VERSION "created by canmatrix"

NS_ :

BS_:

BU_: IPD

BO_ 1010 ICBVC_BKPCANFD_50ms_FrP13: 16 Vector__XXX
 SG_ IThreeDimnlDspReq : 15|2@0+ (1,0) [0|3] "null" IPD
 SG_ ISysFltRsn : 23|3@0+ (1,0) [0|7] "null" IPD
 SG_ IErrRespHODM : 24|1@0+ (1,0) [0|1] "null" IPD
 SG_ ISWSCnfmSwReq : 26|2@0+ (1,0) [0|3] "null" IPD
 SG_ IMirFoldCtrlResp : 31|3@0+ (1,0) [0|7] "null" IPD
 SG_ ITgtParkingChosed : 35|4@0+ (1,0) [0|15] "null" IPD
 SG_ ISpdLmtMdFICM : 37|2@0+ (1,0) [0|3] "null" IPD
 SG_ IAutocParkngSwReq : 39|2@0+ (1,0) [0|3] "null" IPD
 SG_ IIMATESysSts : 42|3@0+ (1,0) [0|7] "null" IPD
 SG_ ILampCtrlResp : 47|4@0+ (1,0) [0|15] "null" IPD
 SG_ IPwrMdCtrlResp : 58|3@0+ (1,0) [0|7] "null" IPD
 SG_ ILVSSts : 90|2@0+ (1,0) [0|3] "null" Vector__XXX
 SG_ IFrSsdManuCtrl : 92|2@0+ (1,0) [0|3] "null" Vector__XXX
 SG_ IPwrCtrlResp : 95|3@0+ (1,0) [0|7] "null" IPD

BO_ 591 ICBVC_BKPCANFD_50ms_FrP55: 12 Vector__XXX
 SG_ IDrvrFtgLvl : 15|3@0+ (1,0) [0|7] "null" IPD
 SG_ IDrvrPrsc : 23|3@0+ (1,0) [0|7] "null" IPD
 SG_ IIMATEysSts : 26|3@0+ (1,0) [0|7] "null" IPD
 SG_ IDrvrDstrctnSts : 31|3@0+ (1,0) [0|7] "null" IPD
 SG_ IDrvrAbnormBehvor : 39|4@0+ (1,0) [0|15] "null" IPD
 SG_ IDrvrGazeRgn : 47|5@0+ (1,0) [0|31] "null" IPD

BO_ 1301 ICBVC_BKPCANFD_Event_FrS06: 8 Vector__XXX
 SG_ IScurReqADS : 7|64@0+ (1,0) [0|18446744073709551615] "null" IPD

BO_ 1302 ICBVC_BKPCANFD_Event_FrS07: 8 Vector__XXX
 SG_ IDrvngScurResp : 7|64@0+ (1,0) [0|18446744073709551615] "null" IPD

BO_ 728 ICBVC_BKPCANFD_Event_FrS138: 24 Vector__XXX
 SG_ IParkingSubscribleStsreq : 39|64@0+ (1,0) [0|18446744073709551615] "null" IPD
 SG_ IPilotSubscribleStsreq : 103|64@0+ (1,0) [0|18446744073709551615] "null" IPD
 SG_ IAIParkngSpcIDICB : 167|8@0+ (1,0) [0|255] "null" IPD
 SG_ IRemParkngMapChosen : 175|8@0+ (1,0) [0|255] "null" IPD
 SG_ IAIParkngReqICB : 183|8@0+ (1,0) [0|255] "null" IPD
 SG_ IAIParkngScngAutocBtn : 191|4@0+ (1,0) [0|15] "null" IPD

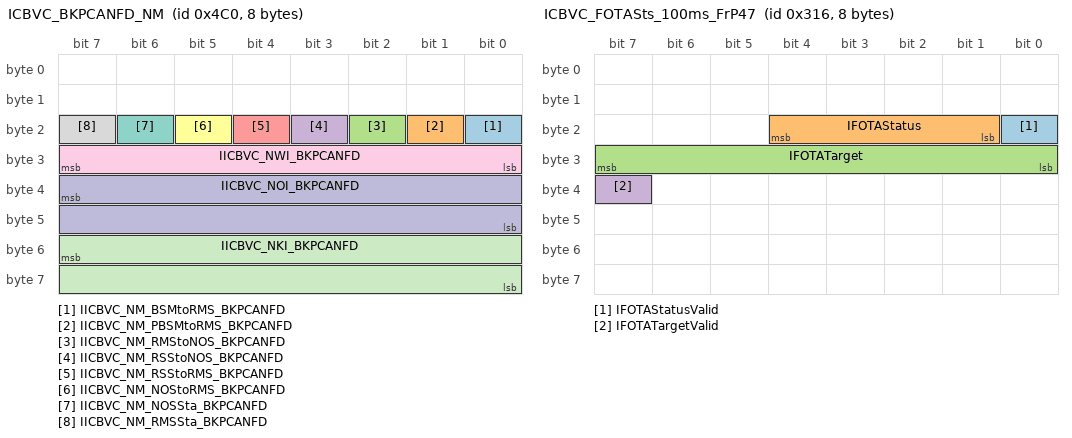
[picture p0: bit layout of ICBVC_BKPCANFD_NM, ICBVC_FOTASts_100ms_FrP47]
BO_ 1216 ICBVC_BKPCANFD_NM: 8 Vector__XXX
 SG_ IICBVC_NM_BSMtoRMS_BKPCANFD : 16|1@0+ (1,0) [0|1] "null" Vector__XXX
 SG_ IICBVC_NM_PBSMtoRMS_BKPCANFD : 17|1@0+ (1,0) [0|1] "null" Vector__XXX
 SG_ IICBVC_NM_RMStoNOS_BKPCANFD : 18|1@0+ (1,0) [0|1] "null" Vector__XXX
 SG_ IICBVC_NM_RSStoNOS_BKPCANFD : 19|1@0+ (1,0) [0|1] "null" Vector__XXX
 SG_ IICBVC_NM_RSStoRMS_BKPCANFD : 20|1@0+ (1,0) [0|1] "null" Vector__XXX
 SG_ IICBVC_NM_NOStoRMS_BKPCANFD : 21|1@0+ (1,0) [0|1] "null" Vector__XXX
 SG_ IICBVC_NM_NOSSta_BKPCANFD : 22|1@0+ (1,0) [0|1] "null" Vector__XXX
 SG_ IICBVC_NM_RMSSta_BKPCANFD : 23|1@0+ (1,0) [0|1] "null" Vector__XXX
 SG_ IICBVC_NWI_BKPCANFD : 31|8@0+ (1,0) [0|255] "null" Vector__XXX
 SG_ IICBVC_NOI_BKPCANFD : 39|16@0+ (1,0) [0|65535] "null" Vector__XXX
 SG_ IICBVC_NKI_BKPCANFD : 55|16@0+ (1,0) [0|65535] "null" Vector__XXX

BO_ 790 ICBVC_FOTASts_100ms_FrP47: 8 Vector__XXX
 SG_ IFOTAStatusValid : 16|1@0+ (1,0) [0|1] "null" IPD
 SG_ IFOTAStatus : 20|4@0+ (1,0) [0|15] "null" IPD
 SG_ IFOTATarget : 31|8@0+ (1,0) [0|255] "null" IPD
 SG_ IFOTATargetValid : 39|1@0+ (1,0) [0|1] "null" IPD

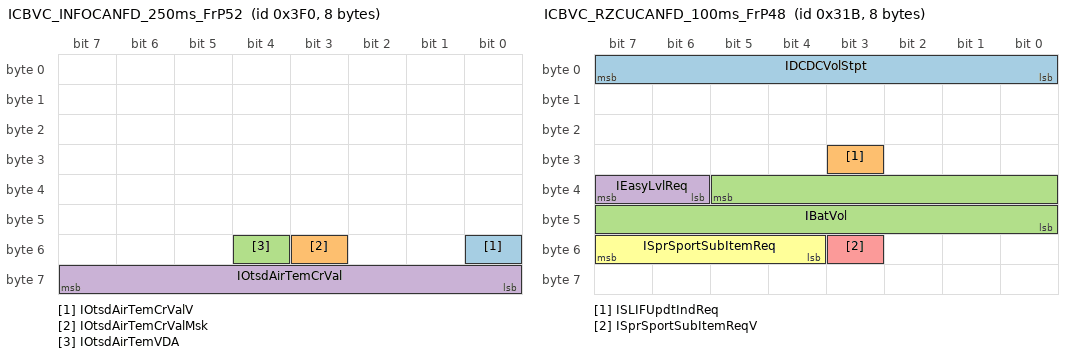
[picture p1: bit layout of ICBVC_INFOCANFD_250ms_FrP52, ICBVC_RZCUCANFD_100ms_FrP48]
BO_ 1008 ICBVC_INFOCANFD_250ms_FrP52: 8 Vector__XXX
 SG_ IOtsdAirTemCrValV : 48|1@0+ (1,0) [0|1] "null" IPD
 SG_ IOtsdAirTemCrValMsk : 51|1@0+ (1,0) [0|1] "null" IPD
 SG_ IOtsdAirTemVDA : 52|1@0+ (1,0) [0|1] "null" Vector__XXX
 SG_ IOtsdAirTemCrVal : 63|8@0+ (0.5,-40) [-40|87.5] "degreeCelsius" IPD

BO_ 1023 ICBVC_RZCUCANFD_100ms_FrP19: 8 Vector__XXX
 SG_ IRgnLvReqFICMV : 12|1@0+ (1,0) [0|1] "null" Vector__XXX
 SG_ IRgnLvReqFICM : 15|3@0+ (1,0) [0|7] "null" Vector__XXX
 SG_ ILVBatChrgReqRaw : 16|1@0+ (1,0) [0|1] "null" Vector__XXX
 SG_ ILVBatChrgReqInhbt : 17|1@0+ (1,0) [0|1] "null" Vector__XXX
 SG_ ILVBatEnrgSufct : 18|1@0+ (1,0) [0|1] "null" Vector__XXX
 SG_ ILVBatEnrgLow : 19|1@0+ (1,0) [0|1] "null" Vector__XXX
 SG_ IVehFOTAHVReq : 21|2@0+ (1,0) [0|3] "null" Vector__XXX
 SG_ IEnrgSplReqV : 22|1@0+ (1,0) [0|1] "null" Vector__XXX
 SG_ IEnrgSplReq : 23|1@0+ (1,0) [0|1] "null" Vector__XXX
 SG_ IPMDCSta : 27|4@0+ (1,0) [0|15] "null" Vector__XXX
 SG_ IEPMOprtMd : 31|4@0+ (1,0) [0|15] "null" Vector__XXX
 SG_ IVehFotaReq : 32|1@0+ (1,0) [0|1] "null" Vector__XXX
 SG_ IVehEnrgRdyLvlV : 36|1@0+ (1,0) [0|1] "null" IPD
 SG_ IVehEnrgRdyLvl : 39|3@0+ (1,0) [0|7] "null" IPD
 SG_ IEPTToqCustSetngReqV : 59|1@0+ (1,0) [0|1] "null" Vector__XXX
 SG_ IEPTToqCustSetngReq : 61|2@0+ (1,0) [0|3] "null" Vector__XXX
 SG_ ILVBatSelfWakeupFlg : 62|1@0+ (1,0) [0|1] "null" Vector__XXX
 SG_ IEnrgSplReqRaw : 63|1@0+ (1,0) [0|1] "null" Vector__XXX

BO_ 922 ICBVC_RZCUCANFD_100ms_FrP27: 8 Vector__XXX
 SG_ IAVMDspReq : 1|2@0+ (1,0) [0|3] "null" IPD
 SG_ IAutoViewChg : 2|1@0+ (1,0) [0|1] "null" IPD
 SG_ IAlisysrdy : 3|1@0+ (1,0) [0|1] "null" IPD
 SG_ ILiftMdReq : 5|2@0+ (1,0) [0|3] "null" Vector__XXX
 SG_ IEasyLdMdReq : 7|2@0+ (1,0) [0|3] "null" Vector__XXX
 SG_ IEasyEntMdReq : 9|2@0+ (1,0) [0|3] "null" Vector__XXX
 SG_ IEasyPssReq : 11|2@0+ (1,0) [0|3] "null" Vector__XXX
 SG_ IIEasyEntMdSetReq : 13|2@0+ (1,0) [0|3] "null" Vector__XXX
 SG_ IHDCReq : 15|2@0+ (1,0) [0|3] "null" Vector__XXX
 SG_ IEmmsnTestMdFICMV : 16|1@0+ (1,0) [0|1] "null" Vector__XXX
 SG_ ITrgtSOCReqFICM : 23|7@0+ (1,0) [0|127] "null" Vector__XXX
 SG_ ISusLvlCtrlCustSetngReq : 28|3@0+ (1,0) [0|7] "null" Vector__XXX
 SG_ IFICMPwrDMdReq : 31|3@0+ (1,0) [0|7] "null" Vector__XXX
 SG_ ICloseCalib : 35|4@0+ (1,0) [0|15] "null" IPD
 SG_ ICalibFunc : 39|4@0+ (1,0) [0|15] "null" IPD
 SG_ IFICMPwrDMdReqV : 40|1@0+ (1,0) [0|1] "null" Vector__XXX
 SG_ IEmmsnTestMdFICM : 41|1@0+ (1,0) [0|1] "null" Vector__XXX
 SG_ IVehSpdDpdntLvlCtrlReq : 43|2@0+ (1,0) [0|3] "m/s" Vector__XXX
 SG_ IBtmFilgDspReq : 47|2@0+ (1,0) [0|3] "null" IPD
 SG_ ISusDmpngCtrlCustSetngReq : 54|4@0+ (1,0) [0|15] "null" Vector__XXX
 SG_ ITrgtSOCReqFICMV : 55|1@0+ (1,0) [0|1] "null" Vector__XXX

BO_ 1006 ICBVC_RZCUCANFD_100ms_FrP44: 16 Vector__XXX
 SG_ INavGudcSts : 3|1@0+ (1,0) [0|1] "null" Vector__XXX
 SG_ IDsttnTypOfNav : 7|4@0+ (1,0) [0|15] "null" Vector__XXX
 SG_ IEPTSysCoolActvReq : 10|1@0+ (1,0) [0|1] "null" Vector__XXX
 SG_ IChrgngSttnCapctOfDsttnNav : 31|8@0+ (4,0) [0|1020] "kW" Vector__XXX
 SG_ IDistToDsttnNav : 43|10@0+ (0.1,0) [0|102.3] "km" IPD
 SG_ IElecEnrgAvgRstReq : 65|2@0+ (1,0) [0|3] "null" Vector__XXX
 SG_ IFICMOnRutWarmOffReqV : 66|1@0+ (1,0) [0|1] "null" Vector__XXX
 SG_ IFICMChrgCtrlReq : 68|2@0+ (1,0) [0|3] "null" Vector__XXX
 SG_ IFICMOnRouteWarmSwReq : 69|1@0+ (1,0) [0|1] "null" Vector__XXX
 SG_ IFICMOnRutWarmOffReq : 71|2@0+ (1,0) [0|3] "null" Vector__XXX
 SG_ IIPKSetVehEleclRngAlg : 74|1@0+ (1,0) [0|1] "null" Vector__XXX
 SG_ IFICMV2XReq : 91|2@0+ (1,0) [0|3] "null" Vector__XXX
 SG_ IFICMEleccLckCtrlReq : 95|2@0+ (1,0) [0|3] "null" Vector__XXX
 SG_ IGudTimeToDsttnNav : 103|12@0+ (1,0) [0|4095] "Min" Vector__XXX

BO_ 795 ICBVC_RZCUCANFD_100ms_FrP48: 8 Vector__XXX
 SG_ IDCDCVolStpt : 7|8@0+ (0.03125,8.5) [8.50000|16.46875] "V" Vector__XXX
 SG_ ISLIFUpdtIndReq : 27|1@0+ (1,0) [0|1] "null" IPD
 SG_ IBatVol : 37|14@0+ (0.00097656,3) [3.00000000|18.99898248] "V" Vector__XXX
 SG_ IEasyLvlReq : 39|2@0+ (1,0) [0|3] "null" Vector__XXX
 SG_ ISprSportSubItemReqV : 51|1@0+ (1,0) [0|1] "null" Vector__XXX
 SG_ ISprSportSubItemReq : 55|4@0+ (1,0) [0|15] "null" Vector__XXX

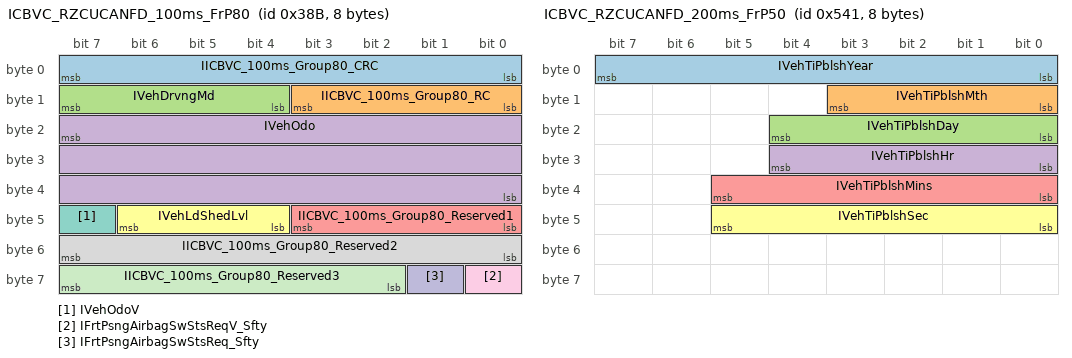
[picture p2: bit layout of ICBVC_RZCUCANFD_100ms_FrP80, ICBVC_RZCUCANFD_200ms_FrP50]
BO_ 907 ICBVC_RZCUCANFD_100ms_FrP80: 8 Vector__XXX
 SG_ IICBVC_100ms_Group80_CRC : 7|8@0+ (1,0) [0|255] "null" IPD
 SG_ IICBVC_100ms_Group80_RC : 11|4@0+ (1,0) [0|15] "null" IPD
 SG_ IVehDrvngMd : 15|4@0+ (1,0) [0|15] "null" IPD
 SG_ IVehOdo : 23|24@0+ (1,0) [0|16777215] "null" IPD
 SG_ IICBVC_100ms_Group80_Reserved1 : 43|4@0+ (1,0) [0|15] "null" IPD
 SG_ IVehLdShedLvl : 46|3@0+ (1,0) [0|7] "null" IPD
 SG_ IVehOdoV : 47|1@0+ (1,0) [0|1] "null" IPD
 SG_ IICBVC_100ms_Group80_Reserved2 : 55|8@0+ (1,0) [0|255] "null" IPD
 SG_ IFrtPsngAirbagSwStsReqV_Sfty : 56|1@0+ (1,0) [0|1] "null" IPD
 SG_ IFrtPsngAirbagSwStsReq_Sfty : 57|1@0+ (1,0) [0|1] "null" IPD
 SG_ IICBVC_100ms_Group80_Reserved3 : 63|6@0+ (1,0) [0|63] "null" IPD

BO_ 1345 ICBVC_RZCUCANFD_200ms_FrP50: 8 Vector__XXX
 SG_ IVehTiPblshYear : 7|8@0+ (1,2000) [2000|2255] "year" IPD
 SG_ IVehTiPblshMth : 11|4@0+ (1,0) [0|15] "null" IPD
 SG_ IVehTiPblshDay : 20|5@0+ (1,0) [0|31] "days" IPD
 SG_ IVehTiPblshHr : 28|5@0+ (1,0) [0|31] "hour" IPD
 SG_ IVehTiPblshMins : 37|6@0+ (1,0) [0|63] "minute" IPD
 SG_ IVehTiPblshSec : 45|6@0+ (1,0) [0|63] "second" IPD

BO_ 361 ICBVC_RZCUCANFD_20ms_FrP00: 8 Vector__XXX
 SG_ INFCAMAvlbly : 2|1@0+ (1,0) [0|1] "null" Vector__XXX
 SG_ ISDMAvlbly : 5|1@0+ (1,0) [0|1] "null" Vector__XXX
 SG_ IRHZCUAvlbly : 6|1@0+ (1,0) [0|1] "null" IPD
 SG_ ILHZCUAvlbly : 7|1@0+ (1,0) [0|1] "null" IPD
 SG_ ITC_ExtdAvlbly : 8|1@0+ (1,0) [0|1] "null" Vector__XXX
 SG_ IIBS_SFAvlbly : 9|1@0+ (1,0) [0|1] "null" Vector__XXX
 SG_ IEPSAvlbly : 10|1@0+ (1,0) [0|1] "null" Vector__XXX
 SG_ ITC_PTAvlbly : 12|1@0+ (1,0) [0|1] "null" Vector__XXX
 SG_ IPICU_PTAvlbly : 13|1@0+ (1,0) [0|1] "null" Vector__XXX
 SG_ IPEU_PTAvlbly : 16|1@0+ (1,0) [0|1] "null" Vector__XXX
 SG_ IPEU_ERAvlbly : 17|1@0+ (1,0) [0|1] "null" Vector__XXX
 SG_ IPICU_ExtdAvlbly : 18|1@0+ (1,0) [0|1] "null" Vector__XXX
 SG_ ILHRDAAvlbly : 19|1@0+ (1,0) [0|1] "null" Vector__XXX
 SG_ IIPD_PTAvlbly : 20|1@0+ (1,0) [0|1] "null" Vector__XXX
 SG_ IESS_PTAvlbly : 22|1@0+ (1,0) [0|1] "null" IPD
 SG_ ICCU_ExtdAvlbly : 23|1@0+ (1,0) [0|1] "null" Vector__XXX
 SG_ IESS_ExtdAvlbly : 24|1@0+ (1,0) [0|1] "null" Vector__XXX
 SG_ ICCU_PTAvlbly : 25|1@0+ (1,0) [0|1] "null" Vector__XXX
 SG_ IIAMAvlbly : 26|1@0+ (1,0) [0|1] "null" IPD
 SG_ IEAC_Avlbly : 27|1@0+ (1,0) [0|1] "null" Vector__XXX
 SG_ IIPD_SFAvlbly : 33|1@0+ (1,0) [0|1] "null" Vector__XXX
 SG_ ICCEOPAvlbly : 38|1@0+ (1,0) [0|1] "null" Vector__XXX
 SG_ IRZCU_BKBCANFDAvlbly : 39|1@0+ (1,0) [0|1] "null" IPD
 SG_ IIPD_BKPCANFDAvlbly : 40|1@0+ (1,0) [0|1] "null" Vector__XXX
 SG_ IIPD_CHCANFDAvlbly : 41|1@0+ (1,0) [0|1] "null" Vector__XXX
 SG_ IIBS_CHAvlbly : 43|1@0+ (1,0) [0|1] "null" Vector__XXX
 SG_ IFDRAvlbly : 44|1@0+ (1,0) [0|1] "null" Vector__XXX
 SG_ IRHRDAAvlbly : 49|1@0+ (1,0) [0|1] "null" Vector__XXX
 SG_ IFVCMAvlbly : 51|1@0+ (1,0) [0|1] "null" Vector__XXX
 SG_ ITPMSAvlbly : 63|1@0+ (1,0) [0|1] "null" Vector__XXX

BO_ 497 ICBVC_RZCUCANFD_20ms_FrP03: 8 Vector__XXX
 SG_ IICBVC_20ms_Group03_CRC : 7|8@0+ (1,0) [0|255] "null" IPD
 SG_ IICBVC_20ms_Group03_RC : 11|4@0+ (1,0) [0|15] "null" IPD
 SG_ IAMRPrtensonReq : 15|4@0+ (1,0) [0|15] "null" IPD
 SG_ IICBVC_20ms_Group03_Reserved2 : 19|4@0+ (1,0) [0|15] "null" IPD
 SG_ ISysVolMdV : 20|1@0+ (1,0) [0|1] "null" IPD
 SG_ IICBVC_20ms_Group03_Reserved1 : 23|3@0+ (1,0) [0|7] "null" IPD
 SG_ IICBVC_20ms_Group03_Reserved3 : 27|4@0+ (1,0) [0|15] "null" IPD
 SG_ IVehMd : 31|4@0+ (1,0) [0|15] "null" IPD
 SG_ ISysVolV : 32|1@0+ (1,0) [0|1] "null" IPD
 SG_ ISysPwrMdV : 33|1@0+ (1,0) [0|1] "null" IPD
 SG_ IVehMdV : 34|1@0+ (1,0) [0|1] "null" IPD
 SG_ IUsgMdV : 35|1@0+ (1,0) [0|1] "null" IPD
 SG_ IUsgMd : 39|4@0+ (1,0) [0|15] "null" IPD
 SG_ ISysVol : 47|8@0+ (0.1,3) [3|28.5] "V" IPD
 SG_ IPwrMdMstrRunCrkA : 48|1@0+ (1,0) [0|1] "null" IPD
 SG_ ISysPwrMd : 50|2@0+ (1,0) [0|3] "null" IPD
 SG_ IPwrMdMstrAccryA : 51|1@0+ (1,0) [0|1] "null" IPD
 SG_ ISysOpnlMd : 55|4@0+ (1,0) [0|15] "null" IPD
 SG_ IICBVC_20ms_Group03_Reserved4 : 60|5@0+ (1,0) [0|31] "null" IPD
 SG_ IBPMMstrAvlbly : 61|1@0+ (1,0) [0|1] "null" IPD
 SG_ ISysVolMd : 63|2@0+ (1,0) [0|3] "null" IPD

BO_ 60 ICBVC_SecOC_ComKeyReq: 8 Vector__XXX
 SG_ ITripCntResetReq : 6|1@0+ (1,0) [0|1] "null" IPD
 SG_ IComKeyEnbReq : 7|1@0+ (1,0) [0|1] "null" IPD

BO_ 1391 ICBVC_SecOC_SyncMsg: 8 Vector__XXX
 SG_ ITripCnt : 7|24@0+ (1,0) [0|16777215] "null" IPD
 SG_ IResetCnt : 31|16@0+ (1,0) [0|65535] "null" IPD

BO_ 815 ICB_BKBCANFD_100ms_FrP146: 8 Vector__XXX
 SG_ IEGCMPwrSts : 16|1@0+ (1,0) [0|1] "null" Vector__XXX
 SG_ IESCLPwrSts : 20|1@0+ (1,0) [0|1] "null" IPD
 SG_ IBPEPSPwrSts : 25|1@0+ (1,0) [0|1] "null" Vector__XXX
 SG_ IRoofDspPwrSts : 28|1@0+ (1,0) [0|1] "null" Vector__XXX
 SG_ ILHAmbtLampPwrSts : 30|1@0+ (1,0) [0|1] "null" Vector__XXX
 SG_ IOHCPwrSts : 31|1@0+ (1,0) [0|1] "null" Vector__XXX
 SG_ ICnsoDspPwrSts : 33|1@0+ (1,0) [0|1] "null" Vector__XXX
 SG_ IFLVntngMotPwrSts : 34|1@0+ (1,0) [0|1] "null" Vector__XXX
 SG_ IFLSLMMPwrSts : 35|1@0+ (1,0) [0|1] "null" Vector__XXX
 SG_ IUSBHubPwrSts : 36|1@0+ (1,0) [0|1] "null" Vector__XXX
 SG_ IDrvrDspPwrSts : 37|1@0+ (1,0) [0|1] "null" Vector__XXX
 SG_ ISWSPwrSts : 38|1@0+ (1,0) [0|1] "null" Vector__XXX
 SG_ IBrkSwPwrSts : 39|1@0+ (1,0) [0|1] "null" Vector__XXX
 SG_ IHODMPwrSts : 40|1@0+ (1,0) [0|1] "null" Vector__XXX
 SG_ IRLSSPwrSts : 42|1@0+ (1,0) [0|1] "null" Vector__XXX
 SG_ IETCMPwrSts : 43|1@0+ (1,0) [0|1] "null" Vector__XXX
 SG_ ILHSWPwrSts : 44|1@0+ (1,0) [0|1] "null" Vector__XXX
 SG_ INFCAMPwrSts : 45|1@0+ (1,0) [0|1] "null" Vector__XXX
 SG_ INFCSMPwrSts : 46|1@0+ (1,0) [0|1] "null" Vector__XXX
 SG_ IPriEarPwrSts : 48|1@0+ (1,0) [0|1] "null" Vector__XXX
 SG_ ICnsoUSBPwrSts : 50|1@0+ (1,0) [0|1] "null" Vector__XXX
 SG_ IRrPDCPwrSts : 51|1@0+ (1,0) [0|1] "null" Vector__XXX
 SG_ IFrtPDCPwrSts : 52|1@0+ (1,0) [0|1] "null" Vector__XXX
 SG_ IFVCMPwrSts : 55|1@0+ (1,0) [0|1] "null" Vector__XXX
 SG_ IHVDCDCPwrSts : 56|1@0+ (1,0) [0|1] "null" Vector__XXX
 SG_ ITPMSPwrSts : 57|1@0+ (1,0) [0|1] "null" Vector__XXX
 SG_ IAIBOXPwrSts : 58|1@0+ (1,0) [0|1] "null" Vector__XXX
 SG_ IAIBOTPwrSts : 59|1@0+ (1,0) [0|1] "null" Vector__XXX

BO_ 902 ICB_BKBCANFD_100ms_FrP221: 24 Vector__XXX
 SG_ IDircnLghtMdSet : 13|2@0+ (1,0) [0|3] "null" Vector__XXX
 SG_ IComfortDircnLghtSet : 15|2@0+ (1,0) [0|3] "null" Vector__XXX
 SG_ ILbl1FrgrLife : 23|8@0+ (1,0) [0|255] "Percent" Vector__XXX
 SG_ ILbl2FrgrLife : 31|8@0+ (1,0) [0|255] "Percent" Vector__XXX
 SG_ ILbl3FrgrLife : 39|8@0+ (1,0) [0|255] "Percent" Vector__XXX
 SG_ ILbl1FrgrAvlbl : 47|8@0+ (1,0) [0|255] "null" Vector__XXX
 SG_ ILbl2FrgrAvlbl : 55|8@0+ (1,0) [0|255] "null" Vector__XXX
 SG_ ILbl3FrgrAvlbl : 63|8@0+ (1,0) [0|255] "null" Vector__XXX
 SG_ IAVPMapRutMgIDtReq : 71|10@0+ (1,0) [0|1023] "null" IPD
 SG_ IFrgrLblReqRut : 77|4@0+ (1,0) [0|15] "null" Vector__XXX
 SG_ IAdupConSwReq : 81|2@0+ (1,0) [0|3] "null" IPD
 SG_ IAdupSwReq : 83|2@0+ (1,0) [0|3] "null" IPD
 SG_ IRBFSwReq : 85|2@0+ (1,0) [0|3] "null" IPD
 SG_ IRCWSnstvtLvlReq : 87|2@0+ (1,0) [0|3] "null" IPD
 SG_ ISpdLmtCotOverWrnngSwReq : 89|2@0+ (1,0) [0|3] "null" IPD
 SG_ ITollgatePreReq : 91|2@0+ (1,0) [0|3] "null" IPD
 SG_ IHODMdlReq : 93|2@0+ (1,0) [0|3] "null" IPD
 SG_ IMemParkngSilentPatrolSwReq : 95|2@0+ (1,0) [0|3] "null" IPD
 SG_ IIPDPowerFailSwReq : 97|2@0+ (1,0) [0|3] "null" IPD
 SG_ IAVPUpdateMapReq : 99|2@0+ (1,0) [0|3] "null" IPD
 SG_ IAVPMapRutMgtReq : 101|2@0+ (1,0) [0|3] "null" IPD
 SG_ IAIPilotMdlReq : 103|2@0+ (1,0) [0|3] "null" IPD
 SG_ ILbl1FrgrExpiryFlg : 104|1@0+ (1,0) [0|1] "null" Vector__XXX
 SG_ IRPAActMethSwReq : 106|2@0+ (1,0) [0|3] "null" IPD
 SG_ IUsPrReportReq : 108|2@0+ (1,0) [0|3] "null" IPD
 SG_ IRACtlReq : 111|3@0+ (1,0) [0|7] "null" IPD
 SG_ IDriverSightDstrctnMonWarning : 115|4@0+ (1,0) [0|15] "null" IPD
 SG_ IFatigueMonitorWarning : 119|4@0+ (1,0) [0|15] "null" IPD
 SG_ IFrgrCncntrnReqRut : 124|4@0+ (1,0) [0|15] "null" Vector__XXX
 SG_ IShwrmComprEnbReq : 125|1@0+ (1,0) [0|1] "null" Vector__XXX
 SG_ ILbl3FrgrExpiryFlg : 126|1@0+ (1,0) [0|1] "null" Vector__XXX
 SG_ ILbl2FrgrExpiryFlg : 127|1@0+ (1,0) [0|1] "null" Vector__XXX
 SG_ ISrfOpenSts : 140|3@0+ (1,0) [0|7] "null" Vector__XXX

BO_ 955 ICB_BKPCANFD_100ms_FrP159: 24 Vector__XXX
 SG_ IACCTJAMdSwReq : 18|3@0+ (1,0) [0|7] "null" IPD
 SG_ IFICMACLTemReq : 23|5@0+ (0.5,15.5) [15.5|31] "null" Vector__XXX
 SG_ ISpdLmtOfstSetReq : 31|6@0+ (1,-20) [-20|43] "null" IPD
 SG_ IACCStsSwReq : 33|2@0+ (1,0) [0|3] "null" IPD
 SG_ IACCSpdLimtSwReq : 35|2@0+ (1,0) [0|3] "null" IPD
 SG_ IACCConfmSwReq : 39|2@0+ (1,0) [0|3] "null" IPD
 SG_ IACUserCustEcoSetngReqV : 40|1@0+ (1,0) [0|1] "null" Vector__XXX
 SG_ IACUserCustEcoSetngReq : 42|2@0+ (1,0) [0|3] "null" Vector__XXX
 SG_ IACUserCustAutoMdBlwrReqV : 43|1@0+ (1,0) [0|1] "null" Vector__XXX
 SG_ IACUserCustAutoMdBlwrReq : 45|2@0+ (1,0) [0|3] "null" Vector__XXX
 SG_ IACUserCustAftRunOnOffReqV : 46|1@0+ (1,0) [0|1] "null" Vector__XXX
 SG_ IACUserCustAftRunOnOffR : 47|1@0+ (1,0) [0|1] "null" Vector__XXX
 SG_ IFICMACFrtBlwrSpdDecSwR : 49|2@0+ (1,0) [0|3] "null" Vector__XXX
 SG_ IFICMACAutoSwReq : 51|2@0+ (1,0) [0|3] "null" Vector__XXX
 SG_ IFICMACLTemDecSwReq : 57|2@0+ (1,0) [0|3] "null" Vector__XXX
 SG_ IFICMACFrtBlwrSpdIncSwR : 59|2@0+ (1,0) [0|3] "null" Vector__XXX
 SG_ IFICMACFrtBlwrLvlReq : 63|4@0+ (1,0) [0|15] "null" Vector__XXX
 SG_ IFICMACOnOffSwReq : 65|2@0+ (1,0) [0|3] "null" Vector__XXX
 SG_ IFICMACLTemIncSwReq : 67|2@0+ (1,0) [0|3] "null" Vector__XXX
 SG_ IFICMACLAirMdReqV : 68|1@0+ (1,0) [0|1] "null" Vector__XXX
 SG_ IFICMACLAirMdReq : 71|3@0+ (1,0) [0|7] "null" Vector__XXX
 SG_ IFICMComprOnOffSwReq : 73|2@0+ (1,0) [0|3] "null" Vector__XXX
 SG_ IFICMACSemiAutoSwReq : 75|2@0+ (1,0) [0|3] "null" Vector__XXX
 SG_ IFICMACRcctnSwReq : 77|2@0+ (1,0) [0|3] "null" Vector__XXX
 SG_ IFICMACRcctnMdReq : 79|2@0+ (1,0) [0|3] "null" Vector__XXX
 SG_ IFICMHtdRrWndSwReq : 81|2@0+ (1,0) [0|3] "null" Vector__XXX
 SG_ IFICMDfstOnSwReq : 83|2@0+ (1,0) [0|3] "null" Vector__XXX
 SG_ IFICMACLTemV : 87|1@0+ (1,0) [0|1] "null" Vector__XXX
 SG_ ITLRMdSwReq : 90|3@0+ (1,0) [0|7] "null" IPD
 SG_ ITSRSwReq : 97|2@0+ (1,0) [0|3] "null" IPD
 SG_ ISpdLmtOfstSetNumReq : 103|4@0+ (1,0) [0|15] "null" IPD
 SG_ IILCSwReq : 108|2@0+ (1,0) [0|3] "null" IPD
 SG_ ISpdLmtOfstSetPercReq : 127|3@0+ (1,0) [0|7] "null" IPD

BA_DEF_ BO_ "FrameTriggeringName" STRING;
BA_DEF_ BO_ "GenMsgCycleTime" INT 0 65535;
BA_DEF_ BO_ "GenMsgDelayTime" INT 0 65535;
BA_DEF_ BO_ "GenMsgSendType" ENUM  "cyclicX","spontanX","cyclicIfActiveX","spontanWithDelay","cyclicAndSpontanX","cyclicAndSpontanWithDelay","spontanWithRepitition","cyclicIfActiveAndSpontanWD","cyclicIfActiveFast","cyclicWithRepeatOnDemand","none";
BA_DEF_ BO_ "GenMsgStartValue" STRING;
BA_DEF_ BO_ "PduName" STRING;
BA_DEF_ BO_ "VFrameFormat" ENUM  "StandardCAN","ExtendedCAN","reserved","reserved","reserved","reserved","reserved","reserved","reserved","reserved","reserved","reserved","reserved","reserved","StandardCAN_FD","ExtendedCAN_FD";
BA_DEF_ SG_ "CompuMethodName" STRING;
BA_DEF_ SG_ "GenSigStartValue" FLOAT 0 100000000000;
BA_DEF_ SG_ "ISignalName" STRING;
BA_DEF_ SG_ "LongName" STRING;
BA_DEF_ SG_ "SysSignalName" STRING;
BA_DEF_ SG_ "SystemSignalLongSymbol" STRING;
BA_ "FrameTriggeringName" BO_ 1010 "ICBVC_BKPCANFD_50ms_FrP13";
BA_ "GenMsgCycleTime" BO_ 1010 50;
BA_ "GenMsgSendType" BO_ 1010 0;
BA_ "GenMsgStartValue" BO_ 1010 "00000002000000000000000000000000";
BA_ "PduName" BO_ 1010 "ICBVC_50ms_PDU13";
BA_ "VFrameFormat" BO_ 1010 14;
BA_ "FrameTriggeringName" BO_ 591 "ICBVC_BKPCANFD_50ms_FrP55";
BA_ "GenMsgCycleTime" BO_ 591 50;
BA_ "GenMsgSendType" BO_ 591 0;
BA_ "GenMsgStartValue" BO_ 591 "000000000000000000000000";
BA_ "PduName" BO_ 591 "ICBVC_50ms_PDU55";
BA_ "VFrameFormat" BO_ 591 14;
BA_ "FrameTriggeringName" BO_ 1301 "ICBVC_BKPCANFD_Event_FrS06";
BA_ "GenMsgSendType" BO_ 1301 1;
BA_ "GenMsgStartValue" BO_ 1301 "0000000000000000";
BA_ "PduName" BO_ 1301 "ICBVC_Sporadic_PDU06";
BA_ "VFrameFormat" BO_ 1301 14;
BA_ "FrameTriggeringName" BO_ 1302 "ICBVC_BKPCANFD_Event_FrS07";
BA_ "GenMsgSendType" BO_ 1302 1;
BA_ "GenMsgStartValue" BO_ 1302 "0000000000000000";
BA_ "PduName" BO_ 1302 "ICBVC_Sporadic_PDU07";
BA_ "VFrameFormat" BO_ 1302 14;
BA_ "FrameTriggeringName" BO_ 728 "ICBVC_BKPCANFD_Event_FrS138";
BA_ "GenMsgSendType" BO_ 728 1;
BA_ "GenMsgStartValue" BO_ 728 "000000000000000000000000000000000000000000000000";
BA_ "PduName" BO_ 728 "ICBVC_Sporadic_PDU138";
BA_ "VFrameFormat" BO_ 728 14;
BA_ "FrameTriggeringName" BO_ 1216 "ICBVC_BKPCANFD_NM";
BA_ "GenMsgSendType" BO_ 1216 1;
BA_ "GenMsgStartValue" BO_ 1216 "0000000000000000";
BA_ "PduName" BO_ 1216 "NmPDU_BKPCANFD_ICBVC";
BA_ "VFrameFormat" BO_ 1216 14;
BA_ "FrameTriggeringName" BO_ 790 "ICBVC_FOTASts_100ms_FrP47";
BA_ "GenMsgCycleTime" BO_ 790 100;
BA_ "GenMsgSendType" BO_ 790 0;
BA_ "GenMsgStartValue" BO_ 790 "0000010080000000";
BA_ "PduName" BO_ 790 "ICBVC_100ms_PDU47";
BA_ "VFrameFormat" BO_ 790 14;
BA_ "FrameTriggeringName" BO_ 1008 "ICBVC_INFOCANFD_250ms_FrP52";
BA_ "GenMsgCycleTime" BO_ 1008 250;
BA_ "GenMsgSendType" BO_ 1008 0;
BA_ "GenMsgStartValue" BO_ 1008 "0000000000000100";
BA_ "PduName" BO_ 1008 "ICBVC_250ms_PDU52";
BA_ "VFrameFormat" BO_ 1008 14;
BA_ "FrameTriggeringName" BO_ 1023 "ICBVC_RZCUCANFD_100ms_FrP19";
BA_ "GenMsgCycleTime" BO_ 1023 100;
BA_ "GenMsgSendType" BO_ 1023 0;
BA_ "GenMsgStartValue" BO_ 1023 "0030480020000028";
BA_ "PduName" BO_ 1023 "ICBVC_100ms_PDU19";
BA_ "VFrameFormat" BO_ 1023 14;
BA_ "FrameTriggeringName" BO_ 922 "ICBVC_RZCUCANFD_100ms_FrP27";
BA_ "GenMsgCycleTime" BO_ 922 100;
BA_ "GenMsgSendType" BO_ 922 0;
BA_ "GenMsgStartValue" BO_ 922 "0000010000018000";
BA_ "PduName" BO_ 922 "ICBVC_100ms_PDU27";
BA_ "VFrameFormat" BO_ 922 14;
BA_ "FrameTriggeringName" BO_ 1006 "ICBVC_RZCUCANFD_100ms_FrP44";
BA_ "GenMsgCycleTime" BO_ 1006 100;
BA_ "GenMsgSendType" BO_ 1006 0;
BA_ "GenMsgStartValue" BO_ 1006 "00000000000ffc000400000000000000";
BA_ "PduName" BO_ 1006 "ICBVC_100ms_PDU44";
BA_ "VFrameFormat" BO_ 1006 14;
BA_ "FrameTriggeringName" BO_ 795 "ICBVC_RZCUCANFD_100ms_FrP48";
BA_ "GenMsgCycleTime" BO_ 795 100;
BA_ "GenMsgSendType" BO_ 795 0;
BA_ "GenMsgStartValue" BO_ 795 "fe00000000000000";
BA_ "PduName" BO_ 795 "ICBVC_100ms_PDU48";
BA_ "VFrameFormat" BO_ 795 14;
BA_ "FrameTriggeringName" BO_ 907 "ICBVC_RZCUCANFD_100ms_FrP80";
BA_ "GenMsgCycleTime" BO_ 907 100;
BA_ "GenMsgSendType" BO_ 907 0;
BA_ "GenMsgStartValue" BO_ 907 "00000000008ffffc";
BA_ "PduName" BO_ 907 "ICBVC_100ms_PDU80";
BA_ "VFrameFormat" BO_ 907 14;
BA_ "FrameTriggeringName" BO_ 1345 "ICBVC_RZCUCANFD_200ms_FrP50";
BA_ "GenMsgCycleTime" BO_ 1345 200;
BA_ "GenMsgSendType" BO_ 1345 0;
BA_ "GenMsgStartValue" BO_ 1345 "1700000000000000";
BA_ "PduName" BO_ 1345 "ICBVC_200ms_PDU50";
BA_ "VFrameFormat" BO_ 1345 14;
BA_ "FrameTriggeringName" BO_ 361 "ICBVC_RZCUCANFD_20ms_FrP00";
BA_ "GenMsgCycleTime" BO_ 361 20;
BA_ "GenMsgSendType" BO_ 361 0;
BA_ "GenMsgStartValue" BO_ 361 "0000000000000000";
BA_ "PduName" BO_ 361 "ICBVC_20ms_PDU00";
BA_ "VFrameFormat" BO_ 361 14;
BA_ "FrameTriggeringName" BO_ 497 "ICBVC_RZCUCANFD_20ms_FrP03";
BA_ "GenMsgCycleTime" BO_ 497 20;
BA_ "GenMsgSendType" BO_ 497 0;
BA_ "GenMsgStartValue" BO_ 497 "0000ff0f1200001f";
BA_ "PduName" BO_ 497 "ICBVC_20ms_PDU03";
BA_ "VFrameFormat" BO_ 497 14;
BA_ "FrameTriggeringName" BO_ 60 "ICBVC_SecOC_ComKeyReq";
BA_ "GenMsgSendType" BO_ 60 1;
BA_ "GenMsgStartValue" BO_ 60 "0000000000000000";
BA_ "PduName" BO_ 60 "ICBVC_SecOCComKeyReq_PDU01";
BA_ "VFrameFormat" BO_ 60 14;
BA_ "FrameTriggeringName" BO_ 1391 "ICBVC_SecOC_SyncMsg";
BA_ "GenMsgSendType" BO_ 1391 1;
BA_ "GenMsgStartValue" BO_ 1391 "0000010001000000";
BA_ "PduName" BO_ 1391 "ICBVC_SecOC_SyncMsg";
BA_ "VFrameFormat" BO_ 1391 14;
BA_ "FrameTriggeringName" BO_ 815 "ICB_BKBCANFD_100ms_FrP146";
BA_ "GenMsgCycleTime" BO_ 815 100;
BA_ "GenMsgSendType" BO_ 815 0;
BA_ "GenMsgStartValue" BO_ 815 "0000000000000000";
BA_ "PduName" BO_ 815 "ICB_100ms_PDU146";
BA_ "VFrameFormat" BO_ 815 14;
BA_ "FrameTriggeringName" BO_ 902 "ICB_BKBCANFD_100ms_FrP221";
BA_ "GenMsgCycleTime" BO_ 902 100;
BA_ "GenMsgSendType" BO_ 902 0;
BA_ "GenMsgStartValue" BO_ 902 "0000ffffff00000000000000000000000010000000000000";
BA_ "PduName" BO_ 902 "ICB_100ms_PDU221";
BA_ "VFrameFormat" BO_ 902 14;
BA_ "FrameTriggeringName" BO_ 955 "ICB_BKPCANFD_100ms_FrP159";
BA_ "GenMsgCycleTime" BO_ 955 100;
BA_ "GenMsgSendType" BO_ 955 0;
BA_ "GenMsgStartValue" BO_ 955 "0000f8fc00590000f0008000000000000000000000000000";
BA_ "PduName" BO_ 955 "ICB_100ms_PDU159";
BA_ "VFrameFormat" BO_ 955 14;
BA_ "CompuMethodName" SG_ 1010 IThreeDimnlDspReq "ThreeDimnlDspReq";
BA_ "ISignalName" SG_ 1010 IThreeDimnlDspReq "IThreeDimnlDspReq";
BA_ "LongName" SG_ 1010 IThreeDimnlDspReq "Three_Dimensional_Display_Request";
BA_ "SysSignalName" SG_ 1010 IThreeDimnlDspReq "ThreeDimnlDspReq";
BA_ "CompuMethodName" SG_ 1010 ISysFltRsn "SysFltRsn";
BA_ "ISignalName" SG_ 1010 ISysFltRsn "ISysFltRsn";
BA_ "LongName" SG_ 1010 ISysFltRsn "System Fault Reason";
BA_ "SysSignalName" SG_ 1010 ISysFltRsn "SysFltRsn";
BA_ "CompuMethodName" SG_ 1010 IErrRespHODM "ErrRespHODM";
BA_ "ISignalName" SG_ 1010 IErrRespHODM "IErrRespHODM";
BA_ "LongName" SG_ 1010 IErrRespHODM "Error_Response_HODM";
BA_ "SysSignalName" SG_ 1010 IErrRespHODM "ErrRespHODM";
BA_ "CompuMethodName" SG_ 1010 ISWSCnfmSwReq "SWSCnfmSwReq";
BA_ "GenSigStartValue" SG_ 1010 ISWSCnfmSwReq 1;
BA_ "ISignalName" SG_ 1010 ISWSCnfmSwReq "ISWSCnfmSwReq";
BA_ "LongName" SG_ 1010 ISWSCnfmSwReq "Steering_Wheel_Switch_Confirm_Switch_Request";
BA_ "SysSignalName" SG_ 1010 ISWSCnfmSwReq "SWSCnfmSwReq";
BA_ "CompuMethodName" SG_ 1010 IMirFoldCtrlResp "MirFoldCtrlResp";
BA_ "ISignalName" SG_ 1010 IMirFoldCtrlResp "IMirFoldCtrlResp";
BA_ "LongName" SG_ 1010 IMirFoldCtrlResp "Mirror fold control Response";
BA_ "SysSignalName" SG_ 1010 IMirFoldCtrlResp "MirFoldCtrlResp";
BA_ "CompuMethodName" SG_ 1010 ITgtParkingChosed "TgtParkingChosed";
BA_ "ISignalName" SG_ 1010 ITgtParkingChosed "ITgtParkingChosed";
BA_ "LongName" SG_ 1010 ITgtParkingChosed "Target_Parking_Chosed";
BA_ "SysSignalName" SG_ 1010 ITgtParkingChosed "TgtParkingChosed";
BA_ "CompuMethodName" SG_ 1010 ISpdLmtMdFICM "SpdLmtMdFICM";
BA_ "ISignalName" SG_ 1010 ISpdLmtMdFICM "ISpdLmtMdFICM";
BA_ "LongName" SG_ 1010 ISpdLmtMdFICM "Speed_Limit_Mode_Front_Infotainment_Control_Module";
BA_ "SysSignalName" SG_ 1010 ISpdLmtMdFICM "SpdLmtMdFICM";
BA_ "CompuMethodName" SG_ 1010 IAutocParkngSwReq "AutocParkngSwReq";
BA_ "ISignalName" SG_ 1010 IAutocParkngSwReq "IAutocParkngSwReq";
BA_ "LongName" SG_ 1010 IAutocParkngSwReq "Auto Parking Switch Request";
BA_ "SysSignalName" SG_ 1010 IAutocParkngSwReq "AutocParkngSwReq";
BA_ "CompuMethodName" SG_ 1010 IIMATESysSts "IMATESysSts";
BA_ "ISignalName" SG_ 1010 IIMATESysSts "IIMATESysSts";
BA_ "LongName" SG_ 1010 IIMATESysSts "Imate System Status";
BA_ "SysSignalName" SG_ 1010 IIMATESysSts "IMATESysSts";
BA_ "CompuMethodName" SG_ 1010 ILampCtrlResp "LampCtrlResp";
BA_ "ISignalName" SG_ 1010 ILampCtrlResp "ILampCtrlResp";
BA_ "LongName" SG_ 1010 ILampCtrlResp "Lamp control Response";
BA_ "SysSignalName" SG_ 1010 ILampCtrlResp "LampCtrlResp";
BA_ "CompuMethodName" SG_ 1010 IPwrMdCtrlResp "PwrMdCtrlResp";
BA_ "ISignalName" SG_ 1010 IPwrMdCtrlResp "IPwrMdCtrlResp";
BA_ "LongName" SG_ 1010 IPwrMdCtrlResp "Power mode control Response";
BA_ "SysSignalName" SG_ 1010 IPwrMdCtrlResp "PwrMdCtrlResp";
BA_ "CompuMethodName" SG_ 1010 ILVSSts "LVSSts";
BA_ "ISignalName" SG_ 1010 ILVSSts "ILVSSts";
BA_ "LongName" SG_ 1010 ILVSSts "Local_Vehicle_Start_Status";
BA_ "SysSignalName" SG_ 1010 ILVSSts "LVSSts";
BA_ "CompuMethodName" SG_ 1010 IFrSsdManuCtrl "FrSsdManuCtrl";
BA_ "ISignalName" SG_ 1010 IFrSsdManuCtrl "IFrSsdManuCtrl";
BA_ "LongName" SG_ 1010 IFrSsdManuCtrl "Front_Sunshade_Manual_Control";
BA_ "SysSignalName" SG_ 1010 IFrSsdManuCtrl "FrSsdManuCtrl";
BA_ "CompuMethodName" SG_ 1010 IPwrCtrlResp "PwrCtrlResp";
BA_ "ISignalName" SG_ 1010 IPwrCtrlResp "IPwrCtrlResp";
BA_ "LongName" SG_ 1010 IPwrCtrlResp "Power control Response";
BA_ "SysSignalName" SG_ 1010 IPwrCtrlResp "PwrCtrlResp";
BA_ "CompuMethodName" SG_ 591 IDrvrFtgLvl "DrvrFtgLvl";
BA_ "ISignalName" SG_ 591 IDrvrFtgLvl "IDrvrFtgLvl";
BA_ "LongName" SG_ 591 IDrvrFtgLvl "Driver_Fatigue_Level";
BA_ "SysSignalName" SG_ 591 IDrvrFtgLvl "DrvrFtgLvl";
BA_ "CompuMethodName" SG_ 591 IDrvrPrsc "DrvrPrsc";
BA_ "ISignalName" SG_ 591 IDrvrPrsc "IDrvrPrsc";
BA_ "LongName" SG_ 591 IDrvrPrsc "Driver Presence";
BA_ "SysSignalName" SG_ 591 IDrvrPrsc "DrvrPrsc";
BA_ "CompuMethodName" SG_ 591 IIMATEysSts "IMATEysSts";
BA_ "ISignalName" SG_ 591 IIMATEysSts "IIMATEysSts";
BA_ "LongName" SG_ 591 IIMATEysSts "Driver_Monitor_System_Status";
BA_ "SysSignalName" SG_ 591 IIMATEysSts "IMATEysSts";
BA_ "CompuMethodName" SG_ 591 IDrvrDstrctnSts "DrvrDstrctnSts";
BA_ "ISignalName" SG_ 591 IDrvrDstrctnSts "IDrvrDstrctnSts";
BA_ "LongName" SG_ 591 IDrvrDstrctnSts "Driver Distraction Status";
BA_ "SysSignalName" SG_ 591 IDrvrDstrctnSts "DrvrDstrctnSts";
BA_ "CompuMethodName" SG_ 591 IDrvrAbnormBehvor "DrvrAbnormBehvor";
BA_ "ISignalName" SG_ 591 IDrvrAbnormBehvor "IDrvrAbnormBehvor";
BA_ "LongName" SG_ 591 IDrvrAbnormBehvor "Driver_Abnormal_Behaviour";
BA_ "SysSignalName" SG_ 591 IDrvrAbnormBehvor "DrvrAbnormBehvor";
BA_ "CompuMethodName" SG_ 591 IDrvrGazeRgn "DrvrGazeRgn";
BA_ "ISignalName" SG_ 591 IDrvrGazeRgn "IDrvrGazeRgn";
BA_ "LongName" SG_ 591 IDrvrGazeRgn "Driver_Gaze_Region";
BA_ "SysSignalName" SG_ 591 IDrvrGazeRgn "DrvrGazeRgn";
BA_ "CompuMethodName" SG_ 1301 IScurReqADS "ScurReqADS";
BA_ "ISignalName" SG_ 1301 IScurReqADS "IScurReqADS";
BA_ "LongName" SG_ 1301 IScurReqADS "Secure_Request_Automated_Driving_System";
BA_ "SysSignalName" SG_ 1301 IScurReqADS "ScurReqADS";
BA_ "CompuMethodName" SG_ 1302 IDrvngScurResp "DrvngScurResp";
BA_ "ISignalName" SG_ 1302 IDrvngScurResp "IDrvngScurResp";
BA_ "LongName" SG_ 1302 IDrvngScurResp "Driving_Secure_Response";
BA_ "SysSignalName" SG_ 1302 IDrvngScurResp "DrvngScurResp";
BA_ "CompuMethodName" SG_ 728 IParkingSubscribleStsreq "ParkingSubscribleStsreq";
BA_ "ISignalName" SG_ 728 IParkingSubscribleStsreq "IParkingSubscribleStsreq";
BA_ "LongName" SG_ 728 IParkingSubscribleStsreq "parking Subscrible Sts Request";
BA_ "SysSignalName" SG_ 728 IParkingSubscribleStsreq "ParkingSubscribleStsreq";
BA_ "CompuMethodName" SG_ 728 IPilotSubscribleStsreq "PilotSubscribleStsreq";
BA_ "ISignalName" SG_ 728 IPilotSubscribleStsreq "IPilotSubscribleStsreq";
BA_ "LongName" SG_ 728 IPilotSubscribleStsreq "Pilot Subscrible Sts Request";
BA_ "SysSignalName" SG_ 728 IPilotSubscribleStsreq "PilotSubscribleStsreq";
BA_ "CompuMethodName" SG_ 728 IAIParkngSpcIDICB "AIParkngSpcIDICB";
BA_ "ISignalName" SG_ 728 IAIParkngSpcIDICB "IAIParkngSpcIDICB";
BA_ "LongName" SG_ 728 IAIParkngSpcIDICB "AIParking Function Target Space ID Choose ICB";
BA_ "SysSignalName" SG_ 728 IAIParkngSpcIDICB "AIParkngSpcIDICB";
BA_ "CompuMethodName" SG_ 728 IRemParkngMapChosen "RemParkngMapChosen";
BA_ "ISignalName" SG_ 728 IRemParkngMapChosen "IRemParkngMapChosen";
BA_ "LongName" SG_ 728 IRemParkngMapChosen "remember parking map choosen";
BA_ "SysSignalName" SG_ 728 IRemParkngMapChosen "RemParkngMapChosen";
BA_ "CompuMethodName" SG_ 728 IAIParkngReqICB "AIParkngReqICB";
BA_ "ISignalName" SG_ 728 IAIParkngReqICB "IAIParkngReqICB";
BA_ "LongName" SG_ 728 IAIParkngReqICB "AIParking Function Request";
BA_ "SysSignalName" SG_ 728 IAIParkngReqICB "AIParkngReqICB";
BA_ "CompuMethodName" SG_ 728 IAIParkngScngAutocBtn "AIParkngScngAutocBtn";
BA_ "ISignalName" SG_ 728 IAIParkngScngAutocBtn "IAIParkngScngAutocBtn";
BA_ "LongName" SG_ 728 IAIParkngScngAutocBtn "AI Parking auto scanning button";
BA_ "SysSignalName" SG_ 728 IAIParkngScngAutocBtn "AIParkngScngAutocBtn";
BA_ "CompuMethodName" SG_ 1216 IICBVC_NM_BSMtoRMS_BKPCANFD "ICBVC_NM_BSMtoRMS_BKPCANFD";
BA_ "ISignalName" SG_ 1216 IICBVC_NM_BSMtoRMS_BKPCANFD "IICBVC_NM_BSMtoRMS_BKPCANFD";
BA_ "LongName" SG_ 1216 IICBVC_NM_BSMtoRMS_BKPCANFD "ICBVC_NM_BSMtoRMS_BKPCANFD";
BA_ "SysSignalName" SG_ 1216 IICBVC_NM_BSMtoRMS_BKPCANFD "ICBVC_NM_BSMtoRMS_BKPCANFD";
BA_ "CompuMethodName" SG_ 1216 IICBVC_NM_PBSMtoRMS_BKPCANFD "ICBVC_NM_PBSMtoRMS_BKPCANFD";
BA_ "ISignalName" SG_ 1216 IICBVC_NM_PBSMtoRMS_BKPCANFD "IICBVC_NM_PBSMtoRMS_BKPCANFD";
BA_ "LongName" SG_ 1216 IICBVC_NM_PBSMtoRMS_BKPCANFD "ICBVC_NM_PBSMtoRMS_BKPCANFD";
BA_ "SysSignalName" SG_ 1216 IICBVC_NM_PBSMtoRMS_BKPCANFD "ICBVC_NM_PBSMtoRMS_BKPCANFD";
BA_ "CompuMethodName" SG_ 1216 IICBVC_NM_RMStoNOS_BKPCANFD "ICBVC_NM_RMStoNOS_BKPCANFD";
BA_ "ISignalName" SG_ 1216 IICBVC_NM_RMStoNOS_BKPCANFD "IICBVC_NM_RMStoNOS_BKPCANFD";
BA_ "LongName" SG_ 1216 IICBVC_NM_RMStoNOS_BKPCANFD "ICBVC_NM_RMStoNOS_BKPCANFD";
BA_ "SysSignalName" SG_ 1216 IICBVC_NM_RMStoNOS_BKPCANFD "ICBVC_NM_RMStoNOS_BKPCANFD";
BA_ "CompuMethodName" SG_ 1216 IICBVC_NM_RSStoNOS_BKPCANFD "ICBVC_NM_RSStoNOS_BKPCANFD";
BA_ "ISignalName" SG_ 1216 IICBVC_NM_RSStoNOS_BKPCANFD "IICBVC_NM_RSStoNOS_BKPCANFD";
BA_ "LongName" SG_ 1216 IICBVC_NM_RSStoNOS_BKPCANFD "ICBVC_NM_RSStoNOS_BKPCANFD";
BA_ "SysSignalName" SG_ 1216 IICBVC_NM_RSStoNOS_BKPCANFD "ICBVC_NM_RSStoNOS_BKPCANFD";
BA_ "CompuMethodName" SG_ 1216 IICBVC_NM_RSStoRMS_BKPCANFD "ICBVC_NM_RSStoRMS_BKPCANFD";
BA_ "ISignalName" SG_ 1216 IICBVC_NM_RSStoRMS_BKPCANFD "IICBVC_NM_RSStoRMS_BKPCANFD";
BA_ "LongName" SG_ 1216 IICBVC_NM_RSStoRMS_BKPCANFD "ICBVC_NM_RSStoRMS_BKPCANFD";
BA_ "SysSignalName" SG_ 1216 IICBVC_NM_RSStoRMS_BKPCANFD "ICBVC_NM_RSStoRMS_BKPCANFD";
BA_ "CompuMethodName" SG_ 1216 IICBVC_NM_NOStoRMS_BKPCANFD "ICBVC_NM_NOStoRMS_BKPCANFD";
BA_ "ISignalName" SG_ 1216 IICBVC_NM_NOStoRMS_BKPCANFD "IICBVC_NM_NOStoRMS_BKPCANFD";
BA_ "LongName" SG_ 1216 IICBVC_NM_NOStoRMS_BKPCANFD "ICBVC_NM_NOStoRMS_BKPCANFD";
BA_ "SysSignalName" SG_ 1216 IICBVC_NM_NOStoRMS_BKPCANFD "ICBVC_NM_NOStoRMS_BKPCANFD";
BA_ "CompuMethodName" SG_ 1216 IICBVC_NM_NOSSta_BKPCANFD "ICBVC_NM_NOSSta_BKPCANFD";
BA_ "ISignalName" SG_ 1216 IICBVC_NM_NOSSta_BKPCANFD "IICBVC_NM_NOSSta_BKPCANFD";
BA_ "LongName" SG_ 1216 IICBVC_NM_NOSSta_BKPCANFD "ICBVC_NM_NOSSta_BKPCANFD";
BA_ "SysSignalName" SG_ 1216 IICBVC_NM_NOSSta_BKPCANFD "ICBVC_NM_NOSSta_BKPCANFD";
BA_ "CompuMethodName" SG_ 1216 IICBVC_NM_RMSSta_BKPCANFD "ICBVC_NM_RMSSta_BKPCANFD";
BA_ "ISignalName" SG_ 1216 IICBVC_NM_RMSSta_BKPCANFD "IICBVC_NM_RMSSta_BKPCANFD";
BA_ "LongName" SG_ 1216 IICBVC_NM_RMSSta_BKPCANFD "ICBVC_NM_RMSSta_BKPCANFD";
BA_ "SysSignalName" SG_ 1216 IICBVC_NM_RMSSta_BKPCANFD "ICBVC_NM_RMSSta_BKPCANFD";
BA_ "CompuMethodName" SG_ 1216 IICBVC_NWI_BKPCANFD "ICBVC_NWI_BKPCANFD";
BA_ "ISignalName" SG_ 1216 IICBVC_NWI_BKPCANFD "IICBVC_NWI_BKPCANFD";
BA_ "LongName" SG_ 1216 IICBVC_NWI_BKPCANFD "ICBVC BKPCANFD Network_Wakeup_Indication";
BA_ "SysSignalName" SG_ 1216 IICBVC_NWI_BKPCANFD "ICBVC_NWI_BKPCANFD";
BA_ "CompuMethodName" SG_ 1216 IICBVC_NOI_BKPCANFD "ICBVC_NOI_BKPCANFD";
BA_ "ISignalName" SG_ 1216 IICBVC_NOI_BKPCANFD "IICBVC_NOI_BKPCANFD";
BA_ "LongName" SG_ 1216 IICBVC_NOI_BKPCANFD "ICBVC BKPCANFD Network Operation Indication";
BA_ "SysSignalName" SG_ 1216 IICBVC_NOI_BKPCANFD "ICBVC_NOI_BKPCANFD";
BA_ "CompuMethodName" SG_ 1216 IICBVC_NKI_BKPCANFD "ICBVC_NKI_BKPCANFD";
BA_ "ISignalName" SG_ 1216 IICBVC_NKI_BKPCANFD "IICBVC_NKI_BKPCANFD";
BA_ "LongName" SG_ 1216 IICBVC_NKI_BKPCANFD "ICBVC BKPCANFD Network Keep Indication";
BA_ "SysSignalName" SG_ 1216 IICBVC_NKI_BKPCANFD "ICBVC_NKI_BKPCANFD";
BA_ "CompuMethodName" SG_ 790 IFOTAStatusValid "FOTAStatusValid";
BA_ "GenSigStartValue" SG_ 790 IFOTAStatusValid 1;
BA_ "ISignalName" SG_ 790 IFOTAStatusValid "IFOTAStatusValid";
BA_ "LongName" SG_ 790 IFOTAStatusValid "The Valid Of Firmware Over The Air Status";
BA_ "SysSignalName" SG_ 790 IFOTAStatusValid "FOTAStatusValid";
BA_ "CompuMethodName" SG_ 790 IFOTAStatus "FOTAStatus";
BA_ "ISignalName" SG_ 790 IFOTAStatus "IFOTAStatus";
BA_ "LongName" SG_ 790 IFOTAStatus "Firmware Over The Air Status";
BA_ "SysSignalName" SG_ 790 IFOTAStatus "FOTAStatus";
BA_ "CompuMethodName" SG_ 790 IFOTATarget "FOTATarget";
BA_ "ISignalName" SG_ 790 IFOTATarget "IFOTATarget";
BA_ "LongName" SG_ 790 IFOTATarget "Firmware Over The Air Target";
BA_ "SysSignalName" SG_ 790 IFOTATarget "FOTATarget";
BA_ "CompuMethodName" SG_ 790 IFOTATargetValid "FOTATargetValid";
BA_ "GenSigStartValue" SG_ 790 IFOTATargetValid 1;
BA_ "ISignalName" SG_ 790 IFOTATargetValid "IFOTATargetValid";
BA_ "LongName" SG_ 790 IFOTATargetValid "The Target Valid Of Firmware Over The Air Status";
BA_ "SysSignalName" SG_ 790 IFOTATargetValid "FOTATargetValid";
BA_ "CompuMethodName" SG_ 1008 IOtsdAirTemCrValV "OtsdAirTemCrValV";
BA_ "GenSigStartValue" SG_ 1008 IOtsdAirTemCrValV 1;
BA_ "ISignalName" SG_ 1008 IOtsdAirTemCrValV "IOtsdAirTemCrValV";
BA_ "LongName" SG_ 1008 IOtsdAirTemCrValV "Outside_Air_Temperature_Corrected_Value_Validity";
BA_ "SysSignalName" SG_ 1008 IOtsdAirTemCrValV "OtsdAirTemCrValV";
BA_ "CompuMethodName" SG_ 1008 IOtsdAirTemCrValMsk "OtsdAirTemCrValMsk";
BA_ "ISignalName" SG_ 1008 IOtsdAirTemCrValMsk "IOtsdAirTemCrValMsk";
BA_ "LongName" SG_ 1008 IOtsdAirTemCrValMsk "Outside_Air_Temperature_Corrected_Value_Mask";
BA_ "SysSignalName" SG_ 1008 IOtsdAirTemCrValMsk "OtsdAirTemCrValMsk";
BA_ "CompuMethodName" SG_ 1008 IOtsdAirTemVDA "OtsdAirTemVDA";
BA_ "ISignalName" SG_ 1008 IOtsdAirTemVDA "IOtsdAirTemVDA";
BA_ "LongName" SG_ 1008 IOtsdAirTemVDA "Outside Air Temperature Virtual Device Availability";
BA_ "SysSignalName" SG_ 1008 IOtsdAirTemVDA "OtsdAirTemVDA";
BA_ "CompuMethodName" SG_ 1008 IOtsdAirTemCrVal "OtsdAirTemCrVal";
BA_ "ISignalName" SG_ 1008 IOtsdAirTemCrVal "IOtsdAirTemCrVal";
BA_ "LongName" SG_ 1008 IOtsdAirTemCrVal "Outside_Air_Temperature_Corrected_Value";
BA_ "SysSignalName" SG_ 1008 IOtsdAirTemCrVal "OtsdAirTemCrVal";
BA_ "CompuMethodName" SG_ 1023 IRgnLvReqFICMV "RgnLvReqFICMV";
BA_ "GenSigStartValue" SG_ 1023 IRgnLvReqFICMV 1;
BA_ "ISignalName" SG_ 1023 IRgnLvReqFICMV "IRgnLvReqFICMV";
BA_ "LongName" SG_ 1023 IRgnLvReqFICMV "Regenerative_Level_Request_Ficm_Valid";
BA_ "SysSignalName" SG_ 1023 IRgnLvReqFICMV "RgnLvReqFICMV";
BA_ "CompuMethodName" SG_ 1023 IRgnLvReqFICM "RgnLvReqFICM";
BA_ "GenSigStartValue" SG_ 1023 IRgnLvReqFICM 1;
BA_ "ISignalName" SG_ 1023 IRgnLvReqFICM "IRgnLvReqFICM";
BA_ "LongName" SG_ 1023 IRgnLvReqFICM "Regenerative_Level_Request_Ficm";
BA_ "SysSignalName" SG_ 1023 IRgnLvReqFICM "RgnLvReqFICM";
BA_ "CompuMethodName" SG_ 1023 ILVBatChrgReqRaw "LVBatChrgReqRaw";
BA_ "ISignalName" SG_ 1023 ILVBatChrgReqRaw "ILVBatChrgReqRaw";
BA_ "LongName" SG_ 1023 ILVBatChrgReqRaw "Low Voltage Battery Charge Request Raw";
BA_ "SysSignalName" SG_ 1023 ILVBatChrgReqRaw "LVBatChrgReqRaw";
BA_ "CompuMethodName" SG_ 1023 ILVBatChrgReqInhbt "LVBatChrgReqInhbt";
BA_ "ISignalName" SG_ 1023 ILVBatChrgReqInhbt "ILVBatChrgReqInhbt";
BA_ "LongName" SG_ 1023 ILVBatChrgReqInhbt "Low Voltage Battery Charge Request Inhibit flag";
BA_ "SysSignalName" SG_ 1023 ILVBatChrgReqInhbt "LVBatChrgReqInhbt";
BA_ "CompuMethodName" SG_ 1023 ILVBatEnrgSufct "LVBatEnrgSufct";
BA_ "ISignalName" SG_ 1023 ILVBatEnrgSufct "ILVBatEnrgSufct";
BA_ "LongName" SG_ 1023 ILVBatEnrgSufct "Low Voltage Battery Energy Sufficient";
BA_ "SysSignalName" SG_ 1023 ILVBatEnrgSufct "LVBatEnrgSufct";
BA_ "CompuMethodName" SG_ 1023 ILVBatEnrgLow "LVBatEnrgLow";
BA_ "GenSigStartValue" SG_ 1023 ILVBatEnrgLow 1;
BA_ "ISignalName" SG_ 1023 ILVBatEnrgLow "ILVBatEnrgLow";
BA_ "LongName" SG_ 1023 ILVBatEnrgLow "Low Voltage Battery Energy Low";
BA_ "SysSignalName" SG_ 1023 ILVBatEnrgLow "LVBatEnrgLow";
BA_ "CompuMethodName" SG_ 1023 IVehFOTAHVReq "VehFOTAHVReq";
BA_ "ISignalName" SG_ 1023 IVehFOTAHVReq "IVehFOTAHVReq";
BA_ "LongName" SG_ 1023 IVehFOTAHVReq "Vehicle_FOTA_High_Voltage_Request";
BA_ "SysSignalName" SG_ 1023 IVehFOTAHVReq "VehFOTAHVReq";
BA_ "CompuMethodName" SG_ 1023 IEnrgSplReqV "EnrgSplReqV";
BA_ "GenSigStartValue" SG_ 1023 IEnrgSplReqV 1;
BA_ "ISignalName" SG_ 1023 IEnrgSplReqV "IEnrgSplReqV";
BA_ "LongName" SG_ 1023 IEnrgSplReqV "Energy Supply Request Validity";
BA_ "SysSignalName" SG_ 1023 IEnrgSplReqV "EnrgSplReqV";
BA_ "CompuMethodName" SG_ 1023 IEnrgSplReq "EnrgSplReq";
BA_ "ISignalName" SG_ 1023 IEnrgSplReq "IEnrgSplReq";
BA_ "LongName" SG_ 1023 IEnrgSplReq "Energy Supply Request";
BA_ "SysSignalName" SG_ 1023 IEnrgSplReq "EnrgSplReq";
BA_ "CompuMethodName" SG_ 1023 IPMDCSta "PMDCSta";
BA_ "ISignalName" SG_ 1023 IPMDCSta "IPMDCSta";
BA_ "LongName" SG_ 1023 IPMDCSta "Power_Management_Direct_Current_Converter_State";
BA_ "SysSignalName" SG_ 1023 IPMDCSta "PMDCSta";
BA_ "CompuMethodName" SG_ 1023 IEPMOprtMd "EPMOprtMd";
BA_ "ISignalName" SG_ 1023 IEPMOprtMd "IEPMOprtMd";
BA_ "LongName" SG_ 1023 IEPMOprtMd "Electric_Power_Management_Operation_Mode";
BA_ "SysSignalName" SG_ 1023 IEPMOprtMd "EPMOprtMd";
BA_ "CompuMethodName" SG_ 1023 IVehFotaReq "VehFotaReq";
BA_ "ISignalName" SG_ 1023 IVehFotaReq "IVehFotaReq";
BA_ "LongName" SG_ 1023 IVehFotaReq "Vehicle_FOTA_Request";
BA_ "SysSignalName" SG_ 1023 IVehFotaReq "VehFotaReq";
BA_ "CompuMethodName" SG_ 1023 IVehEnrgRdyLvlV "VehEnrgRdyLvlV";
BA_ "ISignalName" SG_ 1023 IVehEnrgRdyLvlV "IVehEnrgRdyLvlV";
BA_ "LongName" SG_ 1023 IVehEnrgRdyLvlV "Vehicle_Energy_Ready_Level_Validity";
BA_ "SysSignalName" SG_ 1023 IVehEnrgRdyLvlV "VehEnrgRdyLvlV";
BA_ "CompuMethodName" SG_ 1023 IVehEnrgRdyLvl "VehEnrgRdyLvl";
BA_ "GenSigStartValue" SG_ 1023 IVehEnrgRdyLvl 1;
BA_ "ISignalName" SG_ 1023 IVehEnrgRdyLvl "IVehEnrgRdyLvl";
BA_ "LongName" SG_ 1023 IVehEnrgRdyLvl "Vehicle_Energy_Ready_Level";
BA_ "SysSignalName" SG_ 1023 IVehEnrgRdyLvl "VehEnrgRdyLvl";
BA_ "CompuMethodName" SG_ 1023 IEPTToqCustSetngReqV "EPTToqCustSetngReqV";
BA_ "GenSigStartValue" SG_ 1023 IEPTToqCustSetngReqV 1;
BA_ "ISignalName" SG_ 1023 IEPTToqCustSetngReqV "IEPTToqCustSetngReqV";
BA_ "SysSignalName" SG_ 1023 IEPTToqCustSetngReqV "EPTToqCustSetngReqV";
BA_ "CompuMethodName" SG_ 1023 IEPTToqCustSetngReq "EPTToqCustSetngReq";
BA_ "GenSigStartValue" SG_ 1023 IEPTToqCustSetngReq 2;
BA_ "ISignalName" SG_ 1023 IEPTToqCustSetngReq "IEPTToqCustSetngReq";
BA_ "SysSignalName" SG_ 1023 IEPTToqCustSetngReq "EPTToqCustSetngReq";
BA_ "CompuMethodName" SG_ 1023 ILVBatSelfWakeupFlg "LVBatSelfWakeupFlg";
BA_ "ISignalName" SG_ 1023 ILVBatSelfWakeupFlg "ILVBatSelfWakeupFlg";
BA_ "LongName" SG_ 1023 ILVBatSelfWakeupFlg "ECU self wake-up flag";
BA_ "SysSignalName" SG_ 1023 ILVBatSelfWakeupFlg "LVBatSelfWakeupFlg";
BA_ "CompuMethodName" SG_ 1023 IEnrgSplReqRaw "EnrgSplReqRaw";
BA_ "ISignalName" SG_ 1023 IEnrgSplReqRaw "IEnrgSplReqRaw";
BA_ "LongName" SG_ 1023 IEnrgSplReqRaw "Vehicle Enregy Supply Rquest Raw Value";
BA_ "SysSignalName" SG_ 1023 IEnrgSplReqRaw "EnrgSplReqRaw";
BA_ "CompuMethodName" SG_ 922 IAVMDspReq "AVMDspReq";
BA_ "ISignalName" SG_ 922 IAVMDspReq "IAVMDspReq";
BA_ "LongName" SG_ 922 IAVMDspReq "Around_View_Monitor_Display_Request";
BA_ "SysSignalName" SG_ 922 IAVMDspReq "AVMDspReq";
BA_ "CompuMethodName" SG_ 922 IAutoViewChg "AutoViewChg";
BA_ "ISignalName" SG_ 922 IAutoViewChg "IAutoViewChg";
BA_ "LongName" SG_ 922 IAutoViewChg "AutoViewChg";
BA_ "SysSignalName" SG_ 922 IAutoViewChg "AutoViewChg";
BA_ "CompuMethodName" SG_ 922 IAlisysrdy "Alisysrdy";
BA_ "ISignalName" SG_ 922 IAlisysrdy "IAlisysrdy";
BA_ "LongName" SG_ 922 IAlisysrdy "Alisysrdy";
BA_ "SysSignalName" SG_ 922 IAlisysrdy "Alisysrdy";
BA_ "CompuMethodName" SG_ 922 ILiftMdReq "LiftMdReq";
BA_ "ISignalName" SG_ 922 ILiftMdReq "ILiftMdReq";
BA_ "LongName" SG_ 922 ILiftMdReq "Lift Mode Request_ui";
BA_ "SysSignalName" SG_ 922 ILiftMdReq "LiftMdReq";
BA_ "CompuMethodName" SG_ 922 IEasyLdMdReq "EasyLdMdReq";
BA_ "ISignalName" SG_ 922 IEasyLdMdReq "IEasyLdMdReq";
BA_ "LongName" SG_ 922 IEasyLdMdReq "Easy Load Mode Request_ui";
BA_ "SysSignalName" SG_ 922 IEasyLdMdReq "EasyLdMdReq";
BA_ "CompuMethodName" SG_ 922 IEasyEntMdReq "EasyEntMdReq";
BA_ "ISignalName" SG_ 922 IEasyEntMdReq "IEasyEntMdReq";
BA_ "LongName" SG_ 922 IEasyEntMdReq "Easy Entry Mode Request";
BA_ "SysSignalName" SG_ 922 IEasyEntMdReq "EasyEntMdReq";
BA_ "CompuMethodName" SG_ 922 IEasyPssReq "EasyPssReq";
BA_ "ISignalName" SG_ 922 IEasyPssReq "IEasyPssReq";
BA_ "LongName" SG_ 922 IEasyPssReq "Easy Pass Mode Request";
BA_ "SysSignalName" SG_ 922 IEasyPssReq "EasyPssReq";
BA_ "CompuMethodName" SG_ 922 IIEasyEntMdSetReq "IEasyEntMdSetReq";
BA_ "ISignalName" SG_ 922 IIEasyEntMdSetReq "IIEasyEntMdSetReq";
BA_ "LongName" SG_ 922 IIEasyEntMdSetReq "Intelligent Easy Entry Setting Request";
BA_ "SysSignalName" SG_ 922 IIEasyEntMdSetReq "IEasyEntMdSetReq";
BA_ "CompuMethodName" SG_ 922 IHDCReq "HDCReq";
BA_ "ISignalName" SG_ 922 IHDCReq "IHDCReq";
BA_ "LongName" SG_ 922 IHDCReq "Hill Descent Control Request";
BA_ "SysSignalName" SG_ 922 IHDCReq "HDCReq";
BA_ "CompuMethodName" SG_ 922 IEmmsnTestMdFICMV "EmmsnTestMdFICMV";
BA_ "GenSigStartValue" SG_ 922 IEmmsnTestMdFICMV 1;
BA_ "ISignalName" SG_ 922 IEmmsnTestMdFICMV "IEmmsnTestMdFICMV";
BA_ "LongName" SG_ 922 IEmmsnTestMdFICMV "Emission Test Mode Valid";
BA_ "SysSignalName" SG_ 922 IEmmsnTestMdFICMV "EmmsnTestMdFICMV";
BA_ "CompuMethodName" SG_ 922 ITrgtSOCReqFICM "TrgtSOCReqFICM";
BA_ "ISignalName" SG_ 922 ITrgtSOCReqFICM "ITrgtSOCReqFICM";
BA_ "LongName" SG_ 922 ITrgtSOCReqFICM "Target Soc Request";
BA_ "SysSignalName" SG_ 922 ITrgtSOCReqFICM "TrgtSOCReqFICM";
BA_ "CompuMethodName" SG_ 922 ISusLvlCtrlCustSetngReq "SusLvlCtrlCustSetngReq";
BA_ "ISignalName" SG_ 922 ISusLvlCtrlCustSetngReq "ISusLvlCtrlCustSetngReq";
BA_ "LongName" SG_ 922 ISusLvlCtrlCustSetngReq "Suspension Level Control Customization Setting Request";
BA_ "SysSignalName" SG_ 922 ISusLvlCtrlCustSetngReq "SusLvlCtrlCustSetngReq";
BA_ "CompuMethodName" SG_ 922 IFICMPwrDMdReq "FICMPwrDMdReq";
BA_ "ISignalName" SG_ 922 IFICMPwrDMdReq "IFICMPwrDMdReq";
BA_ "LongName" SG_ 922 IFICMPwrDMdReq "FICMPwrDMdReq";
BA_ "SysSignalName" SG_ 922 IFICMPwrDMdReq "FICMPwrDMdReq";
BA_ "CompuMethodName" SG_ 922 ICloseCalib "CloseCalib";
BA_ "ISignalName" SG_ 922 ICloseCalib "ICloseCalib";
BA_ "LongName" SG_ 922 ICloseCalib "CloseCalibration";
BA_ "SysSignalName" SG_ 922 ICloseCalib "CloseCalib";
BA_ "CompuMethodName" SG_ 922 ICalibFunc "CalibFunc";
BA_ "ISignalName" SG_ 922 ICalibFunc "ICalibFunc";
BA_ "LongName" SG_ 922 ICalibFunc "CalibrationFunction";
BA_ "SysSignalName" SG_ 922 ICalibFunc "CalibFunc";
BA_ "CompuMethodName" SG_ 922 IFICMPwrDMdReqV "FICMPwrDMdReqV";
BA_ "GenSigStartValue" SG_ 922 IFICMPwrDMdReqV 1;
BA_ "ISignalName" SG_ 922 IFICMPwrDMdReqV "IFICMPwrDMdReqV";
BA_ "LongName" SG_ 922 IFICMPwrDMdReqV "FICMPwrDMdReqV";
BA_ "SysSignalName" SG_ 922 IFICMPwrDMdReqV "FICMPwrDMdReqV";
BA_ "CompuMethodName" SG_ 922 IEmmsnTestMdFICM "EmmsnTestMdFICM";
BA_ "ISignalName" SG_ 922 IEmmsnTestMdFICM "IEmmsnTestMdFICM";
BA_ "LongName" SG_ 922 IEmmsnTestMdFICM "Emission Test Mode";
BA_ "SysSignalName" SG_ 922 IEmmsnTestMdFICM "EmmsnTestMdFICM";
BA_ "CompuMethodName" SG_ 922 IVehSpdDpdntLvlCtrlReq "VehSpdDpdntLvlCtrlReq";
BA_ "ISignalName" SG_ 922 IVehSpdDpdntLvlCtrlReq "IVehSpdDpdntLvlCtrlReq";
BA_ "LongName" SG_ 922 IVehSpdDpdntLvlCtrlReq "Vehicle Speed Dependent Level Control Request";
BA_ "SysSignalName" SG_ 922 IVehSpdDpdntLvlCtrlReq "VehSpdDpdntLvlCtrlReq";
BA_ "CompuMethodName" SG_ 922 IBtmFilgDspReq "BtmFilgDspReq";
BA_ "ISignalName" SG_ 922 IBtmFilgDspReq "IBtmFilgDspReq";
BA_ "LongName" SG_ 922 IBtmFilgDspReq "Bottom_Filling_Display_Request";
BA_ "SysSignalName" SG_ 922 IBtmFilgDspReq "BtmFilgDspReq";
BA_ "CompuMethodName" SG_ 922 ISusDmpngCtrlCustSetngReq "SusDmpngCtrlCustSetngReq";
BA_ "ISignalName" SG_ 922 ISusDmpngCtrlCustSetngReq "ISusDmpngCtrlCustSetngReq";
BA_ "LongName" SG_ 922 ISusDmpngCtrlCustSetngReq "Suspension Damping Control Customization Setting Request";
BA_ "SysSignalName" SG_ 922 ISusDmpngCtrlCustSetngReq "SusDmpngCtrlCustSetngReq";
BA_ "CompuMethodName" SG_ 922 ITrgtSOCReqFICMV "TrgtSOCReqFICMV";
BA_ "GenSigStartValue" SG_ 922 ITrgtSOCReqFICMV 1;
BA_ "ISignalName" SG_ 922 ITrgtSOCReqFICMV "ITrgtSOCReqFICMV";
BA_ "LongName" SG_ 922 ITrgtSOCReqFICMV "Target Soc Request Valid";
BA_ "SysSignalName" SG_ 922 ITrgtSOCReqFICMV "TrgtSOCReqFICMV";
BA_ "CompuMethodName" SG_ 1006 INavGudcSts "NavGudcSts";
BA_ "ISignalName" SG_ 1006 INavGudcSts "INavGudcSts";
BA_ "LongName" SG_ 1006 INavGudcSts "Navigation Guidance Status";
BA_ "SysSignalName" SG_ 1006 INavGudcSts "NavGudcSts";
BA_ "CompuMethodName" SG_ 1006 IDsttnTypOfNav "DsttnTypOfNav";
BA_ "ISignalName" SG_ 1006 IDsttnTypOfNav "IDsttnTypOfNav";
BA_ "LongName" SG_ 1006 IDsttnTypOfNav "Destination Type Of Navigation";
BA_ "SysSignalName" SG_ 1006 IDsttnTypOfNav "DsttnTypOfNav";
BA_ "CompuMethodName" SG_ 1006 IEPTSysCoolActvReq "EPTSysCoolActvReq";
BA_ "ISignalName" SG_ 1006 IEPTSysCoolActvReq "IEPTSysCoolActvReq";
BA_ "LongName" SG_ 1006 IEPTSysCoolActvReq "Electric Powertrain Transmission System Cool Active Request";
BA_ "SysSignalName" SG_ 1006 IEPTSysCoolActvReq "EPTSysCoolActvReq";
BA_ "CompuMethodName" SG_ 1006 IChrgngSttnCapctOfDsttnNav "ChrgngSttnCapctOfDsttnNav";
BA_ "ISignalName" SG_ 1006 IChrgngSttnCapctOfDsttnNav "IChrgngSttnCapctOfDsttnNav";
BA_ "LongName" SG_ 1006 IChrgngSttnCapctOfDsttnNav "Charging Station Capacity Of Destination Navigation";
BA_ "SysSignalName" SG_ 1006 IChrgngSttnCapctOfDsttnNav "ChrgngSttnCapctOfDsttnNav";
BA_ "CompuMethodName" SG_ 1006 IDistToDsttnNav "DistToDsttnNav";
BA_ "GenSigStartValue" SG_ 1006 IDistToDsttnNav 1023;
BA_ "ISignalName" SG_ 1006 IDistToDsttnNav "IDistToDsttnNav";
BA_ "LongName" SG_ 1006 IDistToDsttnNav "Distance To Destination Navigation";
BA_ "SysSignalName" SG_ 1006 IDistToDsttnNav "DistToDsttnNav";
BA_ "CompuMethodName" SG_ 1006 IElecEnrgAvgRstReq "ElecEnrgAvgRstReq";
BA_ "ISignalName" SG_ 1006 IElecEnrgAvgRstReq "IElecEnrgAvgRstReq";
BA_ "LongName" SG_ 1006 IElecEnrgAvgRstReq "Electric Energy Average Reset Request";
BA_ "SysSignalName" SG_ 1006 IElecEnrgAvgRstReq "ElecEnrgAvgRstReq";
BA_ "CompuMethodName" SG_ 1006 IFICMOnRutWarmOffReqV "FICMOnRutWarmOffReqV";
BA_ "GenSigStartValue" SG_ 1006 IFICMOnRutWarmOffReqV 1;
BA_ "ISignalName" SG_ 1006 IFICMOnRutWarmOffReqV "IFICMOnRutWarmOffReqV";
BA_ "LongName" SG_ 1006 IFICMOnRutWarmOffReqV "FICM On Route Warm Off Request Valid";
BA_ "SysSignalName" SG_ 1006 IFICMOnRutWarmOffReqV "FICMOnRutWarmOffReqV";
BA_ "CompuMethodName" SG_ 1006 IFICMChrgCtrlReq "FICMChrgCtrlReq";
BA_ "ISignalName" SG_ 1006 IFICMChrgCtrlReq "IFICMChrgCtrlReq";
BA_ "LongName" SG_ 1006 IFICMChrgCtrlReq "Front_Infotainment_Control_Module_Charge_Control_Request";
BA_ "SysSignalName" SG_ 1006 IFICMChrgCtrlReq "FICMChrgCtrlReq";
BA_ "CompuMethodName" SG_ 1006 IFICMOnRouteWarmSwReq "FICMOnRouteWarmSwReq";
BA_ "ISignalName" SG_ 1006 IFICMOnRouteWarmSwReq "IFICMOnRouteWarmSwReq";
BA_ "LongName" SG_ 1006 IFICMOnRouteWarmSwReq "Ficm_On_Route_Warm_Off_Request";
BA_ "SysSignalName" SG_ 1006 IFICMOnRouteWarmSwReq "FICMOnRouteWarmSwReq";
BA_ "CompuMethodName" SG_ 1006 IFICMOnRutWarmOffReq "FICMOnRutWarmOffReq";
BA_ "ISignalName" SG_ 1006 IFICMOnRutWarmOffReq "IFICMOnRutWarmOffReq";
BA_ "LongName" SG_ 1006 IFICMOnRutWarmOffReq "Front_Infotainment_Control_Module_On_Route

_Warm_Req";
BA_ "SysSignalName" SG_ 1006 IFICMOnRutWarmOffReq "FICMOnRutWarmOffReq";
BA_ "CompuMethodName" SG_ 1006 IIPKSetVehEleclRngAlg "IPKSetVehEleclRngAlg";
BA_ "ISignalName" SG_ 1006 IIPKSetVehEleclRngAlg "IIPKSetVehEleclRngAlg";
BA_ "LongName" SG_ 1006 IIPKSetVehEleclRngAlg "InstrumentPackSetVehicleElectricalRangeAlgorithm";
BA_ "SysSignalName" SG_ 1006 IIPKSetVehEleclRngAlg "IPKSetVehEleclRngAlg";
BA_ "CompuMethodName" SG_ 1006 IFICMV2XReq "FICMV2XReq";
BA_ "ISignalName" SG_ 1006 IFICMV2XReq "IFICMV2XReq";
BA_ "LongName" SG_ 1006 IFICMV2XReq "Front_Infotainment_Control_Module_V2x_Request";
BA_ "SysSignalName" SG_ 1006 IFICMV2XReq "FICMV2XReq";
BA_ "CompuMethodName" SG_ 1006 IFICMEleccLckCtrlReq "FICMEleccLckCtrlReq";
BA_ "ISignalName" SG_ 1006 IFICMEleccLckCtrlReq "IFICMEleccLckCtrlReq";
BA_ "LongName" SG_ 1006 IFICMEleccLckCtrlReq "Front_Infotainment_Control_Module_Electronic_Lock_Control_Request";
BA_ "SysSignalName" SG_ 1006 IFICMEleccLckCtrlReq "FICMEleccLckCtrlReq";
BA_ "CompuMethodName" SG_ 1006 IGudTimeToDsttnNav "GudTimeToDsttnNav";
BA_ "ISignalName" SG_ 1006 IGudTimeToDsttnNav "IGudTimeToDsttnNav";
BA_ "LongName" SG_ 1006 IGudTimeToDsttnNav "Guide Time To Destination Navigation";
BA_ "SysSignalName" SG_ 1006 IGudTimeToDsttnNav "GudTimeToDsttnNav";
BA_ "CompuMethodName" SG_ 795 IDCDCVolStpt "DCDCVolStpt";
BA_ "GenSigStartValue" SG_ 795 IDCDCVolStpt 254;
BA_ "ISignalName" SG_ 795 IDCDCVolStpt "IDCDCVolStpt";
BA_ "LongName" SG_ 795 IDCDCVolStpt "Direct Current Direct Current Voltage Setpoint";
BA_ "SysSignalName" SG_ 795 IDCDCVolStpt "DCDCVolStpt";
BA_ "CompuMethodName" SG_ 795 ISLIFUpdtIndReq "SLIFUpdtIndReq";
BA_ "ISignalName" SG_ 795 ISLIFUpdtIndReq "ISLIFUpdtIndReq";
BA_ "LongName" SG_ 795 ISLIFUpdtIndReq "Speed Limit Information Function Update Indication Request";
BA_ "SysSignalName" SG_ 795 ISLIFUpdtIndReq "SLIFUpdtIndReq";
BA_ "CompuMethodName" SG_ 795 IBatVol "BatVol";
BA_ "ISignalName" SG_ 795 IBatVol "IBatVol";
BA_ "LongName" SG_ 795 IBatVol "Battery Voltage";
BA_ "SysSignalName" SG_ 795 IBatVol "BatVol";
BA_ "CompuMethodName" SG_ 795 IEasyLvlReq "EasyLvlReq";
BA_ "ISignalName" SG_ 795 IEasyLvlReq "IEasyLvlReq";
BA_ "LongName" SG_ 795 IEasyLvlReq "Easy_level_Request";
BA_ "SysSignalName" SG_ 795 IEasyLvlReq "EasyLvlReq";
BA_ "CompuMethodName" SG_ 795 ISprSportSubItemReqV "SprSportSubItemReqV";
BA_ "ISignalName" SG_ 795 ISprSportSubItemReqV "ISprSportSubItemReqV";
BA_ "SysSignalName" SG_ 795 ISprSportSubItemReqV "SprSportSubItemReqV";
BA_ "CompuMethodName" SG_ 795 ISprSportSubItemReq "SprSportSubItemReq";
BA_ "ISignalName" SG_ 795 ISprSportSubItemReq "ISprSportSubItemReq";
BA_ "SysSignalName" SG_ 795 ISprSportSubItemReq "SprSportSubItemReq";
BA_ "CompuMethodName" SG_ 907 IICBVC_100ms_Group80_CRC "ICBVC_100ms_Group80_CRC";
BA_ "ISignalName" SG_ 907 IICBVC_100ms_Group80_CRC "IICBVC_100ms_Group80_CRC";
BA_ "SysSignalName" SG_ 907 IICBVC_100ms_Group80_CRC "ICBVC_100ms_Group80_CRC";
BA_ "CompuMethodName" SG_ 907 IICBVC_100ms_Group80_RC "ICBVC_100ms_Group80_RC";
BA_ "ISignalName" SG_ 907 IICBVC_100ms_Group80_RC "IICBVC_100ms_Group80_RC";
BA_ "SysSignalName" SG_ 907 IICBVC_100ms_Group80_RC "ICBVC_100ms_Group80_RC";
BA_ "CompuMethodName" SG_ 907 IVehDrvngMd "VehDrvngMd";
BA_ "ISignalName" SG_ 907 IVehDrvngMd "IVehDrvngMd";
BA_ "LongName" SG_ 907 IVehDrvngMd "Vehicle Driving Mode";
BA_ "SysSignalName" SG_ 907 IVehDrvngMd "VehDrvngMd";
BA_ "CompuMethodName" SG_ 907 IVehOdo "VehOdo";
BA_ "ISignalName" SG_ 907 IVehOdo "IVehOdo";
BA_ "LongName" SG_ 907 IVehOdo "Vehicle_Odometer";
BA_ "SysSignalName" SG_ 907 IVehOdo "VehOdo";
BA_ "CompuMethodName" SG_ 907 IICBVC_100ms_Group80_Reserved1 "ICBVC_100ms_Group80_Reserved1";
BA_ "GenSigStartValue" SG_ 907 IICBVC_100ms_Group80_Reserved1 15;
BA_ "ISignalName" SG_ 907 IICBVC_100ms_Group80_Reserved1 "IICBVC_100ms_Group80_Reserved1";
BA_ "SysSignalName" SG_ 907 IICBVC_100ms_Group80_Reserved1 "ICBVC_100ms_Group80_Reserved1";
BA_ "CompuMethodName" SG_ 907 IVehLdShedLvl "VehLdShedLvl";
BA_ "ISignalName" SG_ 907 IVehLdShedLvl "IVehLdShedLvl";
BA_ "LongName" SG_ 907 IVehLdShedLvl "Vehicle Load Shed Level";
BA_ "SysSignalName" SG_ 907 IVehLdShedLvl "VehLdShedLvl";
BA_ "CompuMethodName" SG_ 907 IVehOdoV "VehOdoV";
BA_ "GenSigStartValue" SG_ 907 IVehOdoV 1;
BA_ "ISignalName" SG_ 907 IVehOdoV "IVehOdoV";
BA_ "LongName" SG_ 907 IVehOdoV "Vehicle_Odometer_Validity";
BA_ "SysSignalName" SG_ 907 IVehOdoV "VehOdoV";
BA_ "CompuMethodName" SG_ 907 IICBVC_100ms_Group80_Reserved2 "ICBVC_100ms_Group80_Reserved2";
BA_ "GenSigStartValue" SG_ 907 IICBVC_100ms_Group80_Reserved2 255;
BA_ "ISignalName" SG_ 907 IICBVC_100ms_Group80_Reserved2 "IICBVC_100ms_Group80_Reserved2";
BA_ "SysSignalName" SG_ 907 IICBVC_100ms_Group80_Reserved2 "ICBVC_100ms_Group80_Reserved2";
BA_ "CompuMethodName" SG_ 907 IFrtPsngAirbagSwStsReqV_Sfty "FrtPsngAirbagSwStsReqV_Sfty";
BA_ "ISignalName" SG_ 907 IFrtPsngAirbagSwStsReqV_Sfty "IFrtPsngAirbagSwStsReqV_Sfty";
BA_ "LongName" SG_ 907 IFrtPsngAirbagSwStsReqV_Sfty "Front Passenger Airbag Switch Status Request Validity";
BA_ "SysSignalName" SG_ 907 IFrtPsngAirbagSwStsReqV_Sfty "FrtPsngAirbagSwStsReqV_Sfty";
BA_ "CompuMethodName" SG_ 907 IFrtPsngAirbagSwStsReq_Sfty "FrtPsngAirbagSwStsReq_Sfty";
BA_ "ISignalName" SG_ 907 IFrtPsngAirbagSwStsReq_Sfty "IFrtPsngAirbagSwStsReq_Sfty";
BA_ "LongName" SG_ 907 IFrtPsngAirbagSwStsReq_Sfty "Front Passenger Airbag Switch Status Request";
BA_ "SysSignalName" SG_ 907 IFrtPsngAirbagSwStsReq_Sfty "FrtPsngAirbagSwStsReq_Sfty";
BA_ "CompuMethodName" SG_ 907 IICBVC_100ms_Group80_Reserved3 "ICBVC_100ms_Group80_Reserved31";
BA_ "GenSigStartValue" SG_ 907 IICBVC_100ms_Group80_Reserved3 63;
BA_ "ISignalName" SG_ 907 IICBVC_100ms_Group80_Reserved3 "IICBVC_100ms_Group80_Reserved3";
BA_ "SysSignalName" SG_ 907 IICBVC_100ms_Group80_Reserved3 "ICBVC_100ms_Group80_Reserved3";
BA_ "CompuMethodName" SG_ 1345 IVehTiPblshYear "VehTiPblshYear";
BA_ "GenSigStartValue" SG_ 1345 IVehTiPblshYear 23;
BA_ "ISignalName" SG_ 1345 IVehTiPblshYear "IVehTiPblshYear";
BA_ "LongName" SG_ 1345 IVehTiPblshYear "Vehicle Time Publish Year";
BA_ "SysSignalName" SG_ 1345 IVehTiPblshYear "VehTiPblshYear";
BA_ "CompuMethodName" SG_ 1345 IVehTiPblshMth "VehTiPblshMth";
BA_ "ISignalName" SG_ 1345 IVehTiPblshMth "IVehTiPblshMth";
BA_ "LongName" SG_ 1345 IVehTiPblshMth "Vehicle Time Publish Month";
BA_ "SysSignalName" SG_ 1345 IVehTiPblshMth "VehTiPblshMth";
BA_ "CompuMethodName" SG_ 1345 IVehTiPblshDay "VehTiPblshDay";
BA_ "ISignalName" SG_ 1345 IVehTiPblshDay "IVehTiPblshDay";
BA_ "LongName" SG_ 1345 IVehTiPblshDay "Vehicle Time Publish Day";
BA_ "SysSignalName" SG_ 1345 IVehTiPblshDay "VehTiPblshDay";
BA_ "CompuMethodName" SG_ 1345 IVehTiPblshHr "VehTiPblshHr";
BA_ "ISignalName" SG_ 1345 IVehTiPblshHr "IVehTiPblshHr";
BA_ "LongName" SG_ 1345 IVehTiPblshHr "Vehicle Time Publish Hour";
BA_ "SysSignalName" SG_ 1345 IVehTiPblshHr "VehTiPblshHr";
BA_ "CompuMethodName" SG_ 1345 IVehTiPblshMins "VehTiPblshMins";
BA_ "ISignalName" SG_ 1345 IVehTiPblshMins "IVehTiPblshMins";
BA_ "LongName" SG_ 1345 IVehTiPblshMins "Vehicle Time Publish Minute";
BA_ "SysSignalName" SG_ 1345 IVehTiPblshMins "VehTiPblshMins";
BA_ "CompuMethodName" SG_ 1345 IVehTiPblshSec "VehTiPblshSec";
BA_ "ISignalName" SG_ 1345 IVehTiPblshSec "IVehTiPblshSec";
BA_ "LongName" SG_ 1345 IVehTiPblshSec "Vehicle Time Publish Second";
BA_ "SysSignalName" SG_ 1345 IVehTiPblshSec "VehTiPblshSec";
BA_ "CompuMethodName" SG_ 361 INFCAMAvlbly "NFCAMAvlbly";
BA_ "ISignalName" SG_ 361 INFCAMAvlbly "INFCAMAvlbly";
BA_ "LongName" SG_ 361 INFCAMAvlbly "NFCAM LHBDCANFD Availability";
BA_ "SysSignalName" SG_ 361 INFCAMAvlbly "NFCAMAvlbly";
BA_ "CompuMethodName" SG_ 361 ISDMAvlbly "SDMAvlbly";
BA_ "ISignalName" SG_ 361 ISDMAvlbly "ISDMAvlbly";
BA_ "LongName" SG_ 361 ISDMAvlbly "SDM SFCANFD Availability";
BA_ "SysSignalName" SG_ 361 ISDMAvlbly "SDMAvlbly";
BA_ "CompuMethodName" SG_ 361 IRHZCUAvlbly "RHZCUAvlbly";
BA_ "ISignalName" SG_ 361 IRHZCUAvlbly "IRHZCUAvlbly";
BA_ "LongName" SG_ 361 IRHZCUAvlbly "RHZCU RHBKCANFD Availability";
BA_ "SysSignalName" SG_ 361 IRHZCUAvlbly "RHZCUAvlbly";
BA_ "CompuMethodName" SG_ 361 ILHZCUAvlbly "LHZCUAvlbly";
BA_ "ISignalName" SG_ 361 ILHZCUAvlbly "ILHZCUAvlbly";
BA_ "LongName" SG_ 361 ILHZCUAvlbly "LHZCU LHBKBCANFD Availability";
BA_ "SysSignalName" SG_ 361 ILHZCUAvlbly "LHZCUAvlbly";
BA_ "CompuMethodName" SG_ 361 ITC_ExtdAvlbly "TC_ExtdAvlbly";
BA_ "ISignalName" SG_ 361 ITC_ExtdAvlbly "ITC_ExtdAvlbly";
BA_ "LongName" SG_ 361 ITC_ExtdAvlbly "TC PTEXTDCAN Availability";
BA_ "SysSignalName" SG_ 361 ITC_ExtdAvlbly "TC_ExtdAvlbly";
BA_ "CompuMethodName" SG_ 361 IIBS_SFAvlbly "IBS_SFAvlbly";
BA_ "ISignalName" SG_ 361 IIBS_SFAvlbly "IIBS_SFAvlbly";
BA_ "LongName" SG_ 361 IIBS_SFAvlbly "IBS SFCANFD Availability";
BA_ "SysSignalName" SG_ 361 IIBS_SFAvlbly "IBS_SFAvlbly";
BA_ "CompuMethodName" SG_ 361 IEPSAvlbly "EPSAvlbly";
BA_ "ISignalName" SG_ 361 IEPSAvlbly "IEPSAvlbly";
BA_ "LongName" SG_ 361 IEPSAvlbly "EPS CHCANFD Availability";
BA_ "SysSignalName" SG_ 361 IEPSAvlbly "EPSAvlbly";
BA_ "CompuMethodName" SG_ 361 ITC_PTAvlbly "TC_PTAvlbly";
BA_ "ISignalName" SG_ 361 ITC_PTAvlbly "ITC_PTAvlbly";
BA_ "LongName" SG_ 361 ITC_PTAvlbly "TC PTCANFD Availability";
BA_ "SysSignalName" SG_ 361 ITC_PTAvlbly "TC_PTAvlbly";
BA_ "CompuMethodName" SG_ 361 IPICU_PTAvlbly "PICU_PTAvlbly";
BA_ "ISignalName" SG_ 361 IPICU_PTAvlbly "IPICU_PTAvlbly";
BA_ "LongName" SG_ 361 IPICU_PTAvlbly "PICU PTCANFD Availability";
BA_ "SysSignalName" SG_ 361 IPICU_PTAvlbly "PICU_PTAvlbly";
BA_ "CompuMethodName" SG_ 361 IPEU_PTAvlbly "PEU_PTAvlbly";
BA_ "ISignalName" SG_ 361 IPEU_PTAvlbly "IPEU_PTAvlbly";
BA_ "LongName" SG_ 361 IPEU_PTAvlbly "PEU PTCANFD Availability";
BA_ "SysSignalName" SG_ 361 IPEU_PTAvlbly "PEU_PTAvlbly";
BA_ "CompuMethodName" SG_ 361 IPEU_ERAvlbly "PEU_ERAvlbly";
BA_ "ISignalName" SG_ 361 IPEU_ERAvlbly "IPEU_ERAvlbly";
BA_ "LongName" SG_ 361 IPEU_ERAvlbly "PEU ERCANFD Availability";
BA_ "SysSignalName" SG_ 361 IPEU_ERAvlbly "PEU_ERAvlbly";
BA_ "CompuMethodName" SG_ 361 IPICU_ExtdAvlbly "PICU_ExtdAvlbly";
BA_ "ISignalName" SG_ 361 IPICU_ExtdAvlbly "IPICU_ExtdAvlbly";
BA_ "LongName" SG_ 361 IPICU_ExtdAvlbly "PICU PTCANFD Availability";
BA_ "SysSignalName" SG_ 361 IPICU_ExtdAvlbly "PICU_ExtdAvlbly";
BA_ "CompuMethodName" SG_ 361 ILHRDAAvlbly "LHRDAAvlbly";
BA_ "ISignalName" SG_ 361 ILHRDAAvlbly "ILHRDAAvlbly";
BA_ "LongName" SG_ 361 ILHRDAAvlbly "LHRDA BKPCANFD Avlbly";
BA_ "SysSignalName" SG_ 361 ILHRDAAvlbly "LHRDAAvlbly";
BA_ "CompuMethodName" SG_ 361 IIPD_PTAvlbly "IPD_PTAvlbly";
BA_ "ISignalName" SG_ 361 IIPD_PTAvlbly "IIPD_PTAvlbly";
BA_ "LongName" SG_ 361 IIPD_PTAvlbly "IPD PTCANFD Availability";
BA_ "SysSignalName" SG_ 361 IIPD_PTAvlbly "IPD_PTAvlbly";
BA_ "CompuMethodName" SG_ 361 IESS_PTAvlbly "ESS_PTAvlbly";
BA_ "ISignalName" SG_ 361 IESS_PTAvlbly "IESS_PTAvlbly";
BA_ "LongName" SG_ 361 IESS_PTAvlbly "ESS PTCANFD Availability";
BA_ "SysSignalName" SG_ 361 IESS_PTAvlbly "ESS_PTAvlbly";
BA_ "CompuMethodName" SG_ 361 ICCU_ExtdAvlbly "CCU_ExtdAvlbly";
BA_ "ISignalName" SG_ 361 ICCU_ExtdAvlbly "ICCU_ExtdAvlbly";
BA_ "LongName" SG_ 361 ICCU_ExtdAvlbly "CCU PTEXTDCAN Availability";
BA_ "SysSignalName" SG_ 361 ICCU_ExtdAvlbly "CCU_ExtdAvlbly";
BA_ "CompuMethodName" SG_ 361 IESS_ExtdAvlbly "ESS_ExtdAvlbly";
BA_ "ISignalName" SG_ 361 IESS_ExtdAvlbly "IESS_ExtdAvlbly";
BA_ "LongName" SG_ 361 IESS_ExtdAvlbly "ESS PTEXTDCAN Availability";
BA_ "SysSignalName" SG_ 361 IESS_ExtdAvlbly "ESS_ExtdAvlbly";
BA_ "CompuMethodName" SG_ 361 ICCU_PTAvlbly "CCU_PTAvlbly";
BA_ "ISignalName" SG_ 361 ICCU_PTAvlbly "ICCU_PTAvlbly";
BA_ "LongName" SG_ 361 ICCU_PTAvlbly "CCU PTCANFD Availability";
BA_ "SysSignalName" SG_ 361 ICCU_PTAvlbly "CCU_PTAvlbly";
BA_ "CompuMethodName" SG_ 361 IIAMAvlbly "IAMAvlbly";
BA_ "ISignalName" SG_ 361 IIAMAvlbly "IIAMAvlbly";
BA_ "LongName" SG_ 361 IIAMAvlbly "IAM CONNCANFD Availability";
BA_ "SysSignalName" SG_ 361 IIAMAvlbly "IAMAvlbly";
BA_ "CompuMethodName" SG_ 361 IEAC_Avlbly "EAC_Avlbly";
BA_ "ISignalName" SG_ 361 IEAC_Avlbly "IEAC_Avlbly";
BA_ "LongName" SG_ 361 IEAC_Avlbly "EAC RHBDCAN Availability";
BA_ "SysSignalName" SG_ 361 IEAC_Avlbly "EAC_Avlbly";
BA_ "CompuMethodName" SG_ 361 IIPD_SFAvlbly "IPD_SFAvlbly";
BA_ "ISignalName" SG_ 361 IIPD_SFAvlbly "IIPD_SFAvlbly";
BA_ "LongName" SG_ 361 IIPD_SFAvlbly "IPD SFCANFD Availability";
BA_ "SysSignalName" SG_ 361 IIPD_SFAvlbly "IPD_SFAvlbly";
BA_ "CompuMethodName" SG_ 361 ICCEOPAvlbly "CCEOPAvlbly";
BA_ "ISignalName" SG_ 361 ICCEOPAvlbly "ICCEOPAvlbly";
BA_ "LongName" SG_ 361 ICCEOPAvlbly "CCU Availability";
BA_ "SysSignalName" SG_ 361 ICCEOPAvlbly "CCEOPAvlbly";
BA_ "CompuMethodName" SG_ 361 IRZCU_BKBCANFDAvlbly "RZCU_BKBCANFDAvlbly";
BA_ "ISignalName" SG_ 361 IRZCU_BKBCANFDAvlbly "IRZCU_BKBCANFDAvlbly";
BA_ "LongName" SG_ 361 IRZCU_BKBCANFDAvlbly "RZCU BKBCANFD  Availability";
BA_ "SysSignalName" SG_ 361 IRZCU_BKBCANFDAvlbly "RZCU_BKBCANFDAvlbly";
BA_ "CompuMethodName" SG_ 361 IIPD_BKPCANFDAvlbly "IPD_BKPCANFDAvlbly";
BA_ "ISignalName" SG_ 361 IIPD_BKPCANFDAvlbly "IIPD_BKPCANFDAvlbly";
BA_ "LongName" SG_ 361 IIPD_BKPCANFDAvlbly "IPD  BKPCANFD Availability";
BA_ "SysSignalName" SG_ 361 IIPD_BKPCANFDAvlbly "IPD_BKPCANFDAvlbly";
BA_ "CompuMethodName" SG_ 361 IIPD_CHCANFDAvlbly "IPD_CHCANFDAvlbly";
BA_ "ISignalName" SG_ 361 IIPD_CHCANFDAvlbly "IIPD_CHCANFDAvlbly";
BA_ "LongName" SG_ 361 IIPD_CHCANFDAvlbly "IPD CHCANFD Availability";
BA_ "SysSignalName" SG_ 361 IIPD_CHCANFDAvlbly "IPD_CHCANFDAvlbly";
BA_ "CompuMethodName" SG_ 361 IIBS_CHAvlbly "IBS_CHAvlbly";
BA_ "ISignalName" SG_ 361 IIBS_CHAvlbly "IIBS_CHAvlbly";
BA_ "LongName" SG_ 361 IIBS_CHAvlbly "IBS CHCANFD Availability";
BA_ "SysSignalName" SG_ 361 IIBS_CHAvlbly "IBS_CHAvlbly";
BA_ "CompuMethodName" SG_ 361 IFDRAvlbly "FDRAvlbly";
BA_ "ISignalName" SG_ 361 IFDRAvlbly "IFDRAvlbly";
BA_ "LongName" SG_ 361 IFDRAvlbly "FDR BKPCANFD Availability";
BA_ "SysSignalName" SG_ 361 IFDRAvlbly "FDRAvlbly";
BA_ "CompuMethodName" SG_ 361 IRHRDAAvlbly "RHRDAAvlbly";
BA_ "ISignalName" SG_ 361 IRHRDAAvlbly "IRHRDAAvlbly";
BA_ "LongName" SG_ 361 IRHRDAAvlbly "RHRDA BKPCANFD Avlbly";
BA_ "SysSignalName" SG_ 361 IRHRDAAvlbly "RHRDAAvlbly";
BA_ "CompuMethodName" SG_ 361 IFVCMAvlbly "FVCMAvlbly";
BA_ "ISignalName" SG_ 361 IFVCMAvlbly "IFVCMAvlbly";
BA_ "LongName" SG_ 361 IFVCMAvlbly "FDR BKPCANFD Availability";
BA_ "SysSignalName" SG_ 361 IFVCMAvlbly "FVCMAvlbly";
BA_ "CompuMethodName" SG_ 361 ITPMSAvlbly "TPMSAvlbly";
BA_ "ISignalName" SG_ 361 ITPMSAvlbly "ITPMSAvlbly";
BA_ "LongName" SG_ 361 ITPMSAvlbly "TPMS LHBDCANFD Availability";
BA_ "SysSignalName" SG_ 361 ITPMSAvlbly "TPMSAvlbly";
BA_ "CompuMethodName" SG_ 497 IICBVC_20ms_Group03_CRC "ICBVC_20ms_Group03_CRC";
BA_ "ISignalName" SG_ 497 IICBVC_20ms_Group03_CRC "IICBVC_20ms_Group03_CRC";
BA_ "SysSignalName" SG_ 497 IICBVC_20ms_Group03_CRC "ICBVC_20ms_Group03_CRC";
BA_ "CompuMethodName" SG_ 497 IICBVC_20ms_Group03_RC "ICBVC_20ms_Group03_RC";
BA_ "ISignalName" SG_ 497 IICBVC_20ms_Group03_RC "IICBVC_20ms_Group03_RC";
BA_ "SysSignalName" SG_ 497 IICBVC_20ms_Group03_RC "ICBVC_20ms_Group03_RC";
BA_ "CompuMethodName" SG_ 497 IAMRPrtensonReq "AMRPrtensonReq";
BA_ "ISignalName" SG_ 497 IAMRPrtensonReq "IAMRPrtensonReq";
BA_ "LongName" SG_ 497 IAMRPrtensonReq "AMR_Pretension_Request";
BA_ "SysSignalName" SG_ 497 IAMRPrtensonReq "AMRPrtensonReq";
BA_ "CompuMethodName" SG_ 497 IICBVC_20ms_Group03_Reserved2 "ICBVC_20ms_Group03_Reserved2";
BA_ "GenSigStartValue" SG_ 497 IICBVC_20ms_Group03_Reserved2 15;
BA_ "ISignalName" SG_ 497 IICBVC_20ms_Group03_Reserved2 "IICBVC_20ms_Group03_Reserved2";
BA_ "SysSignalName" SG_ 497 IICBVC_20ms_Group03_Reserved2 "ICBVC_20ms_Group03_Reserved2";
BA_ "CompuMethodName" SG_ 497 ISysVolMdV "SysVolMdV";
BA_ "GenSigStartValue" SG_ 497 ISysVolMdV 1;
BA_ "ISignalName" SG_ 497 ISysVolMdV "ISysVolMdV";
BA_ "LongName" SG_ 497 ISysVolMdV "System Voltage Mode Validity";
BA_ "SysSignalName" SG_ 497 ISysVolMdV "SysVolMdV";
BA_ "CompuMethodName" SG_ 497 IICBVC_20ms_Group03_Reserved1 "ICBVC_20ms_Group03_Reserved1";
BA_ "GenSigStartValue" SG_ 497 IICBVC_20ms_Group03_Reserved1 7;
BA_ "ISignalName" SG_ 497 IICBVC_20ms_Group03_Reserved1 "IICBVC_20ms_Group03_Reserved1";
BA_ "SysSignalName" SG_ 497 IICBVC_20ms_Group03_Reserved1 "ICBVC_20ms_Group03_Reserved1";
BA_ "CompuMethodName" SG_ 497 IICBVC_20ms_Group03_Reserved3 "ICBVC_20ms_Group03_Reserved3";
BA_ "GenSigStartValue" SG_ 497 IICBVC_20ms_Group03_Reserved3 15;
BA_ "ISignalName" SG_ 497 IICBVC_20ms_Group03_Reserved3 "IICBVC_20ms_Group03_Reserved3";
BA_ "SysSignalName" SG_ 497 IICBVC_20ms_Group03_Reserved3 "ICBVC_20ms_Group03_Reserved3";
BA_ "CompuMethodName" SG_ 497 IVehMd "VehMd";
BA_ "ISignalName" SG_ 497 IVehMd "IVehMd";
BA_ "LongName" SG_ 497 IVehMd "Vehicle Mode";
BA_ "SysSignalName" SG_ 497 IVehMd "VehMd";
BA_ "CompuMethodName" SG_ 497 ISysVolV "SysVolV";
BA_ "ISignalName" SG_ 497 ISysVolV "ISysVolV";
BA_ "LongName" SG_ 497 ISysVolV "System Voltage Validity";
BA_ "SysSignalName" SG_ 497 ISysVolV "SysVolV";
BA_ "CompuMethodName" SG_ 497 ISysPwrMdV "SysPwrMdV";
BA_ "GenSigStartValue" SG_ 497 ISysPwrMdV 1;
BA_ "ISignalName" SG_ 497 ISysPwrMdV "ISysPwrMdV";
BA_ "LongName" SG_ 497 ISysPwrMdV "System Power Mode Validity";
BA_ "SysSignalName" SG_ 497 ISysPwrMdV "SysPwrMdV";
BA_ "CompuMethodName" SG_ 497 IVehMdV "VehMdV";
BA_ "ISignalName" SG_ 497 IVehMdV "IVehMdV";
BA_ "LongName" SG_ 497 IVehMdV "Vehicle Mode Validity";
BA_ "SysSignalName" SG_ 497 IVehMdV "VehMdV";
BA_ "CompuMethodName" SG_ 497 IUsgMdV "UsgMdV";
BA_ "ISignalName" SG_ 497 IUsgMdV "IUsgMdV";
BA_ "LongName" SG_ 497 IUsgMdV "Usage Mode Validity";
BA_ "SysSignalName" SG_ 497 IUsgMdV "UsgMdV";
BA_ "CompuMethodName" SG_ 497 IUsgMd "UsgMd";
BA_ "GenSigStartValue" SG_ 497 IUsgMd 1;
BA_ "ISignalName" SG_ 497 IUsgMd "IUsgMd";
BA_ "LongName" SG_ 497 IUsgMd "Usage Mode";
BA_ "SysSignalName" SG_ 497 IUsgMd "UsgMd";
BA_ "CompuMethodName" SG_ 497 ISysVol "SysVol";
BA_ "ISignalName" SG_ 497 ISysVol "ISysVol";
BA_ "LongName" SG_ 497 ISysVol "System Voltage";
BA_ "SysSignalName" SG_ 497 ISysVol "SysVol";
BA_ "CompuMethodName" SG_ 497 IPwrMdMstrRunCrkA "PwrMdMstrRunCrkA";
BA_ "ISignalName" SG_ 497 IPwrMdMstrRunCrkA "IPwrMdMstrRunCrkA";
BA_ "LongName" SG_ 497 IPwrMdMstrRunCrkA "Power_Mode_Master_Run_Crank_Active";
BA_ "SysSignalName" SG_ 497 IPwrMdMstrRunCrkA "PwrMdMstrRunCrkA";
BA_ "CompuMethodName" SG_ 497 ISysPwrMd "SysPwrMd";
BA_ "ISignalName" SG_ 497 ISysPwrMd "ISysPwrMd";
BA_ "LongName" SG_ 497 ISysPwrMd "System Power Mode";
BA_ "SysSignalName" SG_ 497 ISysPwrMd "SysPwrMd";
BA_ "CompuMethodName" SG_ 497 IPwrMdMstrAccryA "PwrMdMstrAccryA";
BA_ "ISignalName" SG_ 497 IPwrMdMstrAccryA "IPwrMdMstrAccryA";
BA_ "LongName" SG_ 497 IPwrMdMstrAccryA "Power_Mode_Master_Accessory_Active";
BA_ "SysSignalName" SG_ 497 IPwrMdMstrAccryA "PwrMdMstrAccryA";
BA_ "CompuMethodName" SG_ 497 ISysOpnlMd "SysOpnlMd";
BA_ "ISignalName" SG_ 497 ISysOpnlMd "ISysOpnlMd";
BA_ "LongName" SG_ 497 ISysOpnlMd "System Operational Mode";
BA_ "SysSignalName" SG_ 497 ISysOpnlMd "SysOpnlMd";
BA_ "CompuMethodName" SG_ 497 IICBVC_20ms_Group03_Reserved4 "ICBVC_20ms_Group03_Reserved4";
BA_ "GenSigStartValue" SG_ 497 IICBVC_20ms_Group03_Reserved4 31;
BA_ "ISignalName" SG_ 497 IICBVC_20ms_Group03_Reserved4 "IICBVC_20ms_Group03_Reserved4";
BA_ "SysSignalName" SG_ 497 IICBVC_20ms_Group03_Reserved4 "ICBVC_20ms_Group03_Reserved4";
BA_ "CompuMethodName" SG_ 497 IBPMMstrAvlbly "BPMMstrAvlbly";
BA_ "ISignalName" SG_ 497 IBPMMstrAvlbly "IBPMMstrAvlbly";
BA_ "LongName" SG_ 497 IBPMMstrAvlbly "Backup_Power_Mode_Master_Availability";
BA_ "SysSignalName" SG_ 497 IBPMMstrAvlbly "BPMMstrAvlbly";
BA_ "CompuMethodName" SG_ 497 ISysVolMd "SysVolMd";
BA_ "ISignalName" SG_ 497 ISysVolMd "ISysVolMd";
BA_ "LongName" SG_ 497 ISysVolMd "System Voltage Mode";
BA_ "SysSignalName" SG_ 497 ISysVolMd "SysVolMd";
BA_ "CompuMethodName" SG_ 60 ITripCntResetReq "TripCntResetReq";
BA_ "ISignalName" SG_ 60 ITripCntResetReq "ITripCntResetReq";
BA_ "LongName" SG_ 60 ITripCntResetReq "Trip Counter Reset Request";
BA_ "SysSignalName" SG_ 60 ITripCntResetReq "TripCntResetReq";
BA_ "CompuMethodName" SG_ 60 IComKeyEnbReq "ComKeyEnbReq";
BA_ "ISignalName" SG_ 60 IComKeyEnbReq "IComKeyEnbReq";
BA_ "LongName" SG_ 60 IComKeyEnbReq "Communication Key Enable Request";
BA_ "SysSignalName" SG_ 60 IComKeyEnbReq "ComKeyEnbReq";
BA_ "CompuMethodName" SG_ 1391 ITripCnt "TripCnt";
BA_ "GenSigStartValue" SG_ 1391 ITripCnt 1;
BA_ "ISignalName" SG_ 1391 ITripCnt "ITripCnt";
BA_ "LongName" SG_ 1391 ITripCnt "Trip Counter";
BA_ "SysSignalName" SG_ 1391 ITripCnt "TripCnt";
BA_ "CompuMethodName" SG_ 1391 IResetCnt "ResetCnt";
BA_ "GenSigStartValue" SG_ 1391 IResetCnt 1;
BA_ "ISignalName" SG_ 1391 IResetCnt "IResetCnt";
BA_ "LongName" SG_ 1391 IResetCnt "Reset Counter";
BA_ "SysSignalName" SG_ 1391 IResetCnt "ResetCnt";
BA_ "CompuMethodName" SG_ 815 IEGCMPwrSts "EGCMPwrSts";
BA_ "ISignalName" SG_ 815 IEGCMPwrSts "IEGCMPwrSts";
BA_ "LongName" SG_ 815 IEGCMPwrSts "EGCM Power Status";
BA_ "SysSignalName" SG_ 815 IEGCMPwrSts "EGCMPwrSts";
BA_ "CompuMethodName" SG_ 815 IESCLPwrSts "ESCLPwrSts";
BA_ "ISignalName" SG_ 815 IESCLPwrSts "IESCLPwrSts";
BA_ "LongName" SG_ 815 IESCLPwrSts "ESCL Power Status";
BA_ "SysSignalName" SG_ 815 IESCLPwrSts "ESCLPwrSts";
BA_ "CompuMethodName" SG_ 815 IBPEPSPwrSts "BPEPSPwrSts";
BA_ "ISignalName" SG_ 815 IBPEPSPwrSts "IBPEPSPwrSts";
BA_ "LongName" SG_ 815 IBPEPSPwrSts "BPEPS Power Status";
BA_ "SysSignalName" SG_ 815 IBPEPSPwrSts "BPEPSPwrSts";
BA_ "CompuMethodName" SG_ 815 IRoofDspPwrSts "RoofDspPwrSts";
BA_ "ISignalName" SG_ 815 IRoofDspPwrSts "IRoofDspPwrSts";
BA_ "LongName" SG_ 815 IRoofDspPwrSts "RoofDsp Power Status";
BA_ "SysSignalName" SG_ 815 IRoofDspPwrSts "RoofDspPwrSts";
BA_ "CompuMethodName" SG_ 815 ILHAmbtLampPwrSts "LHAmbtLampPwrSts";
BA_ "ISignalName" SG_ 815 ILHAmbtLampPwrSts "ILHAmbtLampPwrSts";
BA_ "LongName" SG_ 815 ILHAmbtLampPwrSts "LHAmbtLamp Power Status";
BA_ "SysSignalName" SG_ 815 ILHAmbtLampPwrSts "LHAmbtLampPwrSts";
BA_ "CompuMethodName" SG_ 815 IOHCPwrSts "OHCPwrSts";
BA_ "ISignalName" SG_ 815 IOHCPwrSts "IOHCPwrSts";
BA_ "LongName" SG_ 815 IOHCPwrSts "OHC Power Status";
BA_ "SysSignalName" SG_ 815 IOHCPwrSts "OHCPwrSts";
BA_ "CompuMethodName" SG_ 815 ICnsoDspPwrSts "CnsoDspPwrSts";
BA_ "ISignalName" SG_ 815 ICnsoDspPwrSts "ICnsoDspPwrSts";
BA_ "LongName" SG_ 815 ICnsoDspPwrSts "CnsoDsp Power Status";
BA_ "SysSignalName" SG_ 815 ICnsoDspPwrSts "CnsoDspPwrSts";
BA_ "CompuMethodName" SG_ 815 IFLVntngMotPwrSts "FLVntngMotPwrSts";
BA_ "ISignalName" SG_ 815 IFLVntngMotPwrSts "IFLVntngMotPwrSts";
BA_ "LongName" SG_ 815 IFLVntngMotPwrSts "FLVntngMot Power Status";
BA_ "SysSignalName" SG_ 815 IFLVntngMotPwrSts "FLVntngMotPwrSts";
BA_ "CompuMethodName" SG_ 815 IFLSLMMPwrSts "FLSLMMPwrSts";
BA_ "ISignalName" SG_ 815 IFLSLMMPwrSts "IFLSLMMPwrSts";
BA_ "LongName" SG_ 815 IFLSLMMPwrSts "FLSLMM Power Status";
BA_ "SysSignalName" SG_ 815 IFLSLMMPwrSts "FLSLMMPwrSts";
BA_ "CompuMethodName" SG_ 815 IUSBHubPwrSts "USBHubPwrSts";
BA_ "ISignalName" SG_ 815 IUSBHubPwrSts "IUSBHubPwrSts";
BA_ "LongName" SG_ 815 IUSBHubPwrSts "USBHub Power Status";
BA_ "SysSignalName" SG_ 815 IUSBHubPwrSts "USBHubPwrSts";
BA_ "CompuMethodName" SG_ 815 IDrvrDspPwrSts "DrvrDspPwrSts";
BA_ "ISignalName" SG_ 815 IDrvrDspPwrSts "IDrvrDspPwrSts";
BA_ "LongName" SG_ 815 IDrvrDspPwrSts "DrvrDsp Power Status";
BA_ "SysSignalName" SG_ 815 IDrvrDspPwrSts "DrvrDspPwrSts";
BA_ "CompuMethodName" SG_ 815 ISWSPwrSts "SWSPwrSts";
BA_ "ISignalName" SG_ 815 ISWSPwrSts "ISWSPwrSts";
BA_ "LongName" SG_ 815 ISWSPwrSts "LHSWS Power Status";
BA_ "SysSignalName" SG_ 815 ISWSPwrSts "SWSPwrSts";
BA_ "CompuMethodName" SG_ 815 IBrkSwPwrSts "BrkSwPwrSts";
BA_ "ISignalName" SG_ 815 IBrkSwPwrSts "IBrkSwPwrSts";
BA_ "LongName" SG_ 815 IBrkSwPwrSts "BrkSw Power Status";
BA_ "SysSignalName" SG_ 815 IBrkSwPwrSts "BrkSwPwrSts";
BA_ "CompuMethodName" SG_ 815 IHODMPwrSts "HODMPwrSts";
BA_ "ISignalName" SG_ 815 IHODMPwrSts "IHODMPwrSts";
BA_ "LongName" SG_ 815 IHODMPwrSts "HODM Power Status";
BA_ "SysSignalName" SG_ 815 IHODMPwrSts "HODMPwrSts";
BA_ "CompuMethodName" SG_ 815 IRLSSPwrSts "RLSSPwrSts";
BA_ "ISignalName" SG_ 815 IRLSSPwrSts "IRLSSPwrSts";
BA_ "LongName" SG_ 815 IRLSSPwrSts "RLSS Power Status";
BA_ "SysSignalName" SG_ 815 IRLSSPwrSts "RLSSPwrSts";
BA_ "CompuMethodName" SG_ 815 IETCMPwrSts "ETCMPwrSts";
BA_ "ISignalName" SG_ 815 IETCMPwrSts "IETCMPwrSts";
BA_ "LongName" SG_ 815 IETCMPwrSts "ETCM Power Status";
BA_ "SysSignalName" SG_ 815 IETCMPwrSts "ETCMPwrSts";
BA_ "CompuMethodName" SG_ 815 ILHSWPwrSts "LHSWPwrSts";
BA_ "ISignalName" SG_ 815 ILHSWPwrSts "ILHSWPwrSts";
BA_ "LongName" SG_ 815 ILHSWPwrSts "LHSW Power Status";
BA_ "SysSignalName" SG_ 815 ILHSWPwrSts "LHSWPwrSts";
BA_ "CompuMethodName" SG_ 815 INFCAMPwrSts "NFCAMPwrSts";
BA_ "ISignalName" SG_ 815 INFCAMPwrSts "INFCAMPwrSts";
BA_ "LongName" SG_ 815 INFCAMPwrSts "NFCAM Power Status";
BA_ "SysSignalName" SG_ 815 INFCAMPwrSts "NFCAMPwrSts";
BA_ "CompuMethodName" SG_ 815 INFCSMPwrSts "NFCSMPwrSts";
BA_ "ISignalName" SG_ 815 INFCSMPwrSts "INFCSMPwrSts";
BA_ "LongName" SG_ 815 INFCSMPwrSts "NFCSM Power Status";
BA_ "SysSignalName" SG_ 815 INFCSMPwrSts "NFCSMPwrSts";
BA_ "CompuMethodName" SG_ 815 IPriEarPwrSts "PriEarPwrSts";
BA_ "ISignalName" SG_ 815 IPriEarPwrSts "IPriEarPwrSts";
BA_ "LongName" SG_ 815 IPriEarPwrSts "PriEar Power Status";
BA_ "SysSignalName" SG_ 815 IPriEarPwrSts "PriEarPwrSts";
BA_ "CompuMethodName" SG_ 815 ICnsoUSBPwrSts "CnsoUSBPwrSts";
BA_ "ISignalName" SG_ 815 ICnsoUSBPwrSts "ICnsoUSBPwrSts";
BA_ "LongName" SG_ 815 ICnsoUSBPwrSts "CnsoUSB Power Status";
BA_ "SysSignalName" SG_ 815 ICnsoUSBPwrSts "CnsoUSBPwrSts";
BA_ "CompuMethodName" SG_ 815 IRrPDCPwrSts "RrPDCPwrSts";
BA_ "ISignalName" SG_ 815 IRrPDCPwrSts "IRrPDCPwrSts";
BA_ "LongName" SG_ 815 IRrPDCPwrSts "RrPDC Power Status";
BA_ "SysSignalName" SG_ 815 IRrPDCPwrSts "RrPDCPwrSts";
BA_ "CompuMethodName" SG_ 815 IFrtPDCPwrSts "FrtPDCPwrSts";
BA_ "ISignalName" SG_ 815 IFrtPDCPwrSts "IFrtPDCPwrSts";
BA_ "LongName" SG_ 815 IFrtPDCPwrSts "FrtPDC Power Status";
BA_ "SysSignalName" SG_ 815 IFrtPDCPwrSts "FrtPDCPwrSts";
BA_ "CompuMethodName" SG_ 815 IFVCMPwrSts "FVCMPwrSts";
BA_ "ISignalName" SG_ 815 IFVCMPwrSts "IFVCMPwrSts";
BA_ "LongName" SG_ 815 IFVCMPwrSts "FVCM Power Status";
BA_ "SysSignalName" SG_ 815 IFVCMPwrSts "FVCMPwrSts";
BA_ "CompuMethodName" SG_ 815 IHVDCDCPwrSts "HVDCDCPwrSts";
BA_ "ISignalName" SG_ 815 IHVDCDCPwrSts "IHVDCDCPwrSts";
BA_ "LongName" SG_ 815 IHVDCDCPwrSts "HVDCDC Power Status";
BA_ "SysSignalName" SG_ 815 IHVDCDCPwrSts "HVDCDCPwrSts";
BA_ "CompuMethodName" SG_ 815 ITPMSPwrSts "TPMSPwrSts";
BA_ "ISignalName" SG_ 815 ITPMSPwrSts "ITPMSPwrSts";
BA_ "LongName" SG_ 815 ITPMSPwrSts "TPMS Power Status";
BA_ "SysSignalName" SG_ 815 ITPMSPwrSts "TPMSPwrSts";
BA_ "CompuMethodName" SG_ 815 IAIBOXPwrSts "AIBOXPwrSts";
BA_ "ISignalName" SG_ 815 IAIBOXPwrSts "IAIBOXPwrSts";
BA_ "LongName" SG_ 815 IAIBOXPwrSts "AIBOX Power Status";
BA_ "SysSignalName" SG_ 815 IAIBOXPwrSts "AIBOXPwrSts";
BA_ "CompuMethodName" SG_ 815 IAIBOTPwrSts "AIBOTPwrSts";
BA_ "ISignalName" SG_ 815 IAIBOTPwrSts "IAIBOTPwrSts";
BA_ "LongName" SG_ 815 IAIBOTPwrSts "AIBOT Power Status";
BA_ "SysSignalName" SG_ 815 IAIBOTPwrSts "AIBOTPwrSts";
BA_ "CompuMethodName" SG_ 902 IDircnLghtMdSet "DircnLghtMdSet";
BA_ "ISignalName" SG_ 902 IDircnLghtMdSet "IDircnLghtMdSet";
BA_ "LongName" SG_ 902 IDircnLghtMdSet "Driection Light Mode Set";
BA_ "SysSignalName" SG_ 902 IDircnLghtMdSet "DircnLghtMdSet";
BA_ "CompuMethodName" SG_ 902 IComfortDircnLghtSet "ComfortDircnLghtSet";
BA_ "ISignalName" SG_ 902 IComfortDircnLghtSet "IComfortDircnLghtSet";
BA_ "LongName" SG_ 902 IComfortDircnLghtSet "Comfortable Direction Light Set";
BA_ "SysSignalName" SG_ 902 IComfortDircnLghtSet "ComfortDircnLghtSet";
BA_ "CompuMethodName" SG_ 902 ILbl1FrgrLife "Lbl1FrgrLife";
BA_ "GenSigStartValue" SG_ 902 ILbl1FrgrLife 255;
BA_ "ISignalName" SG_ 902 ILbl1FrgrLife "ILbl1FrgrLife";
BA_ "LongName" SG_ 902 ILbl1FrgrLife "Label 1 Fragrance Life";
BA_ "SysSignalName" SG_ 902 ILbl1FrgrLife "Lbl1FrgrLife";
BA_ "CompuMethodName" SG_ 902 ILbl2FrgrLife "Lbl2FrgrLife";
BA_ "GenSigStartValue" SG_ 902 ILbl2FrgrLife 255;
BA_ "ISignalName" SG_ 902 ILbl2FrgrLife "ILbl2FrgrLife";
BA_ "LongName" SG_ 902 ILbl2FrgrLife "Label 2 Fragrance Life";
BA_ "SysSignalName" SG_ 902 ILbl2FrgrLife "Lbl2FrgrLife";
BA_ "CompuMethodName" SG_ 902 ILbl3FrgrLife "Lbl3FrgrLife";
BA_ "GenSigStartValue" SG_ 902 ILbl3FrgrLife 255;
BA_ "ISignalName" SG_ 902 ILbl3FrgrLife "ILbl3FrgrLife";
BA_ "LongName" SG_ 902 ILbl3FrgrLife "Label 3 Fragrance Life";
BA_ "SysSignalName" SG_ 902 ILbl3FrgrLife "Lbl3FrgrLife";
BA_ "CompuMethodName" SG_ 902 ILbl1FrgrAvlbl "Lbl1FrgrAvlbl";
BA_ "ISignalName" SG_ 902 ILbl1FrgrAvlbl "ILbl1FrgrAvlbl";
BA_ "LongName" SG_ 902 ILbl1FrgrAvlbl "Label_1_Fragrance_Available";
BA_ "SysSignalName" SG_ 902 ILbl1FrgrAvlbl "Lbl1FrgrAvlbl";
BA_ "CompuMethodName" SG_ 902 ILbl2FrgrAvlbl "Lbl2FrgrAvlbl";
BA_ "ISignalName" SG_ 902 ILbl2FrgrAvlbl "ILbl2FrgrAvlbl";
BA_ "LongName" SG_ 902 ILbl2FrgrAvlbl "Label_2_Fragrance_Available";
BA_ "SysSignalName" SG_ 902 ILbl2FrgrAvlbl "Lbl2FrgrAvlbl";
BA_ "CompuMethodName" SG_ 902 ILbl3FrgrAvlbl "Lbl3FrgrAvlbl";
BA_ "ISignalName" SG_ 902 ILbl3FrgrAvlbl "ILbl3FrgrAvlbl";
BA_ "LongName" SG_ 902 ILbl3FrgrAvlbl "Label_3_Fragrance_Available";
BA_ "SysSignalName" SG_ 902 ILbl3FrgrAvlbl "Lbl3FrgrAvlbl";
BA_ "CompuMethodName" SG_ 902 IAVPMapRutMgIDtReq "AVPMapRutMgIDtReq";
BA_ "ISignalName" SG_ 902 IAVPMapRutMgIDtReq "IAVPMapRutMgIDtReq";
BA_ "LongName" SG_ 902 IAVPMapRutMgIDtReq "AVP Map  Route Management  ID Requst";
BA_ "SysSignalName" SG_ 902 IAVPMapRutMgIDtReq "AVPMapRutMgIDtReq";
BA_ "CompuMethodName" SG_ 902 IFrgrLblReqRut "FrgrLblReqRut";
BA_ "ISignalName" SG_ 902 IFrgrLblReqRut "IFrgrLblReqRut";
BA_ "LongName" SG_ 902 IFrgrLblReqRut "Fragrance Label Request Route";
BA_ "SysSignalName" SG_ 902 IFrgrLblReqRut "FrgrLblReqRut";
BA_ "CompuMethodName" SG_ 902 IAdupConSwReq "AdupConSwReq";
BA_ "ISignalName" SG_ 902 IAdupConSwReq "IAdupConSwReq";
BA_ "LongName" SG_ 902 IAdupConSwReq "AD_Problems_upload_Confirm_Switch_Request";
BA_ "SysSignalName" SG_ 902 IAdupConSwReq "AdupConSwReq";
BA_ "CompuMethodName" SG_ 902 IAdupSwReq "AdupSwReq";
BA_ "ISignalName" SG_ 902 IAdupSwReq "IAdupSwReq";
BA_ "LongName" SG_ 902 IAdupSwReq "AD_Problems_upload_Switch_Request";
BA_ "SysSignalName" SG_ 902 IAdupSwReq "AdupSwReq";
BA_ "CompuMethodName" SG_ 902 IRBFSwReq "RBFSwReq";
BA_ "ISignalName" SG_ 902 IRBFSwReq "IRBFSwReq";
BA_ "LongName" SG_ 902 IRBFSwReq "RBF_Switch_Request";
BA_ "SysSignalName" SG_ 902 IRBFSwReq "RBFSwReq";
BA_ "CompuMethodName" SG_ 902 IRCWSnstvtLvlReq "RCWSnstvtLvlReq";
BA_ "ISignalName" SG_ 902 IRCWSnstvtLvlReq "IRCWSnstvtLvlReq";
BA_ "LongName" SG_ 902 IRCWSnstvtLvlReq "RCW_Sensitivity_Level_Request";
BA_ "SysSignalName" SG_ 902 IRCWSnstvtLvlReq "RCWSnstvtLvlReq";
BA_ "CompuMethodName" SG_ 902 ISpdLmtCotOverWrnngSwReq "SpdLmtCotOverWrnngSwReq";
BA_ "ISignalName" SG_ 902 ISpdLmtCotOverWrnngSwReq "ISpdLmtCotOverWrnngSwReq";
BA_ "LongName" SG_ 902 ISpdLmtCotOverWrnngSwReq "Speed Limit Control Over Warning Switch Request";
BA_ "SysSignalName" SG_ 902 ISpdLmtCotOverWrnngSwReq "SpdLmtCotOverWrnngSwReq";
BA_ "CompuMethodName" SG_ 902 ITollgatePreReq "TollgatePreReq";
BA_ "ISignalName" SG_ 902 ITollgatePreReq "ITollgatePreReq";
BA_ "LongName" SG_ 902 ITollgatePreReq "Tollgate Preference Request";
BA_ "SysSignalName" SG_ 902 ITollgatePreReq "TollgatePreReq";
BA_ "CompuMethodName" SG_ 902 IHODMdlReq "HODMdlReq";
BA_ "ISignalName" SG_ 902 IHODMdlReq "IHODMdlReq";
BA_ "LongName" SG_ 902 IHODMdlReq "HOD Model Request";
BA_ "SysSignalName" SG_ 902 IHODMdlReq "HODMdlReq";
BA_ "CompuMethodName" SG_ 902 IMemParkngSilentPatrolSwReq "MemParkngSilentPatrolSwReq";
BA_ "ISignalName" SG_ 902 IMemParkngSilentPatrolSwReq "IMemParkngSilentPatrolSwReq";
BA_ "LongName" SG_ 902 IMemParkngSilentPatrolSwReq "Mem Parkng Silent Patrol Req";
BA_ "SysSignalName" SG_ 902 IMemParkngSilentPatrolSwReq "MemParkngSilentPatrolSwReq";
BA_ "CompuMethodName" SG_ 902 IIPDPowerFailSwReq "IPDPowerFailSwReq";
BA_ "ISignalName" SG_ 902 IIPDPowerFailSwReq "IIPDPowerFailSwReq";
BA_ "LongName" SG_ 902 IIPDPowerFailSwReq "IPD_Power_Faile_Switch_Request";
BA_ "SysSignalName" SG_ 902 IIPDPowerFailSwReq "IPDPowerFailSwReq";
BA_ "CompuMethodName" SG_ 902 IAVPUpdateMapReq "AVPUpdateMapReq";
BA_ "ISignalName" SG_ 902 IAVPUpdateMapReq "IAVPUpdateMapReq";
BA_ "LongName" SG_ 902 IAVPUpdateMapReq "AVP Update Map Request";
BA_ "SysSignalName" SG_ 902 IAVPUpdateMapReq "AVPUpdateMapReq";
BA_ "CompuMethodName" SG_ 902 IAVPMapRutMgtReq "AVPMapRutMgtReq";
BA_ "ISignalName" SG_ 902 IAVPMapRutMgtReq "IAVPMapRutMgtReq";
BA_ "LongName" SG_ 902 IAVPMapRutMgtReq "AVP Map Route Management Requst";
BA_ "SysSignalName" SG_ 902 IAVPMapRutMgtReq "AVPMapRutMgtReq";
BA_ "CompuMethodName" SG_ 902 IAIPilotMdlReq "AIPilotMdlReq";
BA_ "ISignalName" SG_ 902 IAIPilotMdlReq "IAIPilotMdlReq";
BA_ "LongName" SG_ 902 IAIPilotMdlReq "AI Pilot Model Request";
BA_ "SysSignalName" SG_ 902 IAIPilotMdlReq "AIPilotMdlReq";
BA_ "CompuMethodName" SG_ 902 ILbl1FrgrExpiryFlg "Lbl1FrgrExpiryFlg";
BA_ "ISignalName" SG_ 902 ILbl1FrgrExpiryFlg "ILbl1FrgrExpiryFlg";
BA_ "LongName" SG_ 902 ILbl1FrgrExpiryFlg "Label 1 Fragrance Expiry Flag";
BA_ "SysSignalName" SG_ 902 ILbl1FrgrExpiryFlg "Lbl1FrgrExpiryFlg";
BA_ "CompuMethodName" SG_ 902 IRPAActMethSwReq "RPAActMethSwReq";
BA_ "ISignalName" SG_ 902 IRPAActMethSwReq "IRPAActMethSwReq";
BA_ "LongName" SG_ 902 IRPAActMethSwReq "RPA Active Method Requirement";
BA_ "SysSignalName" SG_ 902 IRPAActMethSwReq "RPAActMethSwReq";
BA_ "CompuMethodName" SG_ 902 IUsPrReportReq "UsPrReportReq";
BA_ "ISignalName" SG_ 902 IUsPrReportReq "IUsPrReportReq";
BA_ "LongName" SG_ 902 IUsPrReportReq "User initiated problem reporting function request";
BA_ "SysSignalName" SG_ 902 IUsPrReportReq "UsPrReportReq";
BA_ "CompuMethodName" SG_ 902 IRACtlReq "RACtlReq";
BA_ "ISignalName" SG_ 902 IRACtlReq "IRACtlReq";
BA_ "LongName" SG_ 902 IRACtlReq "Reverse Assist Contro Requst";
BA_ "SysSignalName" SG_ 902 IRACtlReq "RACtlReq";
BA_ "CompuMethodName" SG_ 902 IDriverSightDstrctnMonWarning "DriverSightDstrctnMonWarning";
BA_ "ISignalName" SG_ 902 IDriverSightDstrctnMonWarning "IDriverSightDstrctnMonWarning";
BA_ "LongName" SG_ 902 IDriverSightDstrctnMonWarning "Driver Sight Distraction Warning";
BA_ "SysSignalName" SG_ 902 IDriverSightDstrctnMonWarning "DriverSightDstrctnMonWarning";
BA_ "CompuMethodName" SG_ 902 IFatigueMonitorWarning "FatigueMonitorWarning";
BA_ "ISignalName" SG_ 902 IFatigueMonitorWarning "IFatigueMonitorWarning";
BA_ "LongName" SG_ 902 IFatigueMonitorWarning "Driver Fatigue Warning";
BA_ "SysSignalName" SG_ 902 IFatigueMonitorWarning "FatigueMonitorWarning";
BA_ "CompuMethodName" SG_ 902 IFrgrCncntrnReqRut "FrgrCncntrnReqRut";
BA_ "ISignalName" SG_ 902 IFrgrCncntrnReqRut "IFrgrCncntrnReqRut";
BA_ "LongName" SG_ 902 IFrgrCncntrnReqRut "Fragrance Concentration Request Route";
BA_ "SysSignalName" SG_ 902 IFrgrCncntrnReqRut "FrgrCncntrnReqRut";
BA_ "CompuMethodName" SG_ 902 IShwrmComprEnbReq "ShwrmComprEnbReq";
BA_ "ISignalName" SG_ 902 IShwrmComprEnbReq "IShwrmComprEnbReq";
BA_ "LongName" SG_ 902 IShwrmComprEnbReq "Showroom_Compressor_Enable_Request";
BA_ "SysSignalName" SG_ 902 IShwrmComprEnbReq "ShwrmComprEnbReq";
BA_ "CompuMethodName" SG_ 902 ILbl3FrgrExpiryFlg "Lbl3FrgrExpiryFlg";
BA_ "ISignalName" SG_ 902 ILbl3FrgrExpiryFlg "ILbl3FrgrExpiryFlg";
BA_ "LongName" SG_ 902 ILbl3FrgrExpiryFlg "Label 3 Fragrance Expiry Flag";
BA_ "SysSignalName" SG_ 902 ILbl3FrgrExpiryFlg "Lbl3FrgrExpiryFlg";
BA_ "CompuMethodName" SG_ 902 ILbl2FrgrExpiryFlg "Lbl2FrgrExpiryFlg";
BA_ "ISignalName" SG_ 902 ILbl2FrgrExpiryFlg "ILbl2FrgrExpiryFlg";
BA_ "LongName" SG_ 902 ILbl2FrgrExpiryFlg "Label 2 Fragrance Expiry Flag";
BA_ "SysSignalName" SG_ 902 ILbl2FrgrExpiryFlg "Lbl2FrgrExpiryFlg";
BA_ "CompuMethodName" SG_ 902 ISrfOpenSts "SrfOpenSts";
BA_ "GenSigStartValue" SG_ 902 ISrfOpenSts 4;
BA_ "ISignalName" SG_ 902 ISrfOpenSts "ISrfOpenSts";
BA_ "LongName" SG_ 902 ISrfOpenSts "Sunroof Open Status";
BA_ "SysSignalName" SG_ 902 ISrfOpenSts "SrfOpenSts";
BA_ "CompuMethodName" SG_ 955 IACCTJAMdSwReq "ACCTJAMdSwReq";
BA_ "ISignalName" SG_ 955 IACCTJAMdSwReq "IACCTJAMdSwReq";
BA_ "LongName" SG_ 955 IACCTJAMdSwReq "Adaptive_Cruise_Control_Traffic_Jam_Assist_Mode_Switch_Request";
BA_ "SysSignalName" SG_ 955 IACCTJAMdSwReq "ACCTJAMdSwReq";
BA_ "CompuMethodName" SG_ 955 IFICMACLTemReq "FICMACLTemReq";
BA_ "GenSigStartValue" SG_ 955 IFICMACLTemReq 31;
BA_ "ISignalName" SG_ 955 IFICMACLTemReq "IFICMACLTemReq";
BA_ "LongName" SG_ 955 IFICMACLTemReq "Front Infotainment Control Module Air Conditioning Left Temperature Request";
BA_ "SysSignalName" SG_ 955 IFICMACLTemReq "FICMACLTemReq";
BA_ "CompuMethodName" SG_ 955 ISpdLmtOfstSetReq "SpdLmtOfstSetReq";
BA_ "GenSigStartValue" SG_ 955 ISpdLmtOfstSetReq 63;
BA_ "ISignalName" SG_ 955 ISpdLmtOfstSetReq "ISpdLmtOfstSetReq";
BA_ "LongName" SG_ 955 ISpdLmtOfstSetReq "Speed Limit Offset Set Request";
BA_ "SysSignalName" SG_ 955 ISpdLmtOfstSetReq "SpdLmtOfstSetReq";
BA_ "CompuMethodName" SG_ 955 IACCStsSwReq "ACCStsSwReq";
BA_ "ISignalName" SG_ 955 IACCStsSwReq "IACCStsSwReq";
BA_ "LongName" SG_ 955 IACCStsSwReq "ACC status switch request";
BA_ "SysSignalName" SG_ 955 IACCStsSwReq "ACCStsSwReq";
BA_ "CompuMethodName" SG_ 955 IACCSpdLimtSwReq "ACCSpdLimtSwReq";
BA_ "ISignalName" SG_ 955 IACCSpdLimtSwReq "IACCSpdLimtSwReq";
BA_ "LongName" SG_ 955 IACCSpdLimtSwReq "ACC speed limit swtich request";
BA_ "SysSignalName" SG_ 955 IACCSpdLimtSwReq "ACCSpdLimtSwReq";
BA_ "CompuMethodName" SG_ 955 IACCConfmSwReq "ACCConfmSwReq";
BA_ "ISignalName" SG_ 955 IACCConfmSwReq "IACCConfmSwReq";
BA_ "LongName" SG_ 955 IACCConfmSwReq "ACC confirm 
  switch request";
BA_ "SysSignalName" SG_ 955 IACCConfmSwReq "ACCConfmSwReq";
BA_ "CompuMethodName" SG_ 955 IACUserCustEcoSetngReqV "ACUserCustEcoSetngReqV";
BA_ "GenSigStartValue" SG_ 955 IACUserCustEcoSetngReqV 1;
BA_ "ISignalName" SG_ 955 IACUserCustEcoSetngReqV "IACUserCustEcoSetngReqV";
BA_ "LongName" SG_ 955 IACUserCustEcoSetngReqV "Air Conditioning User Customization Economy Setting Request Validity";
BA_ "SysSignalName" SG_ 955 IACUserCustEcoSetngReqV "ACUserCustEcoSetngReqV";
BA_ "CompuMethodName" SG_ 955 IACUserCustEcoSetngReq "ACUserCustEcoSetngReq";
BA_ "ISignalName" SG_ 955 IACUserCustEcoSetngReq "IACUserCustEcoSetngReq";
BA_ "LongName" SG_ 955 IACUserCustEcoSetngReq "Air Conditioning User Customization Economy Setting Request";
BA_ "SysSignalName" SG_ 955 IACUserCustEcoSetngReq "ACUserCustEcoSetngReq";
BA_ "CompuMethodName" SG_ 955 IACUserCustAutoMdBlwrReqV "ACUserCustAutoMdBlwrReqV";
BA_ "GenSigStartValue" SG_ 955 IACUserCustAutoMdBlwrReqV 1;
BA_ "ISignalName" SG_ 955 IACUserCustAutoMdBlwrReqV "IACUserCustAutoMdBlwrReqV";
BA_ "LongName" SG_ 955 IACUserCustAutoMdBlwrReqV "Air Conditioning User Customization Auto Mode Blower Request Validity";
BA_ "SysSignalName" SG_ 955 IACUserCustAutoMdBlwrReqV "ACUserCustAutoMdBlwrReqV";
BA_ "CompuMethodName" SG_ 955 IACUserCustAutoMdBlwrReq "ACUserCustAutoMdBlwrReq";
BA_ "GenSigStartValue" SG_ 955 IACUserCustAutoMdBlwrReq 1;
BA_ "ISignalName" SG_ 955 IACUserCustAutoMdBlwrReq "IACUserCustAutoMdBlwrReq";
BA_ "LongName" SG_ 955 IACUserCustAutoMdBlwrReq "Air Conditioning User Customization Auto Mode Blower Request";
BA_ "SysSignalName" SG_ 955 IACUserCustAutoMdBlwrReq "ACUserCustAutoMdBlwrReq";
BA_ "CompuMethodName" SG_ 955 IACUserCustAftRunOnOffReqV "ACUserCustAftRunOnOffReqV";
BA_ "GenSigStartValue" SG_ 955 IACUserCustAftRunOnOffReqV 1;
BA_ "ISignalName" SG_ 955 IACUserCustAftRunOnOffReqV "IACUserCustAftRunOnOffReqV";
BA_ "LongName" SG_ 955 IACUserCustAftRunOnOffReqV "Air Conditioning User Customization After Run On Off Request Valid";
BA_ "SysSignalName" SG_ 955 IACUserCustAftRunOnOffReqV "ACUserCustAftRunOnOffReqV";
BA_ "CompuMethodName" SG_ 955 IACUserCustAftRunOnOffR "ACUserCustAftRunOnOffR";
BA_ "ISignalName" SG_ 955 IACUserCustAftRunOnOffR "IACUserCustAftRunOnOffR";
BA_ "LongName" SG_ 955 IACUserCustAftRunOnOffR "Air Conditioning User Customization After Run On Off Right";
BA_ "SysSignalName" SG_ 955 IACUserCustAftRunOnOffR "ACUserCustAftRunOnOffR";
BA_ "CompuMethodName" SG_ 955 IFICMACFrtBlwrSpdDecSwR "FICMACFrtBlwrSpdDecSwR";
BA_ "ISignalName" SG_ 955 IFICMACFrtBlwrSpdDecSwR "IFICMACFrtBlwrSpdDecSwR";
BA_ "LongName" SG_ 955 IFICMACFrtBlwrSpdDecSwR "Front Infotainment Control Module Air Conditioning Front Blower Speed Decrease Switch Right";
BA_ "SysSignalName" SG_ 955 IFICMACFrtBlwrSpdDecSwR "FICMACFrtBlwrSpdDecSwR";
BA_ "CompuMethodName" SG_ 955 IFICMACAutoSwReq "FICMACAutoSwReq";
BA_ "ISignalName" SG_ 955 IFICMACAutoSwReq "IFICMACAutoSwReq";
BA_ "LongName" SG_ 955 IFICMACAutoSwReq "Front Infotainment Control Module Air Conditioning AUTO Switch Request";
BA_ "SysSignalName" SG_ 955 IFICMACAutoSwReq "FICMACAutoSwReq";
BA_ "CompuMethodName" SG_ 955 IFICMACLTemDecSwReq "FICMACLTemDecSwReq";
BA_ "ISignalName" SG_ 955 IFICMACLTemDecSwReq "IFICMACLTemDecSwReq";
BA_ "LongName" SG_ 955 IFICMACLTemDecSwReq "Front Infotainment Control Module Air Conditioning Left Temperature Decrease Switch Request";
BA_ "SysSignalName" SG_ 955 IFICMACLTemDecSwReq "FICMACLTemDecSwReq";
BA_ "CompuMethodName" SG_ 955 IFICMACFrtBlwrSpdIncSwR "FICMACFrtBlwrSpdIncSwR";
BA_ "ISignalName" SG_ 955 IFICMACFrtBlwrSpdIncSwR "IFICMACFrtBlwrSpdIncSwR";
BA_ "LongName" SG_ 955 IFICMACFrtBlwrSpdIncSwR "Front Infotainment Control Module Air Conditioning Front Blower Speed Increase Switch Right";
BA_ "SysSignalName" SG_ 955 IFICMACFrtBlwrSpdIncSwR "FICMACFrtBlwrSpdIncSwR";
BA_ "CompuMethodName" SG_ 955 IFICMACFrtBlwrLvlReq "FICMACFrtBlwrLvlReq";
BA_ "ISignalName" SG_ 955 IFICMACFrtBlwrLvlReq "IFICMACFrtBlwrLvlReq";
BA_ "LongName" SG_ 955 IFICMACFrtBlwrLvlReq "Front Infotainment Control Module Air Condition Front Blower Level Request";
BA_ "SysSignalName" SG_ 955 IFICMACFrtBlwrLvlReq "FICMACFrtBlwrLvlReq";
BA_ "CompuMethodName" SG_ 955 IFICMACOnOffSwReq "FICMACOnOffSwReq";
BA_ "ISignalName" SG_ 955 IFICMACOnOffSwReq "IFICMACOnOffSwReq";
BA_ "LongName" SG_ 955 IFICMACOnOffSwReq "Front Infotainment Control Module Air Condition On Off Switch Request";
BA_ "SysSignalName" SG_ 955 IFICMACOnOffSwReq "FICMACOnOffSwReq";
BA_ "CompuMethodName" SG_ 955 IFICMACLTemIncSwReq "FICMACLTemIncSwReq";
BA_ "ISignalName" SG_ 955 IFICMACLTemIncSwReq "IFICMACLTemIncSwReq";
BA_ "LongName" SG_ 955 IFICMACLTemIncSwReq "Front Infotainment Control Module Air Conditioning Left Temperature Increase Switch Request";
BA_ "SysSignalName" SG_ 955 IFICMACLTemIncSwReq "FICMACLTemIncSwReq";
BA_ "CompuMethodName" SG_ 955 IFICMACLAirMdReqV "FICMACLAirMdReqV";
BA_ "GenSigStartValue" SG_ 955 IFICMACLAirMdReqV 1;
BA_ "ISignalName" SG_ 955 IFICMACLAirMdReqV "IFICMACLAirMdReqV";
BA_ "LongName" SG_ 955 IFICMACLAirMdReqV "Front Infotainment Control Module Air Conditioning Left Air Mode Request Validity";
BA_ "SysSignalName" SG_ 955 IFICMACLAirMdReqV "FICMACLAirMdReqV";
BA_ "CompuMethodName" SG_ 955 IFICMACLAirMdReq "FICMACLAirMdReq";
BA_ "GenSigStartValue" SG_ 955 IFICMACLAirMdReq 7;
BA_ "ISignalName" SG_ 955 IFICMACLAirMdReq "IFICMACLAirMdReq";
BA_ "LongName" SG_ 955 IFICMACLAirMdReq "Front Infotainment Control Module Air Conditioning Left Air Mode Request";
BA_ "SysSignalName" SG_ 955 IFICMACLAirMdReq "FICMACLAirMdReq";
BA_ "CompuMethodName" SG_ 955 IFICMComprOnOffSwReq "FICMComprOnOffSwReq";
BA_ "ISignalName" SG_ 955 IFICMComprOnOffSwReq "IFICMComprOnOffSwReq";
BA_ "LongName" SG_ 955 IFICMComprOnOffSwReq "Front Infotainment Control Module Compressor On Off Switch Request";
BA_ "SysSignalName" SG_ 955 IFICMComprOnOffSwReq "FICMComprOnOffSwReq";
BA_ "CompuMethodName" SG_ 955 IFICMACSemiAutoSwReq "FICMACSemiAutoSwReq";
BA_ "ISignalName" SG_ 955 IFICMACSemiAutoSwReq "IFICMACSemiAutoSwReq";
BA_ "LongName" SG_ 955 IFICMACSemiAutoSwReq "Front Infotainment Control Module Air Conditioning Semi Auto Switch Request";
BA_ "SysSignalName" SG_ 955 IFICMACSemiAutoSwReq "FICMACSemiAutoSwReq";
BA_ "CompuMethodName" SG_ 955 IFICMACRcctnSwReq "FICMACRcctnSwReq";
BA_ "ISignalName" SG_ 955 IFICMACRcctnSwReq "IFICMACRcctnSwReq";
BA_ "LongName" SG_ 955 IFICMACRcctnSwReq "Front Infotainment Control Module Air Condition Recircution Switch Request";
BA_ "SysSignalName" SG_ 955 IFICMACRcctnSwReq "FICMACRcctnSwReq";
BA_ "CompuMethodName" SG_ 955 IFICMACRcctnMdReq "FICMACRcctnMdReq";
BA_ "ISignalName" SG_ 955 IFICMACRcctnMdReq "IFICMACRcctnMdReq";
BA_ "LongName" SG_ 955 IFICMACRcctnMdReq "Air Conditioning Recirculation Mode Req";
BA_ "SysSignalName" SG_ 955 IFICMACRcctnMdReq "FICMACRcctnMdReq";
BA_ "CompuMethodName" SG_ 955 IFICMHtdRrWndSwReq "FICMHtdRrWndSwReq";
BA_ "ISignalName" SG_ 955 IFICMHtdRrWndSwReq "IFICMHtdRrWndSwReq";
BA_ "LongName" SG_ 955 IFICMHtdRrWndSwReq "Front Infotainment Control Module Heated Rear Window Switch Request";
BA_ "SysSignalName" SG_ 955 IFICMHtdRrWndSwReq "FICMHtdRrWndSwReq";
BA_ "CompuMethodName" SG_ 955 IFICMDfstOnSwReq "FICMDfstOnSwReq";
BA_ "ISignalName" SG_ 955 IFICMDfstOnSwReq "IFICMDfstOnSwReq";
BA_ "LongName" SG_ 955 IFICMDfstOnSwReq "Front Infotainment Control Module Defrost On Switch Request";
BA_ "SysSignalName" SG_ 955 IFICMDfstOnSwReq "FICMDfstOnSwReq";
BA_ "CompuMethodName" SG_ 955 IFICMACLTemV "FICMACLTemV";
BA_ "GenSigStartValue" SG_ 955 IFICMACLTemV 1;
BA_ "ISignalName" SG_ 955 IFICMACLTemV "IFICMACLTemV";
BA_ "LongName" SG_ 955 IFICMACLTemV "Front Infotainment Control Module Air Conditioning Left Temperature Validity";
BA_ "SysSignalName" SG_ 955 IFICMACLTemV "FICMACLTemV";
BA_ "CompuMethodName" SG_ 955 ITLRMdSwReq "TLRMdSwReq";
BA_ "ISignalName" SG_ 955 ITLRMdSwReq "ITLRMdSwReq";
BA_ "LongName" SG_ 955 ITLRMdSwReq "Traffic_lights_recognition_Mode_Switch_Display_Request";
BA_ "SysSignalName" SG_ 955 ITLRMdSwReq "TLRMdSwReq";
BA_ "CompuMethodName" SG_ 955 ITSRSwReq "TSRSwReq";
BA_ "ISignalName" SG_ 955 ITSRSwReq "ITSRSwReq";
BA_ "LongName" SG_ 955 ITSRSwReq "TSR_Switch_Request_Response";
BA_ "SysSignalName" SG_ 955 ITSRSwReq "TSRSwReq";
BA_ "CompuMethodName" SG_ 955 ISpdLmtOfstSetNumReq "SpdLmtOfstSetNumReq";
BA_ "ISignalName" SG_ 955 ISpdLmtOfstSetNumReq "ISpdLmtOfstSetNumReq";
BA_ "LongName" SG_ 955 ISpdLmtOfstSetNumReq "Speed Limit Offset Set Number_Request";
BA_ "SysSignalName" SG_ 955 ISpdLmtOfstSetNumReq "SpdLmtOfstSetNumReq";
BA_ "CompuMethodName" SG_ 955 IILCSwReq "ILCSwReq";
BA_ "ISignalName" SG_ 955 IILCSwReq "IILCSwReq";
BA_ "LongName" SG_ 955 IILCSwReq "Intelligent_Lateral_Control_Switch_Request";
BA_ "SysSignalName" SG_ 955 IILCSwReq "ILCSwReq";
BA_ "CompuMethodName" SG_ 955 ISpdLmtOfstSetPercReq "SpdLmtOfstSetPercReq";
BA_ "ISignalName" SG_ 955 ISpdLmtOfstSetPercReq "ISpdLmtOfstSetPercReq";
BA_ "LongName" SG_ 955 ISpdLmtOfstSetPercReq "Speed Limit Offset Set Percent_Request";
BA_ "SysSignalName" SG_ 955 ISpdLmtOfstSetPercReq "SpdLmtOfstSetPercReq";
VAL_ 1010 IThreeDimnlDspReq 0 "ThreeDimnlDspReq_0_NoRequest" 1 "ThreeDimnlDspReq_1_2D" 2 "ThreeDimnlDspReq_2_3D";
VAL_ 1010 ISysFltRsn 0 "SysFltRsn_0_NoWarning" 1 "SysFltRsn_1_AllCameraWorkAbnormal" 2 "SysFltRsn_2_HardwareFail" 3 "SysFltRsn_3_SystemAbnormal" 4 "SysFltRsn_4_DMSCameraWorkAbnormal" 5 "SysFltRsn_5_OMSCameraWorkAbnormal";
VAL_ 1010 IErrRespHODM 0 "ErrRespHODM_l_0_NoError" 1 "ErrRespHODM_l_1_Error";
VAL_ 1010 ISWSCnfmSwReq 0 "SWSCnfmSwReq_0_SWSCnfmSwReq_0_Idle" 1 "SWSCnfmSwReq_1_SWSCnfmSwReq_1_Press" 3 "SWSCnfmSwReq_3_SWSCnfmSwReq_3_Error";
VAL_ 1010 IMirFoldCtrlResp 0 "MirFoldCtrlResp_0_NoRequest" 1 "MirFoldCtrlResp_1_Approved" 2 "MirFoldCtrlResp_2_AuthenticationFailure" 3 "MirFoldCtrlResp_3_OtherReason" 4 "MirFoldCtrlResp_4_FeatureisTimeout" 5 "MirFoldCtrlResp_5_Featureisnotsupported";
VAL_ 1010 ITgtParkingChosed 0 "TgtParkingChosed_0_NoChosed" 1 "TgtParkingChosed_1_ChosedId1" 2 "TgtParkingChosed_2_ChosedId2" 3 "TgtParkingChosed_3_ChosedId3" 4 "TgtParkingChosed_4_ChosedId4" 5 "TgtParkingChosed_5_ChosedId5" 6 "TgtParkingChosed_6_ChosedId6" 7 "TgtParkingChosed_7_ChosedId7" 8 "TgtParkingChosed_8_ChosedId8" 9 "TgtParkingChosed_9_ChosedId9" 10 "TgtParkingChosed_10_ChosedId10" 11 "TgtParkingChosed_11_ChosedId11" 12 "TgtParkingChosed_12_ChosedId12" 13 "TgtParkingChosed_13_Reserved" 14 "TgtParkingChosed_14_Reserved" 15 "TgtParkingChosed_15_Reserved";
VAL_ 1010 ISpdLmtMdFICM 0 "SpdLmtMdFICM_0_AIPilotSwReq_0_NoRequest" 1 "SpdLmtMdFICM_1_Off" 2 "SpdLmtMdFICM_2_SLIF" 3 "SpdLmtMdFICM_3_ISA";
VAL_ 1010 IAutocParkngSwReq 0 "AutocParkngSwReq_0_Idle" 1 "AutocParkngSwReq_1_Press" 3 "AutocParkngSwReq_3_Error";
VAL_ 1010 IIMATESysSts 0 "IMATESysSts_0_Off" 1 "IMATESysSts_1_Standby" 2 "IMATESysSts_2_Active" 3 "IMATESysSts_3_Fault" 4 "IMATESysSts_4_Reserved" 5 "IMATESysSts_5_Reserved" 6 "IMATESysSts_6_Reserved" 7 "IMATESysSts_7_Reserved";
VAL_ 1010 ILampCtrlResp 0 "LampCtrlResp_0_NoRequest" 1 "LampCtrlResp_1_Approved" 2 "LampCtrlResp_2_PowerModeisnotOFF" 3 "LampCtrlResp_3_VehicleisnotinExternalLock" 4 "LampCtrlResp_4_Commandisrunning" 5 "LampCtrlResp_5_LightSystemisFault" 6 "LampCtrlResp_6_VehicleisMoving" 7 "LampCtrlResp_7_AuthenticationFailure" 8 "LampCtrlResp_8_OtherReason" 9 "LampCtrlResp_9_FeatureisTimeout" 10 "LampCtrlResp_10_Featureisnotsupported";
VAL_ 1010 IPwrMdCtrlResp 0 "PwrMdCtrlResp__0_No_Request" 1 "PwrMdCtrlResp__1_Approved" 2 "PwrMdCtrlResp__2_Authentication_Failure" 3 "PwrMdCtrlResp__3_Other_Reason" 4 "PwrMdCtrlResp__4_FeatureisTimeout" 5 "PwrMdCtrlResp__5_Featureisnotsupported";
VAL_ 1010 ILVSSts 0 "LVSSts_0_Inactive" 1 "LVSSts_1_Active";
VAL_ 1010 IFrSsdManuCtrl 0 "FrSsdManuCtrl_0_No_Request" 1 "FrSsdManuCtrl_1_Manual_Open" 2 "FrSsdManuCtrl_2_Manual_Close" 3 "FrSsdManuCtrl_3_Reserve";
VAL_ 1010 IPwrCtrlResp 0 "PwrCtrlResp_0_No_Request" 1 "PwrCtrlResp_1_Approved" 2 "PwrCtrlResp_2_Authentication_Failure" 3 "PwrCtrlResp_3_Other_Reason" 4 "PwrCtrlResp_4_FeatureisTimeout" 5 "PwrCtrlResp_5_Featureisnotsupported";
VAL_ 591 IDrvrFtgLvl 0 "DrvrFtgLvl_0_Unknown" 1 "DrvrFtgLvl_1_No_Drowsiness" 2 "DrvrFtgLvl_2_Low_level_Drowsiness" 3 "DrvrFtgLvl_3_Middle_level_Drowsiness" 4 "DrvrFtgLvl_4_High_level_Drowsiness" 5 "DrvrFtgLvl_5_Reserve" 6 "DrvrFtgLvl_6_Reserve" 7 "DrvrFtgLvl_7_Reserve";
VAL_ 591 IDrvrPrsc 0 "DrvrPrsc_0_Unknown" 1 "DrvrPrsc_1_DriverNotPresence" 2 "DrvrPrsc_2_DriverPresence" 3 "DrvrPrsc_3_Reserved" 4 "DrvrPrsc_4_Reserved" 5 "DrvrPrsc_5_Reserved" 6 "DrvrPrsc_6_Reserved" 7 "DrvrPrsc_7_Reserved";
VAL_ 591 IIMATEysSts 0 "IMATEysSts_0_Off" 1 "IMATEysSts_1_Standby" 2 "IMATEysSts_2_Active" 3 "IMATEysSts_3_Fault" 4 "IMATEysSts_4_CameraBlocked";
VAL_ 591 IDrvrDstrctnSts 0 "DrvrDstrctnSts_0_Unknown" 1 "DrvrDstrctnSts_1_NoDistraction" 2 "DrvrDstrctnSts_2_LowLevelDistraction" 3 "DrvrDstrctnSts_3_MiddleLevelDistraction" 4 "DrvrDstrctnSts_4_HighLevelDistraction" 5 "DrvrDstrctnSts_5_ShortTiemDistraction" 6 "DrvrDstrctnSts_6_LongTimeDistraction" 7 "DrvrDstrctnSts_7_Reserved";
VAL_ 591 IDrvrAbnormBehvor 0 "DrvrAbnormBehvor_0_Unknown" 1 "DrvrAbnormBehvor_1_No_abnormal_behaviour" 2 "DrvrAbnormBehvor_2_Telephone_calls" 3 "DrvrAbnormBehvor_3_Smoking" 4 "DrvrAbnormBehvor_4_Drinking_water" 5 "DrvrAbnormBehvor_5_Eating";
VAL_ 591 IDrvrGazeRgn 0 "DrvrGazeRgn_0_Unknown" 1 "DrvrGazeRgn_1_DriverSideOfWindscreen" 2 "DrvrGazeRgn_2_CopilotSideOfWindscreen" 3 "DrvrGazeRgn_3_LeftRearViewMirror" 4 "DrvrGazeRgn_4_RightRearViewMirror" 5 "DrvrGazeRgn_5_LeftSideWindow" 6 "DrvrGazeRgn_6_RightSideWindow" 7 "DrvrGazeRgn_7_CentralRearViewMirror" 8 "DrvrGazeRgn_8_CentralDriverInstrumentCluster" 9 "DrvrGazeRgn_9_HeadupDisplay" 10 "DrvrGazeRgn_10_NavigationDisplay" 11 "DrvrGazeRgn_11_MiddleInstrumentCluster" 12 "DrvrGazeRgn_12_SteeringWheel" 13 "DrvrGazeRgn_13_LeftSeatFootArea" 14 "DrvrGazeRgn_14_RightSeatFootAreaOrWorkbench" 15 "DrvrGazeRgn_15_LeftSideDoorArea" 16 "DrvrGazeRgn_16_RightSideDoorArea";
VAL_ 728 IAIParkngSpcIDICB 0 "AIParkngSpcIDICB_0_NoRequest" 1 "AIParkngSpcIDICB_1_ParktoParkingSpaceID1" 2 "AIParkngSpcIDICB_2_ParktoParkingSpaceID2" 3 "AIParkngSpcIDICB_3_ParktoParkingSpaceID3" 4 "AIParkngSpcIDICB_4_ParktoParkingSpaceID4" 5 "AIParkngSpcIDICB_5_ParktoParkingSpaceID5" 6 "AIParkngSpcIDICB_6_ParktoParkingSpaceID6" 7 "AIParkngSpcIDICB_7_ParktoParkingSpaceID7" 8 "AIParkngSpcIDICB_8_ParktoParkingSpaceID8" 9 "AIParkngSpcIDICB_9_ParktoDIYSpace";
VAL_ 728 IRemParkngMapChosen 0 "RemParkngMapChosen_0_No_Request" 1 "RemParkngMapChosen_1_Choose_Remember_MapID1" 2 "RemParkngMapChosen_2_Choose_Remember_MapID2" 3 "RemParkngMapChosen_3_Choose_Remember_MapID3" 4 "RemParkngMapChosen_4_Choose_Remember_MapID4" 5 "RemParkngMapChosen_5_Choose_Remember_MapID5" 6 "RemParkngMapChosen_6_Choose_Remember_MapID6" 7 "RemParkngMapChosen_7_Choose_Remember_MapID7" 8 "RemParkngMapChosen_8_Choose_Remember_MapID8" 9 "RemParkngMapChosen_9_Choose_Remember_MapID9" 10 "RemParkngMapChosen_10_Choose_Remember_MapID10" 11 "RemParkngMapChosen_11_Choose_Remember_MapID11" 12 "RemParkngMapChosen_12_Choose_Remember_MapID12" 13 "RemParkngMapChosen_13_Choose_Remember_MapID13" 14 "RemParkngMapChosen_14_Choose_Remember_MapID14" 15 "RemParkngMapChosen_15_Choose_Remember_MapID15" 16 "RemParkngMapChosen_16_Choose_Remember_MapID16" 17 "RemParkngMapChosen_17_Choose_Remember_MapID17" 18 "RemParkngMapChosen_18_Choose_Remember_MapID18" 19 "RemParkngMapChosen_19_Choose_Remember_MapID19" 20 "RemParkngMapChosen_20_Choose_Remember_MapID20" 21 "RemParkngMapChosen_21_Choose_Remember_MapID21" 22 "RemParkngMapChosen_22_Choose_Remember_MapID22" 23 "RemParkngMapChosen_23_Choose_Remember_MapID23" 24 "RemParkngMapChosen_24_Choose_Remember_MapID24" 25 "RemParkngMapChosen_25_Choose_Remember_MapID25" 26 "RemParkngMapChosen_26_Choose_Remember_MapID26" 27 "RemParkngMapChosen_27_Choose_Remember_MapID27" 28 "RemParkngMapChosen_28_Choose_Remember_MapID28" 29 "RemParkngMapChosen_29_Choose_Remember_MapID29" 30 "RemParkngMapChosen_30_Choose_Remember_MapID30" 31 "RemParkngMapChosen_31_Choose_Remember_MapID31" 32 "RemParkngMapChosen_32_Choose_Remember_MapID32" 33 "RemParkngMapChosen_33_Choose_Remember_MapID33" 34 "RemParkngMapChosen_34_Choose_Remember_MapID34" 35 "RemParkngMapChosen_35_Choose_Remember_MapID35" 36 "RemParkngMapChosen_36_Choose_Remember_MapID36" 37 "RemParkngMapChosen_37_Choose_Remember_MapID37" 38 "RemParkngMapChosen_38_Choose_Remember_MapID38" 39 "RemParkngMapChosen_39_Choose_Remember_MapID39" 40 "RemParkngMapChosen_40_Choose_Remember_MapID40" 41 "RemParkngMapChosen_41_Choose_Remember_MapID41" 42 "RemParkngMapChosen_42_Choose_Remember_MapID42" 43 "RemParkngMapChosen_43_Choose_Remember_MapID43" 44 "RemParkngMapChosen_44_Choose_Remember_MapID44" 45 "RemParkngMapChosen_45_Choose_Remember_MapID45" 46 "RemParkngMapChosen_46_Choose_Remember_MapID46" 47 "RemParkngMapChosen_47_Choose_Remember_MapID47" 48 "RemParkngMapChosen_48_Choose_Remember_MapID48" 49 "RemParkngMapChosen_49_Choose_Remember_MapID49" 50 "RemParkngMapChosen_50_Choose_Remember_MapID50" 51 "RemParkngMapChosen_51_Choose_Remember_MapID51" 52 "RemParkngMapChosen_52_Choose_Remember_MapID52" 53 "RemParkngMapChosen_53_Choose_Remember_MapID53" 54 "RemParkngMapChosen_54_Choose_Remember_MapID54" 55 "RemParkngMapChosen_55_Choose_Remember_MapID55" 56 "RemParkngMapChosen_56_Choose_Remember_MapID56" 57 "RemParkngMapChosen_57_Choose_Remember_MapID57" 58 "RemParkngMapChosen_58_Choose_Remember_MapID58" 59 "RemParkngMapChosen_59_Choose_Remember_MapID59" 60 "RemParkngMapChosen_60_Choose_Remember_MapID60" 61 "RemParkngMapChosen_61_Choose_Remember_MapID61" 62 "RemParkngMapChosen_62_Choose_Remember_MapID62" 63 "RemParkngMapChosen_63_Choose_Remember_MapID63" 64 "RemParkngMapChosen_64_Choose_Remember_MapID64" 65 "RemParkngMapChosen_65_Choose_Remember_MapID65" 66 "RemParkngMapChosen_66_Choose_Remember_MapID66" 67 "RemParkngMapChosen_67_Choose_Remember_MapID67" 68 "RemParkngMapChosen_68_Choose_Remember_MapID68" 69 "RemParkngMapChosen_69_Choose_Remember_MapID69" 70 "RemParkngMapChosen_70_Choose_Remember_MapID70" 71 "RemParkngMapChosen_71_Choose_Remember_MapID71" 72 "RemParkngMapChosen_72_Choose_Remember_MapID72" 73 "RemParkngMapChosen_73_Choose_Remember_MapID73" 74 "RemParkngMapChosen_74_Choose_Remember_MapID74" 75 "RemParkngMapChosen_75_Choose_Remember_MapID75" 76 "RemParkngMapChosen_76_Choose_Remember_MapID76" 77 "RemParkngMapChosen_77_Choose_Remember_MapID77" 78 "RemParkngMapChosen_78_Choose_Remember_MapID78" 79 "RemParkngMapChosen_79_Choose_Remember_MapID79" 80 "RemParkngMapChosen_80_Choose_Remember_MapID80" 81 "RemParkngMapChosen_81_Choose_Remember_MapID81" 82 "RemParkngMapChosen_82_Choose_Remember_MapID82" 83 "RemParkngMapChosen_83_Choose_Remember_MapID83" 84 "RemParkngMapChosen_84_Choose_Remember_MapID84" 85 "RemParkngMapChosen_85_Choose_Remember_MapID85" 86 "RemParkngMapChosen_86_Choose_Remember_MapID86" 87 "RemParkngMapChosen_87_Choose_Remember_MapID87" 88 "RemParkngMapChosen_88_Choose_Remember_MapID88" 89 "RemParkngMapChosen_89_Choose_Remember_MapID89" 90 "RemParkngMapChosen_90_Choose_Remember_MapID90" 91 "RemParkngMapChosen_91_Choose_Remember_MapID91" 92 "RemParkngMapChosen_92_Choose_Remember_MapID92" 93 "RemParkngMapChosen_93_Choose_Remember_MapID93" 94 "RemParkngMapChosen_94_Choose_Remember_MapID94" 95 "RemParkngMapChosen_95_Choose_Remember_MapID95" 96 "RemParkngMapChosen_96_Choose_Remember_MapID96" 97 "RemParkngMapChosen_97_Choose_Remember_MapID97" 98 "RemParkngMapChosen_98_Choose_Remember_MapID98" 99 "RemParkngMapChosen_99_Choose_Remember_MapID99" 100 "RemParkngMapChosen_100_Choose_Remember_MapID100" 101 "RemParkngMapChosen_101_Choose_Remember_MapID101" 102 "RemParkngMapChosen_102_Choose_Remember_MapID102" 103 "RemParkngMapChosen_103_Choose_Remember_MapID103" 104 "RemParkngMapChosen_104_Choose_Remember_MapID104" 105 "RemParkngMapChosen_105_Choose_Remember_MapID105" 106 "RemParkngMapChosen_106_Choose_Remember_MapID106" 107 "RemParkngMapChosen_107_Choose_Remember_MapID107" 108 "RemParkngMapChosen_108_Choose_Remember_MapID108" 109 "RemParkngMapChosen_109_Choose_Remember_MapID109" 110 "RemParkngMapChosen_110_Choose_Remember_MapID110" 111 "RemParkngMapChosen_111_Choose_Remember_MapID111" 112 "RemParkngMapChosen_112_Choose_Remember_MapID112" 113 "RemParkngMapChosen_113_Choose_Remember_MapID113" 114 "RemParkngMapChosen_114_Choose_Remember_MapID114" 115 "RemParkngMapChosen_115_Choose_Remember_MapID115" 116 "RemParkngMapChosen_116_Choose_Remember_MapID116" 117 "RemParkngMapChosen_117_Choose_Remember_MapID117" 118 "RemParkngMapChosen_118_Choose_Remember_MapID118" 119 "RemParkngMapChosen_119_Choose_Remember_MapID119" 120 "RemParkngMapChosen_120_Choose_Remember_MapID120" 121 "RemParkngMapChosen_121_Choose_Remember_MapID121" 122 "RemParkngMapChosen_122_Choose_Remember_MapID122" 123 "RemParkngMapChosen_123_Choose_Remember_MapID123" 124 "RemParkngMapChosen_124_Choose_Remember_MapID124" 125 "RemParkngMapChosen_125_Choose_Remember_MapID125" 126 "RemParkngMapChosen_126_Choose_Remember_MapID126" 127 "RemParkngMapChosen_127_Choose_Remember_MapID127" 128 "RemParkngMapChosen_128_Choose_Remember_MapID128" 129 "RemParkngMapChosen_129_Choose_Remember_MapID129" 130 "RemParkngMapChosen_130_Choose_Remember_MapID130" 131 "RemParkngMapChosen_131_Choose_Remember_MapID131" 132 "RemParkngMapChosen_132_Choose_Remember_MapID132" 133 "RemParkngMapChosen_133_Choose_Remember_MapID133" 134 "RemParkngMapChosen_134_Choose_Remember_MapID134" 135 "RemParkngMapChosen_135_Choose_Remember_MapID135" 136 "RemParkngMapChosen_136_Choose_Remember_MapID136" 137 "RemParkngMapChosen_137_Choose_Remember_MapID137" 138 "RemParkngMapChosen_138_Choose_Remember_MapID138" 139 "RemParkngMapChosen_139_Choose_Remember_MapID139" 140 "RemParkngMapChosen_140_Choose_Remember_MapID140" 141 "RemParkngMapChosen_141_Choose_Remember_MapID141" 142 "RemParkngMapChosen_142_Choose_Remember_MapID142" 143 "RemParkngMapChosen_143_Choose_Remember_MapID143" 144 "RemParkngMapChosen_144_Choose_Remember_MapID144" 145 "RemParkngMapChosen_145_Choose_Remember_MapID145" 146 "RemParkngMapChosen_146_Choose_Remember_MapID146" 147 "RemParkngMapChosen_147_Choose_Remember_MapID147" 148 "RemParkngMapChosen_148_Choose_Remember_MapID148" 149 "RemParkngMapChosen_149_Choose_Remember_MapID149" 150 "RemParkngMapChosen_150_Choose_Remember_MapID150" 151 "RemParkngMapChosen_151_Choose_Remember_MapID151" 152 "RemParkngMapChosen_152_Choose_Remember_MapID152" 153 "RemParkngMapChosen_153_Choose_Remember_MapID153" 154 "RemParkngMapChosen_154_Choose_Remember_MapID154" 155 "RemParkngMapChosen_155_Choose_Remember_MapID155" 156 "RemParkngMapChosen_156_Choose_Remember_MapID156" 157 "RemParkngMapChosen_157_Choose_Remember_MapID157" 158 "RemParkngMapChosen_158_Choose_Remember_MapID158" 159 "RemParkngMapChosen_159_Choose_Remember_MapID159" 160 "RemParkngMapChosen_160_Choose_Remember_MapID160" 161 "RemParkngMapChosen_161_Choose_Remember_MapID161" 162 "RemParkngMapChosen_162_Choose_Remember_MapID162" 163 "RemParkngMapChosen_163_Choose_Remember_MapID163" 164 "RemParkngMapChosen_164_Choose_Remember_MapID164" 165 "RemParkngMapChosen_165_Choose_Remember_MapID165" 166 "RemParkngMapChosen_166_Choose_Remember_MapID166" 167 "RemParkngMapChosen_167_Choose_Remember_MapID167" 168 "RemParkngMapChosen_168_Choose_Remember_MapID168" 169 "RemParkngMapChosen_169_Choose_Remember_MapID169" 170 "RemParkngMapChosen_170_Choose_Remember_MapID170" 171 "RemParkngMapChosen_171_Choose_Remember_MapID171" 172 "RemParkngMapChosen_172_Choose_Remember_MapID172" 173 "RemParkngMapChosen_173_Choose_Remember_MapID173" 174 "RemParkngMapChosen_174_Choose_Remember_MapID174" 175 "RemParkngMapChosen_175_Choose_Remember_MapID175" 176 "RemParkngMapChosen_176_Choose_Remember_MapID176" 177 "RemParkngMapChosen_177_Choose_Remember_MapID177" 178 "RemParkngMapChosen_178_Choose_Remember_MapID178" 179 "RemParkngMapChosen_179_Choose_Remember_MapID179" 180 "RemParkngMapChosen_180_Choose_Remember_MapID180" 181 "RemParkngMapChosen_181_Choose_Remember_MapID181" 182 "RemParkngMapChosen_182_Choose_Remember_MapID182" 183 "RemParkngMapChosen_183_Choose_Remember_MapID183" 184 "RemParkngMapChosen_184_Choose_Remember_MapID184" 185 "RemParkngMapChosen_185_Choose_Remember_MapID185" 186 "RemParkngMapChosen_186_Choose_Remember_MapID186" 187 "RemParkngMapChosen_187_Choose_Remember_MapID187" 188 "RemParkngMapChosen_188_Choose_Remember_MapID188" 189 "RemParkngMapChosen_189_Choose_Remember_MapID189" 190 "RemParkngMapChosen_190_Choose_Remember_MapID190" 191 "RemParkngMapChosen_191_Choose_Remember_MapID191" 192 "RemParkngMapChosen_192_Choose_Remember_MapID192" 193 "RemParkngMapChosen_193_Choose_Remember_MapID193" 194 "RemParkngMapChosen_194_Choose_Remember_MapID194" 195 "RemParkngMapChosen_195_Choose_Remember_MapID195" 196 "RemParkngMapChosen_196_Choose_Remember_MapID196" 197 "RemParkngMapChosen_197_Choose_Remember_MapID197" 198 "RemParkngMapChosen_198_Choose_Remember_MapID198" 199 "RemParkngMapChosen_199_Choose_Remember_MapID199" 200 "RemParkngMapChosen_200_Choose_Remember_MapID200" 201 "RemParkngMapChosen_201_Choose_Remember_MapID201" 202 "RemParkngMapChosen_202_Choose_Remember_MapID202" 203 "RemParkngMapChosen_203_Choose_Remember_MapID203" 204 "RemParkngMapChosen_204_Choose_Remember_MapID204" 205 "RemParkngMapChosen_205_Choose_Remember_MapID205" 206 "RemParkngMapChosen_206_Choose_Remember_MapID206" 207 "RemParkngMapChosen_207_Choose_Remember_MapID207" 208 "RemParkngMapChosen_208_Choose_Remember_MapID208" 209 "RemParkngMapChosen_209_Choose_Remember_MapID209" 210 "RemParkngMapChosen_210_Choose_Remember_MapID210" 211 "RemParkngMapChosen_211_Choose_Remember_MapID211" 212 "RemParkngMapChosen_212_Choose_Remember_MapID212" 213 "RemParkngMapChosen_213_Choose_Remember_MapID213" 214 "RemParkngMapChosen_214_Choose_Remember_MapID214" 215 "RemParkngMapChosen_215_Choose_Remember_MapID215" 216 "RemParkngMapChosen_216_Choose_Remember_MapID216" 217 "RemParkngMapChosen_217_Choose_Remember_MapID217" 218 "RemParkngMapChosen_218_Choose_Remember_MapID218" 219 "RemParkngMapChosen_219_Choose_Remember_MapID219" 220 "RemParkngMapChosen_220_Choose_Remember_MapID220" 221 "RemParkngMapChosen_221_Choose_Remember_MapID221" 222 "RemParkngMapChosen_222_Choose_Remember_MapID222" 223 "RemParkngMapChosen_223_Choose_Remember_MapID223" 224 "RemParkngMapChosen_224_Choose_Remember_MapID224" 225 "RemParkngMapChosen_225_Choose_Remember_MapID225" 226 "RemParkngMapChosen_226_Choose_Remember_MapID226" 227 "RemParkngMapChosen_227_Choose_Remember_MapID227" 228 "RemParkngMapChosen_228_Choose_Remember_MapID228" 229 "RemParkngMapChosen_229_Choose_Remember_MapID229" 230 "RemParkngMapChosen_230_Choose_Remember_MapID230" 231 "RemParkngMapChosen_231_Choose_Remember_MapID231" 232 "RemParkngMapChosen_232_Choose_Remember_MapID232" 233 "RemParkngMapChosen_233_Choose_Remember_MapID233" 234 "RemParkngMapChosen_234_Choose_Remember_MapID234" 235 "RemParkngMapChosen_235_Choose_Remember_MapID235" 236 "RemParkngMapChosen_236_Choose_Remember_MapID236" 237 "RemParkngMapChosen_237_Choose_Remember_MapID237" 238 "RemParkngMapChosen_238_Choose_Remember_MapID238" 239 "RemParkngMapChosen_239_Choose_Remember_MapID239" 240 "RemParkngMapChosen_240_Choose_Remember_MapID240" 241 "RemParkngMapChosen_241_Choose_Remember_MapID241" 242 "RemParkngMapChosen_242_Choose_Remember_MapID242" 243 "RemParkngMapChosen_243_Choose_Remember_MapID243" 244 "RemParkngMapChosen_244_Choose_Remember_MapID244" 245 "RemParkngMapChosen_245_Choose_Remember_MapID245" 246 "RemParkngMapChosen_246_Choose_Remember_MapID246" 247 "RemParkngMapChosen_247_Choose_Remember_MapID247" 248 "RemParkngMapChosen_248_Choose_Remember_MapID248" 249 "RemParkngMapChosen_249_Choose_Remember_MapID249" 250 "RemParkngMapChosen_250_Choose_Remember_MapID250" 251 "RemParkngMapChosen_251_Choose_Remember_MapID251" 252 "RemParkngMapChosen_252_Choose_Remember_MapID252" 253 "RemParkngMapChosen_253_Choose_Remember_MapID253" 254 "RemParkngMapChosen_254_Choose_Remember_MapID254" 255 "RemParkngMapChosen_255_Choose_Remember_MapID255";
VAL_ 728 IAIParkngReqICB 1 "AIParkngReqICB_1_Start_Parking_in" 2 "AIParkngReqICB_2_Start_Parking_out" 3 "AIParkngReqICB_3_Pause" 4 "AIParkngReqICB_4_Continue" 5 "AIParkngReqICB_5_Cancel" 6 "AIParkngReqICB_6_Back_XEquals1" 7 "AIParkngReqICB_7_Left_Parking_out" 8 "AIParkngReqICB_8_Right_Parking_out" 9 "AIParkngReqICB_9_Fast_Parking" 10 "AIParkngReqICB_10_Line_out_System_Start" 11 "AIParkngReqICB_11_Line_back_System_Start" 12 "AIParkngReqICB_12_Call_to_Position_X" 13 "AIParkngReqICB_13_StartParkingScanningManualDriving_XEquals1" 14 "AIParkngReqICB_14_Remote_turn_left_XEquals8" 15 "AIParkngReqICB_15_Remote_turn_right_XEquals8" 16 "AIParkngReqICB_16_RememberBuildMap" 17 "AIParkngReqICB_17_Remember_Park_In" 18 "AIParkngReqICB_18_Remember_Summon" 19 "AIParkngReqICB_19_Start_Remember_Parking" 20 "AIParkngReqICB_20_Keep_Going_Forword" 21 "AIParkngReqICB_21_Keep_Going_Back" 22 "AIParkngReqICB_22_Start_AVP_in" 23 "AIParkngReqICB_23_Start_AVP_out" 24 "AIParkngReqICB_24_Back_Left_Parking_out" 25 "AIParkngReqICB_25_Back_Right_Parking_out" 32 "AIParkngReqICB_32_choose_left_direction_XEquals1" 33 "AIParkngReqICB_33_choose_right_direction_XEquals1" 34 "AIParkngReqICB_34_ReverseParkingInRecordingParking_XEquals1" 35 "AIParkngReqICB_35_MinorAdjEntry_XEquals1" 36 "AIParkngReqICB_36_MinorAdjActive_XEquals1" 37 "AIParkngReqICB_37_ReverseParkingEntry_XEquals1" 38 "MinorAdjActive_Left_XEquals1_2_P11L_M2_P11LX1_S11L_M1_P12L_427PP01_P11L_M3_EP33L_S11L_M2_S12L_M1" 39 "MinorAdjActive_Right_XEquals1_2_P11L_M2_P11LX1_S11L_M1_P12L_427PP01_P11L_M3_EP33_S11L_M2_S12L_M1" 40 "FixMinorAdj_XEquals1_2_P11L_M2_P11LX1_S11L_M1_P12L_427PP01_P11L_M3_EP33L_S11L_M2_S12L_M1" 41 "AIParkngReqICB_41_Trun_around_Left" 42 "AIParkngReqICB_42_RPAIN_Confirming" 45 "AIParkngReqICB_45_NarrowRoadForwardActive" 46 "AIParkngReqICB_46_NarrowRoadForwardEntry" 48 "AIParkngReqICB_48_Trun_around_Right" 49 "AIParkngReqICB_49_Choose_left_turn_round" 50 "AIParkngReqICB_50_Choose_right_turn_round" 51 "AIParkngReqICB_51_choose_right_back_direction" 52 "AIParkngReqICB_52_choose_left_back_direction" 53 "AIParkngReqICB_53_reserved" 54 "AIParkngReqICB_54_reserved" 55 "AIParkngReqICB_55_reserved" 56 "AIParkngReqICB_56_reserved" 57 "AIParkngReqICB_57_reserved" 58 "AIParkngReqICB_58_reserved" 59 "AIParkngReqICB_59_reserved" 60 "AIParkngReqICB_60_reserved" 61 "AIParkngReqICB_61_reserved" 62 "AIParkngReqICB_62_reserved" 63 "AIParkngReqICB_63_reserved" 64 "AIParkngReqICB_64_reserved" 65 "AIParkngReqICB_65_reserved" 66 "AIParkngReqICB_66_reserved" 67 "AIParkngReqICB_67_reserved" 68 "AIParkngReqICB_68_reserved" 69 "AIParkngReqICB_69_reserved" 70 "AIParkngReqICB_70_reserved" 71 "AIParkngReqICB_71_reserved" 72 "AIParkngReqICB_72_reserved" 73 "AIParkngReqICB_73_reserved" 74 "AIParkngReqICB_74_reserved" 75 "AIParkngReqICB_75_reserved" 76 "AIParkngReqICB_76_reserved" 77 "AIParkngReqICB_77_reserved" 78 "AIParkngReqICB_78_reserved" 79 "AIParkngReqICB_79_reserved" 80 "AIParkngReqICB_80_reserved" 81 "AIParkngReqICB_81_reserved" 82 "AIParkngReqICB_82_reserved" 83 "AIParkngReqICB_83_reserved" 84 "AIParkngReqICB_84_reserved" 85 "AIParkngReqICB_85_reserved" 86 "AIParkngReqICB_86_reserved" 87 "AIParkngReqICB_87_reserved" 88 "AIParkngReqICB_88_reserved" 89 "AIParkngReqICB_89_reserved" 90 "AIParkngReqICB_90_reserved" 91 "AIParkngReqICB_91_reserved" 92 "AIParkngReqICB_92_reserved" 93 "AIParkngReqICB_93_reserved" 94 "AIParkngReqICB_94_reserved" 95 "AIParkngReqICB_95_reserved" 96 "AIParkngReqICB_96_reserved" 97 "AIParkngReqICB_97_reserved" 98 "AIParkngReqICB_98_reserved" 99 "AIParkngReqICB_99_reserved" 100 "AIParkngReqICB_100_reserved" 101 "AIParkngReqICB_101_reserved" 102 "AIParkngReqICB_102_reserved" 103 "AIParkngReqICB_103_reserved" 104 "AIParkngReqICB_104_reserved" 105 "AIParkngReqICB_105_reserved" 106 "AIParkngReqICB_106_reserved" 107 "AIParkngReqICB_107_reserved" 108 "AIParkngReqICB_108_reserved" 109 "AIParkngReqICB_109_reserved" 110 "AIParkngReqICB_110_reserved" 111 "AIParkngReqICB_111_reserved" 112 "AIParkngReqICB_112_reserved" 113 "AIParkngReqICB_113_reserved" 114 "AIParkngReqICB_114_reserved" 115 "AIParkngReqICB_115_reserved" 116 "AIParkngReqICB_116_reserved" 117 "AIParkngReqICB_117_reserved" 118 "AIParkngReqICB_118_reserved" 119 "AIParkngReqICB_119_reserved" 120 "AIParkngReqICB_120_reserved" 121 "AIParkngReqICB_121_reserved" 122 "AIParkngReqICB_122_reserved" 123 "AIParkngReqICB_123_reserved" 124 "AIParkngReqICB_124_reserved" 125 "AIParkngReqICB_125_reserved" 126 "AIParkngReqICB_126_reserved" 127 "AIParkngReqICB_127_reserved" 128 "AIParkngReqICB_128_reserved" 129 "AIParkngReqICB_129_reserved" 130 "AIParkngReqICB_130_reserved" 131 "AIParkngReqICB_131_reserved" 132 "AIParkngReqICB_132_reserved" 133 "AIParkngReqICB_133_reserved" 134 "AIParkngReqICB_134_reserved" 135 "AIParkngReqICB_135_reserved" 136 "AIParkngReqICB_136_reserved" 137 "AIParkngReqICB_137_reserved" 138 "AIParkngReqICB_138_reserved" 139 "AIParkngReqICB_139_reserved" 140 "AIParkngReqICB_140_reserved" 141 "AIParkngReqICB_141_reserved" 142 "AIParkngReqICB_142_reserved" 143 "AIParkngReqICB_143_reserved" 144 "AIParkngReqICB_144_reserved" 145 "AIParkngReqICB_145_reserved" 146 "AIParkngReqICB_146_reserved" 147 "AIParkngReqICB_147_reserved" 148 "AIParkngReqICB_148_reserved" 149 "AIParkngReqICB_149_reserved" 150 "AIParkngReqICB_150_reserved" 151 "AIParkngReqICB_151_reserved" 152 "AIParkngReqICB_152_reserved" 153 "AIParkngReqICB_153_reserved" 154 "AIParkngReqICB_154_reserved" 155 "AIParkngReqICB_155_reserved" 156 "AIParkngReqICB_156_reserved" 157 "AIParkngReqICB_157_reserved" 158 "AIParkngReqICB_158_reserved" 159 "AIParkngReqICB_159_reserved" 160 "AIParkngReqICB_160_reserved" 161 "AIParkngReqICB_161_reserved" 162 "AIParkngReqICB_162_reserved" 163 "AIParkngReqICB_163_reserved" 164 "AIParkngReqICB_164_reserved" 165 "AIParkngReqICB_165_reserved" 166 "AIParkngReqICB_166_reserved" 167 "AIParkngReqICB_167_reserved" 168 "AIParkngReqICB_168_reserved" 169 "AIParkngReqICB_169_reserved" 170 "AIParkngReqICB_170_reserved" 171 "AIParkngReqICB_171_reserved" 172 "AIParkngReqICB_172_reserved" 173 "AIParkngReqICB_173_reserved" 174 "AIParkngReqICB_174_reserved" 175 "AIParkngReqICB_175_reserved" 176 "AIParkngReqICB_176_reserved" 177 "AIParkngReqICB_177_reserved" 178 "AIParkngReqICB_178_reserved" 179 "AIParkngReqICB_179_reserved" 180 "AIParkngReqICB_180_reserved" 181 "AIParkngReqICB_181_reserved" 182 "AIParkngReqICB_182_reserved" 183 "AIParkngReqICB_183_reserved" 184 "AIParkngReqICB_184_reserved" 185 "AIParkngReqICB_185_reserved" 186 "AIParkngReqICB_186_reserved" 187 "AIParkngReqICB_187_reserved" 188 "AIParkngReqICB_188_reserved" 189 "AIParkngReqICB_189_reserved" 190 "AIParkngReqICB_190_reserved" 191 "AIParkngReqICB_191_reserved" 192 "AIParkngReqICB_192_reserved" 193 "AIParkngReqICB_193_reserved" 194 "AIParkngReqICB_194_reserved" 195 "AIParkngReqICB_195_reserved" 196 "AIParkngReqICB_196_reserved" 197 "AIParkngReqICB_197_reserved" 198 "AIParkngReqICB_198_reserved" 199 "AIParkngReqICB_199_reserved" 200 "AIParkngReqICB_200_reserved" 201 "AIParkngReqICB_201_reserved" 202 "AIParkngReqICB_202_reserved" 203 "AIParkngReqICB_203_reserved" 204 "AIParkngReqICB_204_reserved" 205 "AIParkngReqICB_205_reserved" 206 "AIParkngReqICB_206_reserved" 207 "AIParkngReqICB_207_reserved" 208 "AIParkngReqICB_208_reserved" 209 "AIParkngReqICB_209_reserved" 210 "AIParkngReqICB_210_reserved" 211 "AIParkngReqICB_211_reserved" 212 "AIParkngReqICB_212_reserved" 213 "AIParkngReqICB_213_reserved" 214 "AIParkngReqICB_214_reserved" 215 "AIParkngReqICB_215_reserved" 216 "AIParkngReqICB_216_reserved" 217 "AIParkngReqICB_217_reserved" 218 "AIParkngReqICB_218_reserved" 219 "AIParkngReqICB_219_reserved" 220 "AIParkngReqICB_220_reserved" 221 "AIParkngReqICB_221_reserved" 222 "AIParkngReqICB_222_reserved" 223 "AIParkngReqICB_223_reserved" 224 "AIParkngReqICB_224_reserved" 225 "AIParkngReqICB_225_reserved" 226 "AIParkngReqICB_226_reserved" 227 "AIParkngReqICB_227_reserved" 228 "AIParkngReqICB_228_reserved" 229 "AIParkngReqICB_229_reserved" 230 "AIParkngReqICB_230_reserved" 231 "AIParkngReqICB_231_reserved" 232 "AIParkngReqICB_232_reserved" 233 "AIParkngReqICB_233_reserved" 234 "AIParkngReqICB_234_reserved" 235 "AIParkngReqICB_235_reserved" 236 "AIParkngReqICB_236_reserved" 237 "AIParkngReqICB_237_reserved" 238 "AIParkngReqICB_238_reserved" 239 "AIParkngReqICB_239_reserved" 240 "AIParkngReqICB_240_reserved" 241 "AIParkngReqICB_241_reserved" 242 "AIParkngReqICB_242_reserved" 243 "AIParkngReqICB_243_reserved" 244 "AIParkngReqICB_244_reserved" 245 "AIParkngReqICB_245_reserved" 246 "AIParkngReqICB_246_reserved" 247 "AIParkngReqICB_247_reserved" 248 "AIParkngReqICB_248_reserved" 249 "AIParkngReqICB_249_reserved" 250 "AIParkngReqICB_250_reserved" 251 "AIParkngReqICB_251_reserved" 252 "AIParkngReqICB_252_reserved" 253 "AIParkngReqICB_253_reserved" 254 "AIParkngReqICB_254_reserved" 255 "AIParkngReqICB_255_reserved";
VAL_ 728 IAIParkngScngAutocBtn 0 "AIParkngScngAutocBtn_0_NoRequest" 1 "AIParkngScngAutocBtn_1_ShortPress" 2 "AIParkngScngAutocBtn_2_reserved" 3 "AIParkngScngAutocBtn_3_reserved" 4 "AIParkngScngAutocBtn_4_reserved" 5 "AIParkngScngAutocBtn_5_reserved" 6 "AIParkngScngAutocBtn_6_reserved" 7 "AIParkngScngAutocBtn_7_reserved" 8 "AIParkngScngAutocBtn_8_reserved" 9 "AIParkngScngAutocBtn_9_reserved" 10 "AIParkngScngAutocBtn_10_reserved" 11 "AIParkngScngAutocBtn_11_reserved" 12 "AIParkngScngAutocBtn_12_reserved" 13 "AIParkngScngAutocBtn_13_reserved" 14 "AIParkngScngAutocBtn_14_reserved" 15 "AIParkngScngAutocBtn_15_reserved";
VAL_ 1216 IICBVC_NM_BSMtoRMS_BKPCANFD 0 "ICBVC_NM_BSMtoRMS_BKPCANFD_0_False" 1 "ICBVC_NM_BSMtoRMS_BKPCANFD_1_True";
VAL_ 1216 IICBVC_NM_PBSMtoRMS_BKPCANFD 0 "ICBVC_NM_PBSMtoRMS_BKPCANFD_0_False" 1 "ICBVC_NM_PBSMtoRMS_BKPCANFD_1_True";
VAL_ 1216 IICBVC_NM_RMStoNOS_BKPCANFD 0 "ICBVC_NM_RMStoNOS_BKPCANFD_0_False" 1 "ICBVC_NM_RMStoNOS_BKPCANFD_1_True";
VAL_ 1216 IICBVC_NM_RSStoNOS_BKPCANFD 0 "ICBVC_NM_RSStoNOS_BKPCANFD_0_False" 1 "ICBVC_NM_RSStoNOS_BKPCANFD_1_True";
VAL_ 1216 IICBVC_NM_RSStoRMS_BKPCANFD 0 "ICBVC_NM_RSStoRMS_BKPCANFD_0_False" 1 "ICBVC_NM_RSStoRMS_BKPCANFD_1_True";
VAL_ 1216 IICBVC_NM_NOStoRMS_BKPCANFD 0 "ICBVC_NM_NOStoRMS_BKPCANFD_0_False" 1 "ICBVC_NM_NOStoRMS_BKPCANFD_1_True";
VAL_ 1216 IICBVC_NM_NOSSta_BKPCANFD 0 "ICBVC_NM_NOSSta_BKPCANFD_0_False" 1 "ICBVC_NM_NOSSta_BKPCANFD_1_True";
VAL_ 1216 IICBVC_NM_RMSSta_BKPCANFD 0 "ICBVC_NM_RMSSta_BKPCANFD_0_False" 1 "ICBVC_NM_RMSSta_BKPCANFD_1_True";
VAL_ 1216 IICBVC_NWI_BKPCANFD 0 "ICBVC_NWI_BKPCANFD_0_NoWakeNetworkSource";
VAL_ 1216 IICBVC_NOI_BKPCANFD 0 "ICBVC_NOI_BKPCANFD_0_NoRequest" 65535 "ICBVC_NOI_BKPCANFD_65535_AllNetworkOperationActive";
VAL_ 1216 IICBVC_NKI_BKPCANFD 0 "ICBVC_NKI_BKPCANFD_0_NoRequest" 1 "ICBVC_NKI_BKPCANFD_1_PowerModeIsNonOFF";
VAL_ 790 IFOTAStatusValid 0 "FOTAStatusValid_0_invalid" 1 "FOTAStatusValid_1_valid";
VAL_ 790 IFOTAStatus 0 "FOTAStatus_0_NoFOTA" 1 "FOTAStatus_1_FOTA" 2 "FOTAStatus_2_FOTAFinish" 3 "FOTAStatus_3_PreFOTA" 4 "FOTAStatus_4_Download";
VAL_ 790 IFOTATarget 0 "FOTATarget_0_NoFOTA" 1 "FOTATarget_1_HVUnavailableGroup" 2 "FOTATarget_2_HMIUnavailableGroup" 3 "FOTATarget_3_LockUnavailableGroup" 4 "FOTATarget_4_Download" 5 "FOTATarget_5_NomalGroup" 6 "FOTATarget_6_HV_LockUnavailableGroup";
VAL_ 790 IFOTATargetValid 0 "FOTATargetValid_0_invalid" 1 "FOTATargetValid_1_valid";
VAL_ 1008 IOtsdAirTemCrValV 0 "OtsdAirTemCrValV_0_Valid" 1 "OtsdAirTemCrValV_1_Invalid";
VAL_ 1008 IOtsdAirTemCrValMsk 0 "OtsdAirTemCrValMsk_0_Dont_Use_Data" 1 "OtsdAirTemCrValMsk_1_Use_Data";
VAL_ 1008 IOtsdAirTemVDA 0 "OtsdAirTemVDA_0_Virtual_Device_Unavailable" 1 "OtsdAirTemVDA_1_Virtual_Device_Available";
VAL_ 1023 IRgnLvReqFICMV 0 "RgnLvReqFICMV_0_Valid" 1 "RgnLvReqFICMV_1_Invalid";
VAL_ 1023 IRgnLvReqFICM 0 "RgnLvReqFICM_0_Low" 1 "RgnLvReqFICM_1_Standard" 2 "RgnLvReqFICM_2_High" 3 "RgnLvReqFICM_3_Auto" 4 "RgnLvReqFICM_4_RegenLimited" 5 "RgnLvReqFICM_5_Off";
VAL_ 1023 ILVBatChrgReqRaw 0 "LVBatChrgReqRaw_0_False" 1 "LVBatChrgReqRaw_1_True";
VAL_ 1023 ILVBatChrgReqInhbt 0 "LVBatChrgReqInhbt_0_False" 1 "LVBatChrgReqInhbt_1_True";
VAL_ 1023 ILVBatEnrgSufct 0 "LVBatEnrgSufct_0_False" 1 "LVBatEnrgSufct_1_True";
VAL_ 1023 ILVBatEnrgLow 0 "LVBatEnrgLow_0_False" 1 "LVBatEnrgLow_1_True";
VAL_ 1023 IVehFOTAHVReq 0 "VehFOTAHVReq_0_No_Request" 1 "VehFOTAHVReq_1_HV_Shutdown_Request" 2 "VehFOTAHVReq_2_HV_Establish_Request" 3 "VehFOTAHVReq_3_Reserved";
VAL_ 1023 IEnrgSplReqV 0 "EnrgSplReqV_0_Valid" 1 "EnrgSplReqV_1_Invalid";
VAL_ 1023 IEnrgSplReq 0 "EnrgSplReq_0_False" 1 "EnrgSplReq_1_True";
VAL_ 1023 IPMDCSta 0 "PMDCSta_0_No_Error" 1 "PMDCSta_1_Communication_Error" 2 "PMDCSta_2_LV_System_Error";
VAL_ 1023 IVehFotaReq 0 "VehFotaReq_0_No_FOTA" 1 "VehFotaReq_1_FOTA";
VAL_ 1023 IVehEnrgRdyLvlV 0 "VehEnrgRdyLvlV_0_Valid" 1 "VehEnrgRdyLvlV_1_Invalid";
VAL_ 1023 IVehEnrgRdyLvl 0 "VehEnrgRdyLvl_0_Level0" 1 "VehEnrgRdyLvl_1_Level1" 2 "VehEnrgRdyLvl_2_Level2" 3 "VehEnrgRdyLvl_3_Level3" 4 "VehEnrgRdyLvl_4_Level4" 5 "VehEnrgRdyLvl_5_Level5" 6 "VehEnrgRdyLvl_6_Level6" 7 "VehEnrgRdyLvl_7_Level7";
VAL_ 1023 IEPTToqCustSetngReqV 0 "EPTToqCustSetngReqV_0_Valid" 1 "EPTToqCustSetngReqV_1_Invalid";
VAL_ 1023 IEPTToqCustSetngReq 0 "EPTToqCustSetngReq_0_Unavailable" 1 "EPTToqCustSetngReq_1_EcoMode" 2 "EPTToqCustSetngReq_2_NormalMode" 3 "EPTToqCustSetngReq_3_SportMode";
VAL_ 1023 ILVBatSelfWakeupFlg 0 "LVBatSelfWakeupFlg_0_False" 1 "LVBatSelfWakeupFlg_1_True";
VAL_ 1023 IEnrgSplReqRaw 0 "EnrgSplReqRaw_0_False" 1 "EnrgSplReqRaw_1_True";
VAL_ 922 IAVMDspReq 0 "AVMDspReq_0_NoRequest" 1 "AVMDspReq_1_open" 2 "AVMDspReq_2_close" 3 "AVMDspReq_3_reserve";
VAL_ 922 IAutoViewChg 0 "AutoViewChg_0_Autonoums" 1 "AutoViewChg_1_Manual";
VAL_ 922 IAlisysrdy 0 "Alisysrdy_0_NotReady" 1 "Alisysrdy_1_ready";
VAL_ 922 ILiftMdReq 0 "LiftMdReq_0_NoRequest" 1 "LiftMdReq_1_OFF" 2 "LiftMdReq_2_ON" 3 "LiftMdReq_3_Reserved";
VAL_ 922 IEasyLdMdReq 0 "EasyLdMdReq_0_NoRequest" 1 "EasyLdMdReq_1_OFF" 2 "EasyLdMdReq_2_ON" 3 "EasyLdMdReq_3_Reserved";
VAL_ 922 IEasyEntMdReq 0 "EasyEntMdReq_0_NoRequest" 1 "EasyEntMdReq_1_OFF" 2 "EasyEntMdReq_2_ON" 3 "EasyEntMdReq_3_Reserved";
VAL_ 922 IEasyPssReq 0 "EasyPssReq_0_No_Request" 1 "EasyPssReq_1_Off_Request" 2 "EasyPssReq_2_On_Request" 3 "EasyPssReq_3_Reserved";
VAL_ 922 IIEasyEntMdSetReq 0 "IEasyEntMdSetReq_0_No_Request" 1 "IEasyEntMdSetReq_1_On_Request" 2 "IEasyEntMdSetReq_2_Off_Request" 3 "IEasyEntMdSetReq_3_Reserved";
VAL_ 922 IHDCReq 0 "HDCReq_0_Norequest" 1 "HDCReq_1_ActiveHDC" 2 "HDCReq_2_DeactiveHDC" 3 "HDCReq_3_PressedHDCButton";
VAL_ 922 IEmmsnTestMdFICMV 0 "EmmsnTestMdFICMV_0_valid" 1 "EmmsnTestMdFICMV_1_invalid";
VAL_ 922 ISusLvlCtrlCustSetngReq 0 "SusLvlCtrlCustSetngReq_0_NoRequest" 1 "SusLvlCtrlCustSetngReq_1_HighLevel" 2 "SusLvlCtrlCustSetngReq_2_NormalLevel" 3 "SusLvlCtrlCustSetngReq_3_LowLevel1" 4 "SusLvlCtrlCustSetngReq_4_LowLevel2" 5 "SusLvlCtrlCustSetngReq_5_reserved" 6 "SusLvlCtrlCustSetngReq_6_reserved" 7 "SusLvlCtrlCustSetngReq_7_reserved";
VAL_ 922 IFICMPwrDMdReq 0 "FICMPwrDMdReq_0_Auto" 1 "FICMPwrDMdReq_1_EVFirst" 2 "FICMPwrDMdReq_2_HEVFirst" 3 "FICMPwrDMdReq_3_Reserved" 4 "FICMPwrDMdReq_4_Reserved" 5 "FICMPwrDMdReq_5_Reserved" 6 "FICMPwrDMdReq_6_Reserved" 7 "FICMPwrDMdReq_7_Reserved";
VAL_ 922 ICloseCalib 0 "CloseCalib_0_NoRequest" 1 "CloseCalib_1_CloseCalibration";
VAL_ 922 ICalibFunc 0 "CalibFunc_0_NoRequest" 1 "CalibFunc_1_EndOfLineCalibration" 2 "CalibFunc_2_4sCalibration" 3 "CalibFunc_3_ManualCalibration";
VAL_ 922 IFICMPwrDMdReqV 0 "FICMPwrDMdReqV_0_Valid" 1 "FICMPwrDMdReqV_1_Invalid";
VAL_ 922 IEmmsnTestMdFICM 0 "EmmsnTestMdFICM_0_False" 1 "EmmsnTestMdFICM_1_True";
VAL_ 922 IVehSpdDpdntLvlCtrlReq 0 "VehSpdDpdntLvlCtrlReq_0_NoRequest" 1 "VehSpdDpdntLvlCtrlReq_1_OFF" 2 "VehSpdDpdntLvlCtrlReq_2_ON" 3 "VehSpdDpdntLvlCtrlReq_3_Reserved";
VAL_ 922 IBtmFilgDspReq 0 "BtmFilgDspReq_0_NoRequest" 1 "BtmFilgDspReq_1_Open" 2 "BtmFilgDspReq_2_Close";
VAL_ 922 ISusDmpngCtrlCustSetngReq 0 "SusDmpngCtrlCustSetngReq_0_NoRequest" 1 "SusDmpngCtrlCustSetngReq_1_Comfort_Mode" 2 "SusDmpngCtrlCustSetngReq_2_Normal_Mode" 3 "SusDmpngCtrlCustSetngReq_3_Sport_Mode" 4 "SusDmpngCtrlCustSetngReq_4_advanced_Mode" 5 "SusDmpngCtrlCustSetngReq_5_Reserved" 6 "SusDmpngCtrlCustSetngReq_6_Reserved" 7 "SusDmpngCtrlCustSetngReq_7_Reserved" 8 "SusDmpngCtrlCustSetngReq_8_Reserved" 9 "SusDmpngCtrlCustSetngReq_9_Reserved" 10 "SusDmpngCtrlCustSetngReq_10_Reserved" 11 "SusDmpngCtrlCustSetngReq_11_Reserved" 12 "SusDmpngCtrlCustSetngReq_12_Reserved" 13 "SusDmpngCtrlCustSetngReq_13_Reserved" 14 "SusDmpngCtrlCustSetngReq_14_Reserved" 15 "SusDmpngCtrlCustSetngReq_15_Reserved";
VAL_ 922 ITrgtSOCReqFICMV 0 "TrgtSOCReqFICMV_0_valid" 1 "TrgtSOCReqFICMV_1_invalid";
VAL_ 1006 INavGudcSts 0 "NavGudcSts_0_NotInGuidance" 1 "NavGudcSts_1_InGuidance";
VAL_ 1006 IDsttnTypOfNav 0 "DsttnTypOfNav_0_Unknown" 1 "DsttnTypOfNav_1_SlowChargingStation" 2 "DsttnTypOfNav_2_FastChargingStation";
VAL_ 1006 IEPTSysCoolActvReq 0 "EPTSysCoolActvReq_0_Not_Active" 1 "EPTSysCoolActvReq_1_Active";
VAL_ 1006 IElecEnrgAvgRstReq 0 "ElecEnrgAvgRstReq_0_NoRequest" 1 "ElecEnrgAvgRstReq_1_ResetForTotalElecConsump" 2 "ElecEnrgAvgRstReq_2_ResetForCurrentElecConsump" 3 "ElecEnrgAvgRstReq_3_reserved";
VAL_ 1006 IFICMOnRutWarmOffReqV 0 "FICMOnRutWarmOffReqV_0_Valid" 1 "FICMOnRutWarmOffReqV_1_Invalid";
VAL_ 1006 IFICMChrgCtrlReq 0 "FICMChrgCtrlReq_0_NoRequest" 1 "FICMChrgCtrlReq_1_StartCharge" 2 "FICMChrgCtrlReq_2_StopCharge" 3 "FICMChrgCtrlReq_3_Reserved";
VAL_ 1006 IFICMOnRouteWarmSwReq 0 "FICMOnRouteWarmSwReq_0_No_Request" 1 "FICMOnRouteWarmSwReq_1_Off_Request";
VAL_ 1006 IFICMOnRutWarmOffReq 0 "FICMOnRutWarmOffReq_0_Default" 1 "FICMOnRutWarmOffReq_1_EnableOnRouteWarm" 2 "FICMOnRutWarmOffReq_2_DisableOnRouteWarm";
VAL_ 1006 IIPKSetVehEleclRngAlg 0 "IPKSetVehEleclRngAlg_0_Default" 1 "IPKSetVehEleclRngAlg_1_VehicleElectricRangeRealTimeChange";
VAL_ 1006 IFICMV2XReq 0 "FICMV2XReq_0_default" 1 "FICMV2XReq_1_StartDischarge" 2 "FICMV2XReq_2_StopDischarge";
VAL_ 1006 IFICMEleccLckCtrlReq 0 "FICMEleccLckCtrlReq_0_NoRequest" 1 "FICMEleccLckCtrlReq_1_Lock" 2 "FICMEleccLckCtrlReq_2_Unlock" 3 "FICMEleccLckCtrlReq_3_Reserved";
VAL_ 795 IDCDCVolStpt 254 "DCDCVolStpt_254_Init" 255 "DCDCVolStpt_255_Invalid";
VAL_ 795 ISLIFUpdtIndReq 0 "SLIFUpdtIndReq_0__Off" 1 "SLIFUpdtIndReq_1__On";
VAL_ 795 IEasyLvlReq 0 "EasyLvlReq_0_No_Request" 1 "EasyLvlReq_1_Off_Request" 2 "EasyLvlReq_2_On_Request" 3 "EasyLvlReq_3_Reserved";
VAL_ 795 ISprSportSubItemReqV 0 "SprSportSubItemReqV_0_Valid" 1 "SprSportSubItemReqV_1_Invalid";
VAL_ 795 ISprSportSubItemReq 0 "SprSportSubItemReq_0_Default" 1 "SprSportSubItemReq_1_AstonMartin" 2 "SprSportSubItemReq_2_Lamborghini" 3 "SprSportSubItemReq_3_Ferrari";
VAL_ 907 IVehDrvngMd 0 "VehDrvngMd_0_No_Driving_Mode" 1 "VehDrvngMd_1_Super_ECO" 2 "VehDrvngMd_2_ECO" 3 "VehDrvngMd_3_Normal" 4 "VehDrvngMd_4_Sport" 5 "VehDrvngMd_5_OffRoad" 6 "VehDrvngMd_6_Snow" 7 "VehDrvngMd_7_Customization_Mode" 8 "VehDrvngMd_8_Trace" 9 "VehDrvngMd_9_Uncarsickness" 10 "VehDrvngMd_10_Reserved";
VAL_ 907 IVehLdShedLvl 0 "VehLdShedLvl_0_No_Power_Risk" 1 "VehLdShedLvl_1_Low_Power_Risk" 2 "VehLdShedLvl_2_Middle_Power_Risk" 3 "VehLdShedLvl_3_High_Power_Risk" 4 "VehLdShedLvl_4_Power_management_direct_current_converter_PMDC_broken" 5 "VehLdShedLvl_5_Warning";
VAL_ 907 IVehOdoV 0 "VehOdoV_0_Valid" 1 "VehOdoV_1_Invalid";
VAL_ 907 IFrtPsngAirbagSwStsReqV_Sfty 0 "FrtPsngAirbagSwStsReqV_Sfty_0_False" 1 "FrtPsngAirbagSwStsReqV_Sfty_1_True";
VAL_ 907 IFrtPsngAirbagSwStsReq_Sfty 0 "FrtPsngAirbagSwStsReq_Sfty_0_PassengerAirbagOff" 1 "FrtPsngAirbagSwStsReq_Sfty_1_PassengerAirbagOn";
VAL_ 1345 IVehTiPblshMth 0 "VehTiPblshMth_0_Unknown" 1 "VehTiPblshMth_1_January" 2 "VehTiPblshMth_2_February" 3 "VehTiPblshMth_3_March" 4 "VehTiPblshMth_4_April" 5 "VehTiPblshMth_5_May" 6 "VehTiPblshMth_6_June" 7 "VehTiPblshMth_7_July" 8 "VehTiPblshMth_8_August" 9 "VehTiPblshMth_9_September" 10 "VehTiPblshMth_10_October" 11 "VehTiPblshMth_11_November" 12 "VehTiPblshMth_12_December";
VAL_ 361 INFCAMAvlbly 0 "NFCAMAvlbly_0_False" 1 "NFCAMAvlbly_1_True";
VAL_ 361 ISDMAvlbly 0 "SDMAvlbly_0_False" 1 "SDMAvlbly_1_True";
VAL_ 361 IRHZCUAvlbly 0 "RHZCUAvlbly_0_False" 1 "RHZCUAvlbly_1_True";
VAL_ 361 ILHZCUAvlbly 0 "LHZCUAvlbly_0_False" 1 "LHZCUAvlbly_1_True";
VAL_ 361 ITC_ExtdAvlbly 0 "TC_ExtdAvlbly_0_False" 1 "TC_ExtdAvlbly_1_True";
VAL_ 361 IIBS_SFAvlbly 0 "IBS_SFAvlbly_0_False" 1 "IBS_SFAvlbly_1_True";
VAL_ 361 IEPSAvlbly 0 "EPSAvlbly_0_False" 1 "EPSAvlbly_1_True";
VAL_ 361 ITC_PTAvlbly 0 "TC_PTAvlbly_0_False" 1 "TC_PTAvlbly_1_True";
VAL_ 361 IPICU_PTAvlbly 0 "PICU_PTAvlbly_0_False" 1 "PICU_PTAvlbly_1_True";
VAL_ 361 IPEU_PTAvlbly 0 "PEU_PTAvlbly_0_False" 1 "PEU_PTAvlbly_1_True";
VAL_ 361 IPEU_ERAvlbly 0 "PEU_ERAvlbly_0_False" 1 "PEU_ERAvlbly_1_True";
VAL_ 361 IPICU_ExtdAvlbly 0 "PICU_PTAvlbly_0_False" 1 "PICU_PTAvlbly_1_True";
VAL_ 361 ILHRDAAvlbly 0 "LHRDAAvlbly_0_False" 1 "LHRDAAvlbly_1_True";
VAL_ 361 IIPD_PTAvlbly 0 "IPD_PTAvlbly_0_False" 1 "IPD_PTAvlbly_1_True";
VAL_ 361 IESS_PTAvlbly 0 "ESS_PTAvlbly_0_False" 1 "ESS_PTAvlbly_1_True";
VAL_ 361 ICCU_ExtdAvlbly 0 "CCU_ExtdAvlbly_0_False" 1 "CCU_ExtdAvlbly_1_True";
VAL_ 361 IESS_ExtdAvlbly 0 "ESS_ExtdAvlbly_0_False" 1 "ESS_ExtdAvlbly_1_True";
VAL_ 361 ICCU_PTAvlbly 0 "CCU_PTAvlbly_0_False" 1 "CCU_PTAvlbly_1_True";
VAL_ 361 IIAMAvlbly 0 "IAMAvlbly_0_False" 1 "IAMAvlbly_1_True";
VAL_ 361 IEAC_Avlbly 0 "EAC_Avlbly_0_False" 1 "EAC_Avlbly_1_True";
VAL_ 361 IIPD_SFAvlbly 0 "IPD_SFAvlbly_0_False" 1 "IPD_SFAvlbly_1_True";
VAL_ 361 ICCEOPAvlbly 0 "CCUAvlbly_0_False" 1 "CCUAvlbly_1_True";
VAL_ 361 IRZCU_BKBCANFDAvlbly 0 "RZCU_BKBCANFDAvlbly_0_False" 1 "RZCU_BKBCANFDAvlbly_1_True";
VAL_ 361 IIPD_BKPCANFDAvlbly 0 "ICBAD_BKPCANFDAvlbly_0_False" 1 "ICBAD_BKPCANFDAvlbly_1_True";
VAL_ 361 IIPD_CHCANFDAvlbly 0 "IPD_CHCANFDAvlbly_0_False" 1 "IPD_CHCANFDAvlbly_1_True";
VAL_ 361 IIBS_CHAvlbly 0 "IBS_CHAvlbly_0_False" 1 "IBS_CHAvlbly_1_True";
VAL_ 361 IFDRAvlbly 0 "FDRAvlbly_0_False" 1 "FDRAvlbly_1_True";
VAL_ 361 IRHRDAAvlbly 0 "RHRDAAvlbly_0_False" 1 "RHRDAAvlbly_1_True";
VAL_ 361 IFVCMAvlbly 0 "FDRAvlbly_0_False" 1 "FDRAvlbly_1_True";
VAL_ 361 ITPMSAvlbly 0 "TPMSAvlbly_0_False" 1 "TPMSAvlbly_1_True";
VAL_ 497 IAMRPrtensonReq 0 "AMRPrtensonReq_0_NoRequest" 1 "AMRPrtensonReq_1_Level1Request" 2 "AMRPrtensonReq_2_Level2Request" 3 "AMRPrtensonReq_3_Level3Request" 4 "AMRPrtensonReq_4_Level4Request" 5 "AMRPrtensonReq_5_ShakeWarningRequest";
VAL_ 497 ISysVolMdV 0 "SysVolMdV_0_Valid" 1 "SysVolMdV_1_Invalid";
VAL_ 497 IVehMd 0 "VehMd_0_NORMAL" 1 "VehMd_1_CRASH" 2 "VehMd_2_FACTORY" 3 "VehMd_3_TRANSPORT" 4 "VehMd_4_DYNO" 5 "VehMd_5_EXHIBITION" 6 "VehMd_6_Reserved" 7 "VehMd_7_Reserved" 8 "VehMd_8_Engineering" 9 "VehMd_9_Service";
VAL_ 497 ISysVolV 0 "SysVolV_0_Valid" 1 "SysVolV_1_Invalid";
VAL_ 497 ISysPwrMdV 0 "SysPwrMdV_0_Valid" 1 "SysPwrMdV_1_Invalid";
VAL_ 497 IVehMdV 0 "VehMdV_0_Invalid" 1 "VehMdV_1_Valid";
VAL_ 497 IUsgMdV 0 "UsgMdV_0_Invalid" 1 "UsgMdV_1_Valid";
VAL_ 497 IUsgMd 0 "UsgMd_0_Sleep" 1 "UsgMd_1_Standby" 2 "UsgMd_2_Comfortable" 3 "UsgMd_3_Driving" 4 "UsgMd_4_AIParking" 5 "UsgMd_5_AIPilot" 6 "UsgMd_6_XOTA";
VAL_ 497 IPwrMdMstrRunCrkA 0 "PwrMdMstrRunCrkA_0_Inactive" 1 "PwrMdMstrRunCrkA_1_Active";
VAL_ 497 ISysPwrMd 0 "SysPwrMd_0_Off" 1 "SysPwrMd_1_Accessory" 2 "SysPwrMd_2_Run" 3 "SysPwrMd_3_Crank_Request";
VAL_ 497 IPwrMdMstrAccryA 0 "PwrMdMstrAccryA_0_Inactive" 1 "PwrMdMstrAccryA_1_Active";
VAL_ 497 ISysOpnlMd 0 "SysOpnlMd_0_Normal_Mode" 1 "SysOpnlMd_1_Manufacturing_Mode" 2 "SysOpnlMd_2_Transit_Mode" 3 "SysOpnlMd_3_Show_Room" 4 "SysOpnlMd_4_Storage_Mode" 5 "SysOpnlMd_5_Diagnosic_or_Reprogramming" 6 "SysOpnlMd_6_DYNO_Mode" 7 "SysOpnlMd_7_CRASH_Mode" 8 "SysOpnlMd_8_Engineering" 9 "SysOpnlMd_9_Service";
VAL_ 497 IBPMMstrAvlbly 0 "BPMMstrAvlbly_0_False" 1 "BPMMstrAvlbly_1_True";
VAL_ 497 ISysVolMd 0 "SysVolMd_0_Normal" 1 "SysVolMd_1_Low_System_Voltage" 2 "SysVolMd_2_High_System_Voltage" 3 "SysVolMd_3_Illegal_System_Voltage";
VAL_ 60 ITripCntResetReq 0 "TripCntResetReq_0_NoRequest" 1 "TripCntResetReq_1_EnableRequest";
VAL_ 60 IComKeyEnbReq 0 "ComKeyEnbReq_0_NoRequest" 1 "ComKeyEnbReq_1_EnableRequest";
VAL_ 815 IEGCMPwrSts 0 "EGCMPwrSts_0_OFF" 1 "EGCMPwrSts_1_ON";
VAL_ 815 IESCLPwrSts 0 "ESCLPwrSts_0_OFF" 1 "ESCLPwrSts_1_ON";
VAL_ 815 IBPEPSPwrSts 0 "BPEPSPwrSts_0_OFF" 1 "BPEPSPwrSts_1_ON";
VAL_ 815 IRoofDspPwrSts 0 "RoofDspPwrSts_0_OFF" 1 "RoofDspPwrSts_1_ON";
VAL_ 815 ILHAmbtLampPwrSts 0 "LHAmbtLampPwrSts_0_OFF" 1 "LHAmbtLampPwrSts_1_ON";
VAL_ 815 IOHCPwrSts 0 "OHCPwrSts_0_OFF" 1 "OHCPwrSts_1_ON";
VAL_ 815 ICnsoDspPwrSts 0 "CnsoDspPwrSts_0_OFF" 1 "CnsoDspPwrSts_1_ON";
VAL_ 815 IFLVntngMotPwrSts 0 "FLVntngMotPwrSts_0_OFF" 1 "FLVntngMotPwrSts_1_ON";
VAL_ 815 IFLSLMMPwrSts 0 "FLSLMMPwrSts_0_OFF" 1 "FLSLMMPwrSts_1_ON";
VAL_ 815 IUSBHubPwrSts 0 "USBHubPwrSts_0_OFF" 1 "USBHubPwrSts_1_ON";
VAL_ 815 IDrvrDspPwrSts 0 "DrvrDspPwrSts_0_OFF" 1 "DrvrDspPwrSts_1_ON";
VAL_ 815 ISWSPwrSts 0 "LHSWSPwrSts_0_OFF" 1 "LHSWSPwrSts_1_ON";
VAL_ 815 IBrkSwPwrSts 0 "BrkSwPwrSts_0_OFF" 1 "BrkSwPwrSts_1_ON";
VAL_ 815 IHODMPwrSts 0 "HODMPwrSts_0_OFF" 1 "HODMPwrSts_1_ON";
VAL_ 815 IRLSSPwrSts 0 "RLSSPwrSts_0_OFF" 1 "RLSSPwrSts_1_ON";
VAL_ 815 IETCMPwrSts 0 "ETCMPwrSts_0_OFF" 1 "ETCMPwrSts_1_ON";
VAL_ 815 ILHSWPwrSts 0 "LHSWPwrSts_0_OFF" 1 "LHSWPwrSts_1_ON";
VAL_ 815 INFCAMPwrSts 0 "NFCAMPwrSts_0_OFF" 1 "NFCAMPwrSts_1_ON";
VAL_ 815 INFCSMPwrSts 0 "NFCSMPwrSts_0_OFF" 1 "NFCSMPwrSts_1_ON";
VAL_ 815 IPriEarPwrSts 0 "PriEarPwrSts_0_OFF" 1 "PriEarPwrSts_1_ON";
VAL_ 815 ICnsoUSBPwrSts 0 "CnsoUSBPwrSts_0_OFF" 1 "CnsoUSBPwrSts_1_ON";
VAL_ 815 IRrPDCPwrSts 0 "RrPDCPwrSts_0_OFF" 1 "RrPDCPwrSts_1_ON";
VAL_ 815 IFrtPDCPwrSts 0 "FrtPDCPwrSts_0_OFF" 1 "FrtPDCPwrSts_1_ON";
VAL_ 815 IFVCMPwrSts 0 "FVCMPwrSts_0_OFF" 1 "FVCMPwrSts_1_ON";
VAL_ 815 IHVDCDCPwrSts 0 "HVDCDCPwrSts_0_OFF" 1 "HVDCDCPwrSts_1_ON";
VAL_ 815 ITPMSPwrSts 0 "TPMSPwrSts_0_OFF" 1 "TPMSPwrSts_1_ON";
VAL_ 815 IAIBOXPwrSts 0 "AIBOXPwrSts_0_OFF" 1 "AIBOXPwrSts_1_ON";
VAL_ 815 IAIBOTPwrSts 0 "AIBOTPwrSts_0_OFF" 1 "AIBOTPwrSts_1_ON";
VAL_ 902 IDircnLghtMdSet 0 "DircnLghtMdSet_0_No_Request" 1 "DircnLghtMdSet_1_Off_Request" 2 "DircnLghtMdSet_2_On_Request";
VAL_ 902 IComfortDircnLghtSet 0 "ComfortDircnLghtSet_0_No_Request" 1 "ComfortDircnLghtSet_1_Off_Request" 2 "ComfortDircnLghtSet_2_On_Request";
VAL_ 902 ILbl1FrgrLife 255 "Lbl1FrgrLife_255_no_frgrance";
VAL_ 902 ILbl2FrgrLife 255 "Lbl2FrgrLife_255_no_frgrance";
VAL_ 902 ILbl3FrgrLife 255 "Lbl3FrgrLife_255_no_frgrance";
VAL_ 902 ILbl1FrgrAvlbl 0 "Lbl1FrgrAvlbl_0_No_Fragrance" 1 "Lbl1FrgrAvlbl_1_Type_1" 2 "Lbl1FrgrAvlbl_2_Type_2" 3 "Lbl1FrgrAvlbl_3_Type_3" 4 "Lbl1FrgrAvlbl_4_Type_4" 5 "Lbl1FrgrAvlbl_5_Type_5" 6 "Lbl1FrgrAvlbl_6_Type_6" 7 "Lbl1FrgrAvlbl_7_Type_7" 8 "Lbl1FrgrAvlbl_8_Type_8" 9 "Lbl1FrgrAvlbl_9_Reserved" 10 "Lbl1FrgrAvlbl_10_Reserved" 11 "Lbl1FrgrAvlbl_11_Reserved" 12 "Lbl1FrgrAvlbl_12_Reserved" 13 "Lbl1FrgrAvlbl_13_Reserved" 14 "Lbl1FrgrAvlbl_14_Reserved" 15 "Lbl1FrgrAvlbl_15_Reserved" 16 "Lbl1FrgrAvlbl_16_Reserved" 17 "Lbl1FrgrAvlbl_17_Reserved" 18 "Lbl1FrgrAvlbl_18_Reserved" 19 "Lbl1FrgrAvlbl_19_Reserved" 20 "Lbl1FrgrAvlbl_20_Reserved" 21 "Lbl1FrgrAvlbl_21_Reserved" 22 "Lbl1FrgrAvlbl_22_Reserved" 23 "Lbl1FrgrAvlbl_23_Reserved" 24 "Lbl1FrgrAvlbl_24_Reserved" 25 "Lbl1FrgrAvlbl_25_Reserved" 26 "Lbl1FrgrAvlbl_26_Reserved" 27 "Lbl1FrgrAvlbl_27_Reserved" 28 "Lbl1FrgrAvlbl_28_Reserved" 29 "Lbl1FrgrAvlbl_29_Reserved" 30 "Lbl1FrgrAvlbl_30_Reserved" 31 "Lbl1FrgrAvlbl_31_Reserved" 32 "Lbl1FrgrAvlbl_32_Reserved" 33 "Lbl1FrgrAvlbl_33_Reserved" 34 "Lbl1FrgrAvlbl_34_Reserved" 35 "Lbl1FrgrAvlbl_35_Reserved" 36 "Lbl1FrgrAvlbl_36_Reserved" 37 "Lbl1FrgrAvlbl_37_Reserved" 38 "Lbl1FrgrAvlbl_38_Reserved" 39 "Lbl1FrgrAvlbl_39_Reserved" 40 "Lbl1FrgrAvlbl_40_Reserved" 41 "Lbl1FrgrAvlbl_41_Reserved" 42 "Lbl1FrgrAvlbl_42_Reserved" 43 "Lbl1FrgrAvlbl_43_Reserved" 44 "Lbl1FrgrAvlbl_44_Reserved" 45 "Lbl1FrgrAvlbl_45_Reserved" 46 "Lbl1FrgrAvlbl_46_Reserved" 47 "Lbl1FrgrAvlbl_47_Reserved" 48 "Lbl1FrgrAvlbl_48_Reserved" 49 "Lbl1FrgrAvlbl_49_Reserved" 50 "Lbl1FrgrAvlbl_50_Reserved" 51 "Lbl1FrgrAvlbl_51_Reserved" 52 "Lbl1FrgrAvlbl_52_Reserved" 53 "Lbl1FrgrAvlbl_53_Reserved" 54 "Lbl1FrgrAvlbl_54_Reserved" 55 "Lbl1FrgrAvlbl_55_Reserved" 56 "Lbl1FrgrAvlbl_56_Reserved" 57 "Lbl1FrgrAvlbl_57_Reserved" 58 "Lbl1FrgrAvlbl_58_Reserved" 59 "Lbl1FrgrAvlbl_59_Reserved" 60 "Lbl1FrgrAvlbl_60_Reserved" 61 "Lbl1FrgrAvlbl_61_Reserved" 62 "Lbl1FrgrAvlbl_62_Reserved" 63 "Lbl1FrgrAvlbl_63_Reserved" 64 "Lbl1FrgrAvlbl_64_Reserved" 65 "Lbl1FrgrAvlbl_65_Reserved" 66 "Lbl1FrgrAvlbl_66_Reserved" 67 "Lbl1FrgrAvlbl_67_Reserved" 68 "Lbl1FrgrAvlbl_68_Reserved" 69 "Lbl1FrgrAvlbl_69_Reserved" 70 "Lbl1FrgrAvlbl_70_Reserved" 71 "Lbl1FrgrAvlbl_71_Reserved" 72 "Lbl1FrgrAvlbl_72_Reserved" 73 "Lbl1FrgrAvlbl_73_Reserved" 74 "Lbl1FrgrAvlbl_74_Reserved" 75 "Lbl1FrgrAvlbl_75_Reserved" 76 "Lbl1FrgrAvlbl_76_Reserved" 77 "Lbl1FrgrAvlbl_77_Reserved" 78 "Lbl1FrgrAvlbl_78_Reserved" 79 "Lbl1FrgrAvlbl_79_Reserved" 80 "Lbl1FrgrAvlbl_80_Reserved" 81 "Lbl1FrgrAvlbl_81_Reserved" 82 "Lbl1FrgrAvlbl_82_Reserved" 83 "Lbl1FrgrAvlbl_83_Reserved" 84 "Lbl1FrgrAvlbl_84_Reserved" 85 "Lbl1FrgrAvlbl_85_Reserved" 86 "Lbl1FrgrAvlbl_86_Reserved" 87 "Lbl1FrgrAvlbl_87_Reserved" 88 "Lbl1FrgrAvlbl_88_Reserved" 89 "Lbl1FrgrAvlbl_89_Reserved" 90 "Lbl1FrgrAvlbl_90_Reserved" 91 "Lbl1FrgrAvlbl_91_Reserved" 92 "Lbl1FrgrAvlbl_92_Reserved" 93 "Lbl1FrgrAvlbl_93_Reserved" 94 "Lbl1FrgrAvlbl_94_Reserved" 95 "Lbl1FrgrAvlbl_95_Reserved" 96 "Lbl1FrgrAvlbl_96_Reserved" 97 "Lbl1FrgrAvlbl_97_Reserved" 98 "Lbl1FrgrAvlbl_98_Reserved" 99 "Lbl1FrgrAvlbl_99_Reserved" 100 "Lbl1FrgrAvlbl_100_Reserved" 101 "Lbl1FrgrAvlbl_101_Reserved" 102 "Lbl1FrgrAvlbl_102_Reserved" 103 "Lbl1FrgrAvlbl_103_Reserved" 104 "Lbl1FrgrAvlbl_104_Reserved" 105 "Lbl1FrgrAvlbl_105_Reserved" 106 "Lbl1FrgrAvlbl_106_Reserved" 107 "Lbl1FrgrAvlbl_107_Reserved" 108 "Lbl1FrgrAvlbl_108_Reserved" 109 "Lbl1FrgrAvlbl_109_Reserved" 110 "Lbl1FrgrAvlbl_110_Reserved" 111 "Lbl1FrgrAvlbl_111_Reserved" 112 "Lbl1FrgrAvlbl_112_Reserved" 113 "Lbl1FrgrAvlbl_113_Reserved" 114 "Lbl1FrgrAvlbl_114_Reserved" 115 "Lbl1FrgrAvlbl_115_Reserved" 116 "Lbl1FrgrAvlbl_116_Reserved" 117 "Lbl1FrgrAvlbl_117_Reserved" 118 "Lbl1FrgrAvlbl_118_Reserved" 119 "Lbl1FrgrAvlbl_119_Reserved" 120 "Lbl1FrgrAvlbl_120_Reserved" 121 "Lbl1FrgrAvlbl_121_Reserved" 122 "Lbl1FrgrAvlbl_122_Reserved" 123 "Lbl1FrgrAvlbl_123_Reserved" 124 "Lbl1FrgrAvlbl_124_Reserved" 125 "Lbl1FrgrAvlbl_125_Reserved" 126 "Lbl1FrgrAvlbl_126_Reserved" 127 "Lbl1FrgrAvlbl_127_Reserved" 128 "Lbl1FrgrAvlbl_128_Reserved" 129 "Lbl1FrgrAvlbl_129_Reserved" 130 "Lbl1FrgrAvlbl_130_Reserved" 131 "Lbl1FrgrAvlbl_131_Reserved" 132 "Lbl1FrgrAvlbl_132_Reserved" 133 "Lbl1FrgrAvlbl_133_Reserved" 134 "Lbl1FrgrAvlbl_134_Reserved" 135 "Lbl1FrgrAvlbl_135_Reserved" 136 "Lbl1FrgrAvlbl_136_Reserved" 137 "Lbl1FrgrAvlbl_137_Reserved" 138 "Lbl1FrgrAvlbl_138_Reserved" 139 "Lbl1FrgrAvlbl_139_Reserved" 140 "Lbl1FrgrAvlbl_140_Reserved" 141 "Lbl1FrgrAvlbl_141_Reserved" 142 "Lbl1FrgrAvlbl_142_Reserved" 143 "Lbl1FrgrAvlbl_143_Reserved" 144 "Lbl1FrgrAvlbl_144_Reserved" 145 "Lbl1FrgrAvlbl_145_Reserved" 146 "Lbl1FrgrAvlbl_146_Reserved" 147 "Lbl1FrgrAvlbl_147_Reserved" 148 "Lbl1FrgrAvlbl_148_Reserved" 149 "Lbl1FrgrAvlbl_149_Reserved" 150 "Lbl1FrgrAvlbl_150_Reserved" 151 "Lbl1FrgrAvlbl_151_Reserved" 152 "Lbl1FrgrAvlbl_152_Reserved" 153 "Lbl1FrgrAvlbl_153_Reserved" 154 "Lbl1FrgrAvlbl_154_Reserved" 155 "Lbl1FrgrAvlbl_155_Reserved" 156 "Lbl1FrgrAvlbl_156_Reserved" 157 "Lbl1FrgrAvlbl_157_Reserved" 158 "Lbl1FrgrAvlbl_158_Reserved" 159 "Lbl1FrgrAvlbl_159_Reserved" 160 "Lbl1FrgrAvlbl_160_Reserved" 161 "Lbl1FrgrAvlbl_161_Reserved" 162 "Lbl1FrgrAvlbl_162_Reserved" 163 "Lbl1FrgrAvlbl_163_Reserved" 164 "Lbl1FrgrAvlbl_164_Reserved" 165 "Lbl1FrgrAvlbl_165_Reserved" 166 "Lbl1FrgrAvlbl_166_Reserved" 167 "Lbl1FrgrAvlbl_167_Reserved" 168 "Lbl1FrgrAvlbl_168_Reserved" 169 "Lbl1FrgrAvlbl_169_Reserved" 170 "Lbl1FrgrAvlbl_170_Reserved" 171 "Lbl1FrgrAvlbl_171_Reserved" 172 "Lbl1FrgrAvlbl_172_Reserved" 173 "Lbl1FrgrAvlbl_173_Reserved" 174 "Lbl1FrgrAvlbl_174_Reserved" 175 "Lbl1FrgrAvlbl_175_Reserved" 176 "Lbl1FrgrAvlbl_176_Reserved" 177 "Lbl1FrgrAvlbl_177_Reserved" 178 "Lbl1FrgrAvlbl_178_Reserved" 179 "Lbl1FrgrAvlbl_179_Reserved" 180 "Lbl1FrgrAvlbl_180_Reserved" 181 "Lbl1FrgrAvlbl_181_Reserved" 182 "Lbl1FrgrAvlbl_182_Reserved" 183 "Lbl1FrgrAvlbl_183_Reserved" 184 "Lbl1FrgrAvlbl_184_Reserved" 185 "Lbl1FrgrAvlbl_185_Reserved" 186 "Lbl1FrgrAvlbl_186_Reserved" 187 "Lbl1FrgrAvlbl_187_Reserved" 188 "Lbl1FrgrAvlbl_188_Reserved" 189 "Lbl1FrgrAvlbl_189_Reserved" 190 "Lbl1FrgrAvlbl_190_Reserved" 191 "Lbl1FrgrAvlbl_191_Reserved" 192 "Lbl1FrgrAvlbl_192_Reserved" 193 "Lbl1FrgrAvlbl_193_Reserved" 194 "Lbl1FrgrAvlbl_194_Reserved" 195 "Lbl1FrgrAvlbl_195_Reserved" 196 "Lbl1FrgrAvlbl_196_Reserved" 197 "Lbl1FrgrAvlbl_197_Reserved" 198 "Lbl1FrgrAvlbl_198_Reserved" 199 "Lbl1FrgrAvlbl_199_Reserved" 200 "Lbl1FrgrAvlbl_200_Reserved" 201 "Lbl1FrgrAvlbl_201_Reserved" 202 "Lbl1FrgrAvlbl_202_Reserved" 203 "Lbl1FrgrAvlbl_203_Reserved" 204 "Lbl1FrgrAvlbl_204_Reserved" 205 "Lbl1FrgrAvlbl_205_Reserved" 206 "Lbl1FrgrAvlbl_206_Reserved" 207 "Lbl1FrgrAvlbl_207_Reserved" 208 "Lbl1FrgrAvlbl_208_Reserved" 209 "Lbl1FrgrAvlbl_209_Reserved" 210 "Lbl1FrgrAvlbl_210_Reserved" 211 "Lbl1FrgrAvlbl_211_Reserved" 212 "Lbl1FrgrAvlbl_212_Reserved" 213 "Lbl1FrgrAvlbl_213_Reserved" 214 "Lbl1FrgrAvlbl_214_Reserved" 215 "Lbl1FrgrAvlbl_215_Reserved" 216 "Lbl1FrgrAvlbl_216_Reserved" 217 "Lbl1FrgrAvlbl_217_Reserved" 218 "Lbl1FrgrAvlbl_218_Reserved" 219 "Lbl1FrgrAvlbl_219_Reserved" 220 "Lbl1FrgrAvlbl_220_Reserved" 221 "Lbl1FrgrAvlbl_221_Reserved" 222 "Lbl1FrgrAvlbl_222_Reserved" 223 "Lbl1FrgrAvlbl_223_Reserved" 224 "Lbl1FrgrAvlbl_224_Reserved" 225 "Lbl1FrgrAvlbl_225_Reserved" 226 "Lbl1FrgrAvlbl_226_Reserved" 227 "Lbl1FrgrAvlbl_227_Reserved" 228 "Lbl1FrgrAvlbl_228_Reserved" 229 "Lbl1FrgrAvlbl_229_Reserved" 230 "Lbl1FrgrAvlbl_230_Reserved" 231 "Lbl1FrgrAvlbl_231_Reserved" 232 "Lbl1FrgrAvlbl_232_Reserved" 233 "Lbl1FrgrAvlbl_233_Reserved" 234 "Lbl1FrgrAvlbl_234_Reserved" 235 "Lbl1FrgrAvlbl_235_Reserved" 236 "Lbl1FrgrAvlbl_236_Reserved" 237 "Lbl1FrgrAvlbl_237_Reserved" 238 "Lbl1FrgrAvlbl_238_Reserved" 239 "Lbl1FrgrAvlbl_239_Reserved" 240 "Lbl1FrgrAvlbl_240_Reserved" 241 "Lbl1FrgrAvlbl_241_Reserved" 242 "Lbl1FrgrAvlbl_242_Reserved" 243 "Lbl1FrgrAvlbl_243_Reserved" 244 "Lbl1FrgrAvlbl_244_Reserved" 245 "Lbl1FrgrAvlbl_245_Reserved" 246 "Lbl1FrgrAvlbl_246_Reserved" 247 "Lbl1FrgrAvlbl_247_Reserved" 248 "Lbl1FrgrAvlbl_248_Reserved" 249 "Lbl1FrgrAvlbl_249_Reserved" 250 "Lbl1FrgrAvlbl_250_Reserved" 251 "Lbl1FrgrAvlbl_251_Reserved" 252 "Lbl1FrgrAvlbl_252_Reserved" 253 "Lbl1FrgrAvlbl_253_Reserved" 254 "Lbl1FrgrAvlbl_254_Reserved" 255 "Lbl1FrgrAvlbl_255_Reserved";
VAL_ 902 ILbl2FrgrAvlbl 0 "Lbl2FrgrAvlbl_0__No_Fragrance" 1 "Lbl2FrgrAvlbl_1_Type_1" 2 "Lbl2FrgrAvlbl_2_Type_2" 3 "Lbl2FrgrAvlbl_3_Type_3" 4 "Lbl2FrgrAvlbl_4_Type_4" 5 "Lbl2FrgrAvlbl_5_Type_5" 6 "Lbl2FrgrAvlbl_6_Type_6" 7 "Lbl2FrgrAvlbl_7_Type_7" 8 "Lbl2FrgrAvlbl_8_Type_8" 9 "Lbl2FrgrAvlbl_9_Reserved" 10 "Lbl2FrgrAvlbl_10_Reserved" 11 "Lbl2FrgrAvlbl_11_Reserved" 12 "Lbl2FrgrAvlbl_12_Reserved" 13 "Lbl2FrgrAvlbl_13_Reserved" 14 "Lbl2FrgrAvlbl_14_Reserved" 15 "Lbl2FrgrAvlbl_15_Reserved" 16 "Lbl2FrgrAvlbl_16_Reserved" 17 "Lbl2FrgrAvlbl_17_Reserved" 18 "Lbl2FrgrAvlbl_18_Reserved" 19 "Lbl2FrgrAvlbl_19_Reserved" 20 "Lbl2FrgrAvlbl_20_Reserved" 21 "Lbl2FrgrAvlbl_21_Reserved" 22 "Lbl2FrgrAvlbl_22_Reserved" 23 "Lbl2FrgrAvlbl_23_Reserved" 24 "Lbl2FrgrAvlbl_24_Reserved" 25 "Lbl2FrgrAvlbl_25_Reserved" 26 "Lbl2FrgrAvlbl_26_Reserved" 27 "Lbl2FrgrAvlbl_27_Reserved" 28 "Lbl2FrgrAvlbl_28_Reserved" 29 "Lbl2FrgrAvlbl_29_Reserved" 30 "Lbl2FrgrAvlbl_30_Reserved" 31 "Lbl2FrgrAvlbl_31_Reserved" 32 "Lbl2FrgrAvlbl_32_Reserved" 33 "Lbl2FrgrAvlbl_33_Reserved" 34 "Lbl2FrgrAvlbl_34_Reserved" 35 "Lbl2FrgrAvlbl_35_Reserved" 36 "Lbl2FrgrAvlbl_36_Reserved" 37 "Lbl2FrgrAvlbl_37_Reserved" 38 "Lbl2FrgrAvlbl_38_Reserved" 39 "Lbl2FrgrAvlbl_39_Reserved" 40 "Lbl2FrgrAvlbl_40_Reserved" 41 "Lbl2FrgrAvlbl_41_Reserved" 42 "Lbl2FrgrAvlbl_42_Reserved" 43 "Lbl2FrgrAvlbl_43_Reserved" 44 "Lbl2FrgrAvlbl_44_Reserved" 45 "Lbl2FrgrAvlbl_45_Reserved" 46 "Lbl2FrgrAvlbl_46_Reserved" 47 "Lbl2FrgrAvlbl_47_Reserved" 48 "Lbl2FrgrAvlbl_48_Reserved" 49 "Lbl2FrgrAvlbl_49_Reserved" 50 "Lbl2FrgrAvlbl_50_Reserved" 51 "Lbl2FrgrAvlbl_51_Reserved" 52 "Lbl2FrgrAvlbl_52_Reserved" 53 "Lbl2FrgrAvlbl_53_Reserved" 54 "Lbl2FrgrAvlbl_54_Reserved" 55 "Lbl2FrgrAvlbl_55_Reserved" 56 "Lbl2FrgrAvlbl_56_Reserved" 57 "Lbl2FrgrAvlbl_57_Reserved" 58 "Lbl2FrgrAvlbl_58_Reserved" 59 "Lbl2FrgrAvlbl_59_Reserved" 60 "Lbl2FrgrAvlbl_60_Reserved" 61 "Lbl2FrgrAvlbl_61_Reserved" 62 "Lbl2FrgrAvlbl_62_Reserved" 63 "Lbl2FrgrAvlbl_63_Reserved" 64 "Lbl2FrgrAvlbl_64_Reserved" 65 "Lbl2FrgrAvlbl_65_Reserved" 66 "Lbl2FrgrAvlbl_66_Reserved" 67 "Lbl2FrgrAvlbl_67_Reserved" 68 "Lbl2FrgrAvlbl_68_Reserved" 69 "Lbl2FrgrAvlbl_69_Reserved" 70 "Lbl2FrgrAvlbl_70_Reserved" 71 "Lbl2FrgrAvlbl_71_Reserved" 72 "Lbl2FrgrAvlbl_72_Reserved" 73 "Lbl2FrgrAvlbl_73_Reserved" 74 "Lbl2FrgrAvlbl_74_Reserved" 75 "Lbl2FrgrAvlbl_75_Reserved" 76 "Lbl2FrgrAvlbl_76_Reserved" 77 "Lbl2FrgrAvlbl_77_Reserved" 78 "Lbl2FrgrAvlbl_78_Reserved" 79 "Lbl2FrgrAvlbl_79_Reserved" 80 "Lbl2FrgrAvlbl_80_Reserved" 81 "Lbl2FrgrAvlbl_81_Reserved" 82 "Lbl2FrgrAvlbl_82_Reserved" 83 "Lbl2FrgrAvlbl_83_Reserved" 84 "Lbl2FrgrAvlbl_84_Reserved" 85 "Lbl2FrgrAvlbl_85_Reserved" 86 "Lbl2FrgrAvlbl_86_Reserved" 87 "Lbl2FrgrAvlbl_87_Reserved" 88 "Lbl2FrgrAvlbl_88_Reserved" 89 "Lbl2FrgrAvlbl_89_Reserved" 90 "Lbl2FrgrAvlbl_90_Reserved" 91 "Lbl2FrgrAvlbl_91_Reserved" 92 "Lbl2FrgrAvlbl_92_Reserved" 93 "Lbl2FrgrAvlbl_93_Reserved" 94 "Lbl2FrgrAvlbl_94_Reserved" 95 "Lbl2FrgrAvlbl_95_Reserved" 96 "Lbl2FrgrAvlbl_96_Reserved" 97 "Lbl2FrgrAvlbl_97_Reserved" 98 "Lbl2FrgrAvlbl_98_Reserved" 99 "Lbl2FrgrAvlbl_99_Reserved" 100 "Lbl2FrgrAvlbl_100_Reserved" 101 "Lbl2FrgrAvlbl_101_Reserved" 102 "Lbl2FrgrAvlbl_102_Reserved" 103 "Lbl2FrgrAvlbl_103_Reserved" 104 "Lbl2FrgrAvlbl_104_Reserved" 105 "Lbl2FrgrAvlbl_105_Reserved" 106 "Lbl2FrgrAvlbl_106_Reserved" 107 "Lbl2FrgrAvlbl_107_Reserved" 108 "Lbl2FrgrAvlbl_108_Reserved" 109 "Lbl2FrgrAvlbl_109_Reserved" 110 "Lbl2FrgrAvlbl_110_Reserved" 111 "Lbl2FrgrAvlbl_111_Reserved" 112 "Lbl2FrgrAvlbl_112_Reserved" 113 "Lbl2FrgrAvlbl_113_Reserved" 114 "Lbl2FrgrAvlbl_114_Reserved" 115 "Lbl2FrgrAvlbl_115_Reserved" 116 "Lbl2FrgrAvlbl_116_Reserved" 117 "Lbl2FrgrAvlbl_117_Reserved" 118 "Lbl2FrgrAvlbl_118_Reserved" 119 "Lbl2FrgrAvlbl_119_Reserved" 120 "Lbl2FrgrAvlbl_120_Reserved" 121 "Lbl2FrgrAvlbl_121_Reserved" 122 "Lbl2FrgrAvlbl_122_Reserved" 123 "Lbl2FrgrAvlbl_123_Reserved" 124 "Lbl2FrgrAvlbl_124_Reserved" 125 "Lbl2FrgrAvlbl_125_Reserved" 126 "Lbl2FrgrAvlbl_126_Reserved" 127 "Lbl2FrgrAvlbl_127_Reserved" 128 "Lbl2FrgrAvlbl_128_Reserved" 129 "Lbl2FrgrAvlbl_129_Reserved" 130 "Lbl2FrgrAvlbl_130_Reserved" 131 "Lbl2FrgrAvlbl_131_Reserved" 132 "Lbl2FrgrAvlbl_132_Reserved" 133 "Lbl2FrgrAvlbl_133_Reserved" 134 "Lbl2FrgrAvlbl_134_Reserved" 135 "Lbl2FrgrAvlbl_135_Reserved" 136 "Lbl2FrgrAvlbl_136_Reserved" 137 "Lbl2FrgrAvlbl_137_Reserved" 138 "Lbl2FrgrAvlbl_138_Reserved" 139 "Lbl2FrgrAvlbl_139_Reserved" 140 "Lbl2FrgrAvlbl_140_Reserved" 141 "Lbl2FrgrAvlbl_141_Reserved" 142 "Lbl2FrgrAvlbl_142_Reserved" 143 "Lbl2FrgrAvlbl_143_Reserved" 144 "Lbl2FrgrAvlbl_144_Reserved" 145 "Lbl2FrgrAvlbl_145_Reserved" 146 "Lbl2FrgrAvlbl_146_Reserved" 147 "Lbl2FrgrAvlbl_147_Reserved" 148 "Lbl2FrgrAvlbl_148_Reserved" 149 "Lbl2FrgrAvlbl_149_Reserved" 150 "Lbl2FrgrAvlbl_150_Reserved" 151 "Lbl2FrgrAvlbl_151_Reserved" 152 "Lbl2FrgrAvlbl_152_Reserved" 153 "Lbl2FrgrAvlbl_153_Reserved" 154 "Lbl2FrgrAvlbl_154_Reserved" 155 "Lbl2FrgrAvlbl_155_Reserved" 156 "Lbl2FrgrAvlbl_156_Reserved" 157 "Lbl2FrgrAvlbl_157_Reserved" 158 "Lbl2FrgrAvlbl_158_Reserved" 159 "Lbl2FrgrAvlbl_159_Reserved" 160 "Lbl2FrgrAvlbl_160_Reserved" 161 "Lbl2FrgrAvlbl_161_Reserved" 162 "Lbl2FrgrAvlbl_162_Reserved" 163 "Lbl2FrgrAvlbl_163_Reserved" 164 "Lbl2FrgrAvlbl_164_Reserved" 165 "Lbl2FrgrAvlbl_165_Reserved" 166 "Lbl2FrgrAvlbl_166_Reserved" 167 "Lbl2FrgrAvlbl_167_Reserved" 168 "Lbl2FrgrAvlbl_168_Reserved" 169 "Lbl2FrgrAvlbl_169_Reserved" 170 "Lbl2FrgrAvlbl_170_Reserved" 171 "Lbl2FrgrAvlbl_171_Reserved" 172 "Lbl2FrgrAvlbl_172_Reserved" 173 "Lbl2FrgrAvlbl_173_Reserved" 174 "Lbl2FrgrAvlbl_174_Reserved" 175 "Lbl2FrgrAvlbl_175_Reserved" 176 "Lbl2FrgrAvlbl_176_Reserved" 177 "Lbl2FrgrAvlbl_177_Reserved" 178 "Lbl2FrgrAvlbl_178_Reserved" 179 "Lbl2FrgrAvlbl_179_Reserved" 180 "Lbl2FrgrAvlbl_180_Reserved" 181 "Lbl2FrgrAvlbl_181_Reserved" 182 "Lbl2FrgrAvlbl_182_Reserved" 183 "Lbl2FrgrAvlbl_183_Reserved" 184 "Lbl2FrgrAvlbl_184_Reserved" 185 "Lbl2FrgrAvlbl_185_Reserved" 186 "Lbl2FrgrAvlbl_186_Reserved" 187 "Lbl2FrgrAvlbl_187_Reserved" 188 "Lbl2FrgrAvlbl_188_Reserved" 189 "Lbl2FrgrAvlbl_189_Reserved" 190 "Lbl2FrgrAvlbl_190_Reserved" 191 "Lbl2FrgrAvlbl_191_Reserved" 192 "Lbl2FrgrAvlbl_192_Reserved" 193 "Lbl2FrgrAvlbl_193_Reserved" 194 "Lbl2FrgrAvlbl_194_Reserved" 195 "Lbl2FrgrAvlbl_195_Reserved" 196 "Lbl2FrgrAvlbl_196_Reserved" 197 "Lbl2FrgrAvlbl_197_Reserved" 198 "Lbl2FrgrAvlbl_198_Reserved" 199 "Lbl2FrgrAvlbl_199_Reserved" 200 "Lbl2FrgrAvlbl_200_Reserved" 201 "Lbl2FrgrAvlbl_201_Reserved" 202 "Lbl2FrgrAvlbl_202_Reserved" 203 "Lbl2FrgrAvlbl_203_Reserved" 204 "Lbl2FrgrAvlbl_204_Reserved" 205 "Lbl2FrgrAvlbl_205_Reserved" 206 "Lbl2FrgrAvlbl_206_Reserved" 207 "Lbl2FrgrAvlbl_207_Reserved" 208 "Lbl2FrgrAvlbl_208_Reserved" 209 "Lbl2FrgrAvlbl_209_Reserved" 210 "Lbl2FrgrAvlbl_210_Reserved" 211 "Lbl2FrgrAvlbl_211_Reserved" 212 "Lbl2FrgrAvlbl_212_Reserved" 213 "Lbl2FrgrAvlbl_213_Reserved" 214 "Lbl2FrgrAvlbl_214_Reserved" 215 "Lbl2FrgrAvlbl_215_Reserved" 216 "Lbl2FrgrAvlbl_216_Reserved" 217 "Lbl2FrgrAvlbl_217_Reserved" 218 "Lbl2FrgrAvlbl_218_Reserved" 219 "Lbl2FrgrAvlbl_219_Reserved" 220 "Lbl2FrgrAvlbl_220_Reserved" 221 "Lbl2FrgrAvlbl_221_Reserved" 222 "Lbl2FrgrAvlbl_222_Reserved" 223 "Lbl2FrgrAvlbl_223_Reserved" 224 "Lbl2FrgrAvlbl_224_Reserved" 225 "Lbl2FrgrAvlbl_225_Reserved" 226 "Lbl2FrgrAvlbl_226_Reserved" 227 "Lbl2FrgrAvlbl_227_Reserved" 228 "Lbl2FrgrAvlbl_228_Reserved" 229 "Lbl2FrgrAvlbl_229_Reserved" 230 "Lbl2FrgrAvlbl_230_Reserved" 231 "Lbl2FrgrAvlbl_231_Reserved" 232 "Lbl2FrgrAvlbl_232_Reserved" 233 "Lbl2FrgrAvlbl_233_Reserved" 234 "Lbl2FrgrAvlbl_234_Reserved" 235 "Lbl2FrgrAvlbl_235_Reserved" 236 "Lbl2FrgrAvlbl_236_Reserved" 237 "Lbl2FrgrAvlbl_237_Reserved" 238 "Lbl2FrgrAvlbl_238_Reserved" 239 "Lbl2FrgrAvlbl_239_Reserved" 240 "Lbl2FrgrAvlbl_240_Reserved" 241 "Lbl2FrgrAvlbl_241_Reserved" 242 "Lbl2FrgrAvlbl_242_Reserved" 243 "Lbl2FrgrAvlbl_243_Reserved" 244 "Lbl2FrgrAvlbl_244_Reserved" 245 "Lbl2FrgrAvlbl_245_Reserved" 246 "Lbl2FrgrAvlbl_246_Reserved" 247 "Lbl2FrgrAvlbl_247_Reserved" 248 "Lbl2FrgrAvlbl_248_Reserved" 249 "Lbl2FrgrAvlbl_249_Reserved" 250 "Lbl2FrgrAvlbl_250_Reserved" 251 "Lbl2FrgrAvlbl_251_Reserved" 252 "Lbl2FrgrAvlbl_252_Reserved" 253 "Lbl2FrgrAvlbl_253_Reserved" 254 "Lbl2FrgrAvlbl_254_Reserved" 255 "Lbl2FrgrAvlbl_255_Reserved";
VAL_ 902 ILbl3FrgrAvlbl 0 "Lbl3FrgrAvlbl_0__No_Fragrance" 1 "Lbl3FrgrAvlbl_1_Type_1" 2 "Lbl3FrgrAvlbl_2_Type_2" 3 "Lbl3FrgrAvlbl_3_Type_3" 4 "Lbl3FrgrAvlbl_4_Type_4" 5 "Lbl3FrgrAvlbl_5_Type_5" 6 "Lbl3FrgrAvlbl_6_Type_6" 7 "Lbl3FrgrAvlbl_7_Type_7" 8 "Lbl3FrgrAvlbl_8_Type_8" 9 "Lbl3FrgrAvlbl_9_Reserved" 10 "Lbl3FrgrAvlbl_10_Reserved" 11 "Lbl3FrgrAvlbl_11_Reserved" 12 "Lbl3FrgrAvlbl_12_Reserved" 13 "Lbl3FrgrAvlbl_13_Reserved" 14 "Lbl3FrgrAvlbl_14_Reserved" 15 "Lbl3FrgrAvlbl_15_Reserved" 16 "Lbl3FrgrAvlbl_16_Reserved" 17 "Lbl3FrgrAvlbl_17_Reserved" 18 "Lbl3FrgrAvlbl_18_Reserved" 19 "Lbl3FrgrAvlbl_19_Reserved" 20 "Lbl3FrgrAvlbl_20_Reserved" 21 "Lbl3FrgrAvlbl_21_Reserved" 22 "Lbl3FrgrAvlbl_22_Reserved" 23 "Lbl3FrgrAvlbl_23_Reserved" 24 "Lbl3FrgrAvlbl_24_Reserved" 25 "Lbl3FrgrAvlbl_25_Reserved" 26 "Lbl3FrgrAvlbl_26_Reserved" 27 "Lbl3FrgrAvlbl_27_Reserved" 28 "Lbl3FrgrAvlbl_28_Reserved" 29 "Lbl3FrgrAvlbl_29_Reserved" 30 "Lbl3FrgrAvlbl_30_Reserved" 31 "Lbl3FrgrAvlbl_31_Reserved" 32 "Lbl3FrgrAvlbl_32_Reserved" 33 "Lbl3FrgrAvlbl_33_Reserved" 34 "Lbl3FrgrAvlbl_34_Reserved" 35 "Lbl3FrgrAvlbl_35_Reserved" 36 "Lbl3FrgrAvlbl_36_Reserved" 37 "Lbl3FrgrAvlbl_37_Reserved" 38 "Lbl3FrgrAvlbl_38_Reserved" 39 "Lbl3FrgrAvlbl_39_Reserved" 40 "Lbl3FrgrAvlbl_40_Reserved" 41 "Lbl3FrgrAvlbl_41_Reserved" 42 "Lbl3FrgrAvlbl_42_Reserved" 43 "Lbl3FrgrAvlbl_43_Reserved" 44 "Lbl3FrgrAvlbl_44_Reserved" 45 "Lbl3FrgrAvlbl_45_Reserved" 46 "Lbl3FrgrAvlbl_46_Reserved" 47 "Lbl3FrgrAvlbl_47_Reserved" 48 "Lbl3FrgrAvlbl_48_Reserved" 49 "Lbl3FrgrAvlbl_49_Reserved" 50 "Lbl3FrgrAvlbl_50_Reserved" 51 "Lbl3FrgrAvlbl_51_Reserved" 52 "Lbl3FrgrAvlbl_52_Reserved" 53 "Lbl3FrgrAvlbl_53_Reserved" 54 "Lbl3FrgrAvlbl_54_Reserved" 55 "Lbl3FrgrAvlbl_55_Reserved" 56 "Lbl3FrgrAvlbl_56_Reserved" 57 "Lbl3FrgrAvlbl_57_Reserved" 58 "Lbl3FrgrAvlbl_58_Reserved" 59 "Lbl3FrgrAvlbl_59_Reserved" 60 "Lbl3FrgrAvlbl_60_Reserved" 61 "Lbl3FrgrAvlbl_61_Reserved" 62 "Lbl3FrgrAvlbl_62_Reserved" 63 "Lbl3FrgrAvlbl_63_Reserved" 64 "Lbl3FrgrAvlbl_64_Reserved" 65 "Lbl3FrgrAvlbl_65_Reserved" 66 "Lbl3FrgrAvlbl_66_Reserved" 67 "Lbl3FrgrAvlbl_67_Reserved" 68 "Lbl3FrgrAvlbl_68_Reserved" 69 "Lbl3FrgrAvlbl_69_Reserved" 70 "Lbl3FrgrAvlbl_70_Reserved" 71 "Lbl3FrgrAvlbl_71_Reserved" 72 "Lbl3FrgrAvlbl_72_Reserved" 73 "Lbl3FrgrAvlbl_73_Reserved" 74 "Lbl3FrgrAvlbl_74_Reserved" 75 "Lbl3FrgrAvlbl_75_Reserved" 76 "Lbl3FrgrAvlbl_76_Reserved" 77 "Lbl3FrgrAvlbl_77_Reserved" 78 "Lbl3FrgrAvlbl_78_Reserved" 79 "Lbl3FrgrAvlbl_79_Reserved" 80 "Lbl3FrgrAvlbl_80_Reserved" 81 "Lbl3FrgrAvlbl_81_Reserved" 82 "Lbl3FrgrAvlbl_82_Reserved" 83 "Lbl3FrgrAvlbl_83_Reserved" 84 "Lbl3FrgrAvlbl_84_Reserved" 85 "Lbl3FrgrAvlbl_85_Reserved" 86 "Lbl3FrgrAvlbl_86_Reserved" 87 "Lbl3FrgrAvlbl_87_Reserved" 88 "Lbl3FrgrAvlbl_88_Reserved" 89 "Lbl3FrgrAvlbl_89_Reserved" 90 "Lbl3FrgrAvlbl_90_Reserved" 91 "Lbl3FrgrAvlbl_91_Reserved" 92 "Lbl3FrgrAvlbl_92_Reserved" 93 "Lbl3FrgrAvlbl_93_Reserved" 94 "Lbl3FrgrAvlbl_94_Reserved" 95 "Lbl3FrgrAvlbl_95_Reserved" 96 "Lbl3FrgrAvlbl_96_Reserved" 97 "Lbl3FrgrAvlbl_97_Reserved" 98 "Lbl3FrgrAvlbl_98_Reserved" 99 "Lbl3FrgrAvlbl_99_Reserved" 100 "Lbl3FrgrAvlbl_100_Reserved" 101 "Lbl3FrgrAvlbl_101_Reserved" 102 "Lbl3FrgrAvlbl_102_Reserved" 103 "Lbl3FrgrAvlbl_103_Reserved" 104 "Lbl3FrgrAvlbl_104_Reserved" 105 "Lbl3FrgrAvlbl_105_Reserved" 106 "Lbl3FrgrAvlbl_106_Reserved" 107 "Lbl3FrgrAvlbl_107_Reserved" 108 "Lbl3FrgrAvlbl_108_Reserved" 109 "Lbl3FrgrAvlbl_109_Reserved" 110 "Lbl3FrgrAvlbl_110_Reserved" 111 "Lbl3FrgrAvlbl_111_Reserved" 112 "Lbl3FrgrAvlbl_112_Reserved" 113 "Lbl3FrgrAvlbl_113_Reserved" 114 "Lbl3FrgrAvlbl_114_Reserved" 115 "Lbl3FrgrAvlbl_115_Reserved" 116 "Lbl3FrgrAvlbl_116_Reserved" 117 "Lbl3FrgrAvlbl_117_Reserved" 118 "Lbl3FrgrAvlbl_118_Reserved" 119 "Lbl3FrgrAvlbl_119_Reserved" 120 "Lbl3FrgrAvlbl_120_Reserved" 121 "Lbl3FrgrAvlbl_121_Reserved" 122 "Lbl3FrgrAvlbl_122_Reserved" 123 "Lbl3FrgrAvlbl_123_Reserved" 124 "Lbl3FrgrAvlbl_124_Reserved" 125 "Lbl3FrgrAvlbl_125_Reserved" 126 "Lbl3FrgrAvlbl_126_Reserved" 127 "Lbl3FrgrAvlbl_127_Reserved" 128 "Lbl3FrgrAvlbl_128_Reserved" 129 "Lbl3FrgrAvlbl_129_Reserved" 130 "Lbl3FrgrAvlbl_130_Reserved" 131 "Lbl3FrgrAvlbl_131_Reserved" 132 "Lbl3FrgrAvlbl_132_Reserved" 133 "Lbl3FrgrAvlbl_133_Reserved" 134 "Lbl3FrgrAvlbl_134_Reserved" 135 "Lbl3FrgrAvlbl_135_Reserved" 136 "Lbl3FrgrAvlbl_136_Reserved" 137 "Lbl3FrgrAvlbl_137_Reserved" 138 "Lbl3FrgrAvlbl_138_Reserved" 139 "Lbl3FrgrAvlbl_139_Reserved" 140 "Lbl3FrgrAvlbl_140_Reserved" 141 "Lbl3FrgrAvlbl_141_Reserved" 142 "Lbl3FrgrAvlbl_142_Reserved" 143 "Lbl3FrgrAvlbl_143_Reserved" 144 "Lbl3FrgrAvlbl_144_Reserved" 145 "Lbl3FrgrAvlbl_145_Reserved" 146 "Lbl3FrgrAvlbl_146_Reserved" 147 "Lbl3FrgrAvlbl_147_Reserved" 148 "Lbl3FrgrAvlbl_148_Reserved" 149 "Lbl3FrgrAvlbl_149_Reserved" 150 "Lbl3FrgrAvlbl_150_Reserved" 151 "Lbl3FrgrAvlbl_151_Reserved" 152 "Lbl3FrgrAvlbl_152_Reserved" 153 "Lbl3FrgrAvlbl_153_Reserved" 154 "Lbl3FrgrAvlbl_154_Reserved" 155 "Lbl3FrgrAvlbl_155_Reserved" 156 "Lbl3FrgrAvlbl_156_Reserved" 157 "Lbl3FrgrAvlbl_157_Reserved" 158 "Lbl3FrgrAvlbl_158_Reserved" 159 "Lbl3FrgrAvlbl_159_Reserved" 160 "Lbl3FrgrAvlbl_160_Reserved" 161 "Lbl3FrgrAvlbl_161_Reserved" 162 "Lbl3FrgrAvlbl_162_Reserved" 163 "Lbl3FrgrAvlbl_163_Reserved" 164 "Lbl3FrgrAvlbl_164_Reserved" 165 "Lbl3FrgrAvlbl_165_Reserved" 166 "Lbl3FrgrAvlbl_166_Reserved" 167 "Lbl3FrgrAvlbl_167_Reserved" 168 "Lbl3FrgrAvlbl_168_Reserved" 169 "Lbl3FrgrAvlbl_169_Reserved" 170 "Lbl3FrgrAvlbl_170_Reserved" 171 "Lbl3FrgrAvlbl_171_Reserved" 172 "Lbl3FrgrAvlbl_172_Reserved" 173 "Lbl3FrgrAvlbl_173_Reserved" 174 "Lbl3FrgrAvlbl_174_Reserved" 175 "Lbl3FrgrAvlbl_175_Reserved" 176 "Lbl3FrgrAvlbl_176_Reserved" 177 "Lbl3FrgrAvlbl_177_Reserved" 178 "Lbl3FrgrAvlbl_178_Reserved" 179 "Lbl3FrgrAvlbl_179_Reserved" 180 "Lbl3FrgrAvlbl_180_Reserved" 181 "Lbl3FrgrAvlbl_181_Reserved" 182 "Lbl3FrgrAvlbl_182_Reserved" 183 "Lbl3FrgrAvlbl_183_Reserved" 184 "Lbl3FrgrAvlbl_184_Reserved" 185 "Lbl3FrgrAvlbl_185_Reserved" 186 "Lbl3FrgrAvlbl_186_Reserved" 187 "Lbl3FrgrAvlbl_187_Reserved" 188 "Lbl3FrgrAvlbl_188_Reserved" 189 "Lbl3FrgrAvlbl_189_Reserved" 190 "Lbl3FrgrAvlbl_190_Reserved" 191 "Lbl3FrgrAvlbl_191_Reserved" 192 "Lbl3FrgrAvlbl_192_Reserved" 193 "Lbl3FrgrAvlbl_193_Reserved" 194 "Lbl3FrgrAvlbl_194_Reserved" 195 "Lbl3FrgrAvlbl_195_Reserved" 196 "Lbl3FrgrAvlbl_196_Reserved" 197 "Lbl3FrgrAvlbl_197_Reserved" 198 "Lbl3FrgrAvlbl_198_Reserved" 199 "Lbl3FrgrAvlbl_199_Reserved" 200 "Lbl3FrgrAvlbl_200_Reserved" 201 "Lbl3FrgrAvlbl_201_Reserved" 202 "Lbl3FrgrAvlbl_202_Reserved" 203 "Lbl3FrgrAvlbl_203_Reserved" 204 "Lbl3FrgrAvlbl_204_Reserved" 205 "Lbl3FrgrAvlbl_205_Reserved" 206 "Lbl3FrgrAvlbl_206_Reserved" 207 "Lbl3FrgrAvlbl_207_Reserved" 208 "Lbl3FrgrAvlbl_208_Reserved" 209 "Lbl3FrgrAvlbl_209_Reserved" 210 "Lbl3FrgrAvlbl_210_Reserved" 211 "Lbl3FrgrAvlbl_211_Reserved" 212 "Lbl3FrgrAvlbl_212_Reserved" 213 "Lbl3FrgrAvlbl_213_Reserved" 214 "Lbl3FrgrAvlbl_214_Reserved" 215 "Lbl3FrgrAvlbl_215_Reserved" 216 "Lbl3FrgrAvlbl_216_Reserved" 217 "Lbl3FrgrAvlbl_217_Reserved" 218 "Lbl3FrgrAvlbl_218_Reserved" 219 "Lbl3FrgrAvlbl_219_Reserved" 220 "Lbl3FrgrAvlbl_220_Reserved" 221 "Lbl3FrgrAvlbl_221_Reserved" 222 "Lbl3FrgrAvlbl_222_Reserved" 223 "Lbl3FrgrAvlbl_223_Reserved" 224 "Lbl3FrgrAvlbl_224_Reserved" 225 "Lbl3FrgrAvlbl_225_Reserved" 226 "Lbl3FrgrAvlbl_226_Reserved" 227 "Lbl3FrgrAvlbl_227_Reserved" 228 "Lbl3FrgrAvlbl_228_Reserved" 229 "Lbl3FrgrAvlbl_229_Reserved" 230 "Lbl3FrgrAvlbl_230_Reserved" 231 "Lbl3FrgrAvlbl_231_Reserved" 232 "Lbl3FrgrAvlbl_232_Reserved" 233 "Lbl3FrgrAvlbl_233_Reserved" 234 "Lbl3FrgrAvlbl_234_Reserved" 235 "Lbl3FrgrAvlbl_235_Reserved" 236 "Lbl3FrgrAvlbl_236_Reserved" 237 "Lbl3FrgrAvlbl_237_Reserved" 238 "Lbl3FrgrAvlbl_238_Reserved" 239 "Lbl3FrgrAvlbl_239_Reserved" 240 "Lbl3FrgrAvlbl_240_Reserved" 241 "Lbl3FrgrAvlbl_241_Reserved" 242 "Lbl3FrgrAvlbl_242_Reserved" 243 "Lbl3FrgrAvlbl_243_Reserved" 244 "Lbl3FrgrAvlbl_244_Reserved" 245 "Lbl3FrgrAvlbl_245_Reserved" 246 "Lbl3FrgrAvlbl_246_Reserved" 247 "Lbl3FrgrAvlbl_247_Reserved" 248 "Lbl3FrgrAvlbl_248_Reserved" 249 "Lbl3FrgrAvlbl_249_Reserved" 250 "Lbl3FrgrAvlbl_250_Reserved" 251 "Lbl3FrgrAvlbl_251_Reserved" 252 "Lbl3FrgrAvlbl_252_Reserved" 253 "Lbl3FrgrAvlbl_253_Reserved" 254 "Lbl3FrgrAvlbl_254_Reserved" 255 "Lbl3FrgrAvlbl_255_Reserved";
VAL_ 902 IFrgrLblReqRut 0 "FrgrLblReqRut_0_NoRequset" 1 "FrgrLblReqRut_1_Label1" 2 "FrgrLblReqRut_2_Label2" 3 "FrgrLblReqRut_3_Label3" 4 "FrgrLblReqRut_4_Label1_mix_Label2_And_Lable_1_Is_More" 5 "FrgrLblReqRut_5_Label1_mix_Label2_And_Lable_2_Is_More" 6 "FrgrLblReqRut_6_Label1_mix_Label2_And_Lable_1_Is_Same_as_Label2" 7 "FrgrLblReqRut_7_Label1_mix_Label3_And_Lable_1_Is_More" 8 "FrgrLblReqRut_8_Label1_mix_Label3_And_Lable_3_Is_More" 9 "FrgrLblReqRut_9_Label1_mix_Label3_And_Lable_1_Is_Same_as_Label_3" 10 "FrgrLblReqRut_10_Label2_mix_Label3_And_Lable_2_Is_More" 11 "FrgrLblReqRut_11_Label2_mix_Label3_And_Lable_3_Is_More" 12 "FrgrLblReqRut_12_Label2_mix_Label3_And_Lable_2_Is_Same_as_Label3" 15 "FrgrLblReqRut_15_Stop_Fragrance";
VAL_ 902 IAdupConSwReq 0 "AdupConSwReq_0_NoRequest" 1 "AdupConSwReq_1_confirm" 2 "AdupConSwReq_2_cancel" 3 "AdupConSwReq_3_Reserved";
VAL_ 902 IAdupSwReq 0 "AdupSwReq_0_NoRequest" 1 "AdupSwReq_1_start" 2 "AdupSwReq_2_finish" 3 "AdupSwReq_3_Reserved";
VAL_ 902 IRBFSwReq 0 "RBFSwReq_0_NoRequest" 1 "RBFSwReq_1_off" 2 "RBFSwReq_2_on" 3 "RBFSwReq_3_Reserved";
VAL_ 902 IRCWSnstvtLvlReq 0 "RCWSnstvtLvlReq_0_NoRequest" 1 "RCWSnstvtLvlReq_1_level1_low" 2 "RCWSnstvtLvlReq_2_level2_middle" 3 "RCWSnstvtLvlReq_3_level3_high";
VAL_ 902 ISpdLmtCotOverWrnngSwReq 0 "SpdLmtCotOverWrnngSwReq_0_NoRequest" 1 "SpdLmtCotOverWrnngSwReq_1_ON" 2 "SpdLmtCotOverWrnngSwReq_2_OFF" 3 "SpdLmtCotOverWrnngSwReq_3_Reserved";
VAL_ 902 ITollgatePreReq 0 "TollgatePreReq_0_no_request" 1 "TollgatePreReq_1_Manual" 2 "TollgatePreReq_2_ETC" 3 "TollgatePreReq_3_Reserved";
VAL_ 902 IHODMdlReq 0 "HODMdlReq_0_No_Request" 1 "HODMdlReq_1_Standard" 2 "HODMdlReq_2_Comfortable" 3 "HODMdlReq_3_Reserved";
VAL_ 902 IMemParkngSilentPatrolSwReq 0 "MemParkngSilentPatrolSwReq_0_NoRequest" 1 "MemParkngSilentPatrolSwReq_1_ON" 2 "MemParkngSilentPatrolSwReq_2_OFF";
VAL_ 902 IIPDPowerFailSwReq 0 "IPDPowerFailSwReq_0_NoRequest" 1 "IPDPowerFailSwReq_1_off" 2 "IPDPowerFailSwReq_2_on" 3 "IPDPowerFailSwReq_3_LowPwrMd";
VAL_ 902 IAVPUpdateMapReq 0 "AVPUpdateMapReq_0_No_request" 1 "AVPUpdateMapReq_1_Request" 2 "AVPUpdateMapReq_2_Cancel" 3 "AVPUpdateMapReq_3_reserved";
VAL_ 902 IAVPMapRutMgtReq 0 "AVPMapRutMgtReq_0_Idle" 1 "AVPMapRutMgtReq_1_Press" 2 "AVPMapRutMgtReq_2_Error" 3 "AVPMapRutMgtReq_3_Reserved1";
VAL_ 902 IAIPilotMdlReq 0 "AIPilotMdlReq_0_NoRequest" 1 "AIPilotMdlReq_1_SuperPilot" 2 "AIPilotMdlReq_2_SuperPilot_off" 3 "AIPilotMdlReq_3_Reserved";
VAL_ 902 ILbl1FrgrExpiryFlg 0 "Lbl1FrgrExpiryFlg_0_OK" 1 "Lbl1FrgrExpiryFlg_1_Expiry";
VAL_ 902 IRPAActMethSwReq 0 "RPAActMethSwReq_0_NoRequest" 1 "RPAActMethSwReq_1_quick" 2 "RPAActMethSwReq_2_lock" 3 "RPAActMethSwReq_3_Reserved";
VAL_ 902 IUsPrReportReq 0 "UsPrReportReq_0__NoRequest" 1 "UsPrReportReq_1_OFF" 2 "UsPrReportReq_2_ON" 3 "UsPrReportReq_3_Reserved";
VAL_ 902 IRACtlReq 0 "RACtlReq_0_NoRequest" 1 "RACtlReq_1_Entry" 2 "RACtlReq_2_Start" 3 "RACtlReq_3_Pause" 4 "RACtlReq_4_Continue" 5 "RACtlReq_5_Exit" 6 "RACtlReq_6_Reserved6" 7 "RACtlReq_7_Reserved7";
VAL_ 902 IDriverSightDstrctnMonWarning 0 "DriverSightDstrctnWarning_0_NoWarning" 1 "DriverSightDstrctnWarning_1_WarningLvl_1" 2 "DriverSightDstrctnWarning_2_WarningLvl_2" 3 "DriverSightDstrctnWarning_3_WarningLvl_3" 4 "DriverSightDstrctnWarning_4_WarningLvl_4" 5 "DriverSightDstrctnWarning_5_WarningLvl_5" 6 "DriverSightDstrctnWarning_6_WarningLvl_6" 7 "DriverSightDstrctnWarning_7_WarningLvl_7" 8 "DriverSightDstrctnWarning_8_WarningLvl_8" 9 "DriverSightDstrctnWarning_9_WarningLvl_9" 10 "DriverSightDstrctnMonWarning_10_Reserved" 11 "DriverSightDstrctnMonWarning_11_Reserved" 12 "DriverSightDstrctnMonWarning_12_Reserved" 13 "DriverSightDstrctnMonWarning_13_Reserved" 14 "DriverSightDstrctnMonWarning_14_Reserved" 15 "DriverSightDstrctnMonWarning_15_Reserved";
VAL_ 902 IFatigueMonitorWarning 0 "DriverFtgWarning_0_NoWarning" 1 "DriverFtgWarning_1_WarningLvl_1" 2 "DriverFtgWarning_2_WarningLvl_2" 3 "DriverFtgWarning_3_WarningLvl_3" 4 "DriverFtgWarning_4_WarningLvl_4" 5 "DriverFtgWarning_5_WarningLvl_5" 6 "DriverFtgWarning_6_WarningLvl_6" 7 "DriverFtgWarning_7_WarningLvl_7" 8 "DriverFtgWarning_8_WarningLvl_8" 9 "DriverFtgWarning_9_WarningLvl_9" 10 "FatigueMonitorWarning_10_Reserved" 11 "FatigueMonitorWarning_11_Reserved" 12 "FatigueMonitorWarning_12_Reserved" 13 "FatigueMonitorWarning_13_Reserved" 14 "FatigueMonitorWarning_14_Reserved" 15 "FatigueMonitorWarning_15_Reserved";
VAL_ 902 IFrgrCncntrnReqRut 0 "FrgrCncntrnReqRut_0_NoRequset" 1 "FrgrCncntrnReqRut_1_Intermittent_Level1" 2 "FrgrCncntrnReqRut_2_Intermittent_Level2" 3 "FrgrCncntrnReqRut_3_Intermittent_Level3" 4 "FrgrCncntrnReqRut_4_Intermittent_Level4" 5 "FrgrCncntrnReqRut_5_Intermittent_Level5" 6 "FrgrCncntrnReqRut_6_Continued_Level1" 7 "FrgrCncntrnReqRut_7_Continued_Level2" 8 "FrgrCncntrnReqRut_8_Continued_Level3" 9 "FrgrCncntrnReqRut_9_Continued_Level4" 10 "FrgrCncntrnReqRut_10_Continued_Level5";
VAL_ 902 IShwrmComprEnbReq 0 "ShwrmComprEnbReq__0_No_Request" 1 "ShwrmComprEnbReq__1_Enable_Request";
VAL_ 902 ILbl3FrgrExpiryFlg 0 "Lbl3FrgrExpiryFlg_0_OK" 1 "Lbl3FrgrExpiryFlg_1_Expiry";
VAL_ 902 ILbl2FrgrExpiryFlg 0 "Lbl2FrgrExpiryFlg_0_OK" 1 "Lbl2FrgrExpiryFlg_1_Expiry";
VAL_ 902 ISrfOpenSts 0 "SrfOpenSts_0_Fully_Close" 1 "SrfOpenSts_1_Tilt_Open" 2 "SrfOpenSts_2_Slide_Open_not_fully" 3 "SrfOpenSts_3_Fully_Open" 4 "SrfOpenSts_4_Unknown";
VAL_ 955 IACCTJAMdSwReq 0 "ACCTJAMdSwReq_0_NoRequest" 1 "ACCTJAMdSwReq_1_ACC" 2 "ACCTJAMdSwReq_2_TJA" 3 "ACCTJAMdSwReq_3_SHWA" 4 "ACCTJAMdSwReq_4_Off" 5 "ACCTJAMdSwReq_5_Reserved" 6 "ACCTJAMdSwReq_6_Reserved" 7 "ACCTJAMdSwReq_7_Reserved";
VAL_ 955 IFICMACLTemReq 0 "FICMACLTemReq_0_Lo" 30 "FICMACLTemReq_30_High" 31 "FICMACLTemReq_31_Reserved";
VAL_ 955 IACCStsSwReq 0 "ACCStsSwReq_0_NoRequest" 1 "ACCStsSwReq_1_Off" 2 "ACCStsSwReq_2_On" 3 "ACCStsSwReq_3_Reserve";
VAL_ 955 IACCSpdLimtSwReq 0 "ACCSpdLimtSwReq_0_NoRequest" 1 "ACCSpdLimtSwReq_1_manual" 2 "ACCSpdLimtSwReq_2_Auto" 3 "ACCSpdLimtSwReq_3_OFF";
VAL_ 955 IACCConfmSwReq 0 "ACCConfmSwReq_0_NoRequest" 1 "ACCConfmSwReq_1_NoConfirm" 2 "ACCConfmSwReq_2_Confirm" 3 "ACCConfmSwReq_3_Reserve";
VAL_ 955 IACUserCustEcoSetngReqV 0 "ACUserCustEcoSetngReqV_0_Valid" 1 "ACUserCustEcoSetngReqV_1_Invalid";
VAL_ 955 IACUserCustEcoSetngReq 0 "ACUserCustEcoSetngReq_0_Unavailable" 1 "ACUserCustEcoSetngReq_1_Economy_Mode" 2 "ACUserCustEcoSetngReq_2_Normal_Mode" 3 "ACUserCustEcoSetngReq_3_Reserved";
VAL_ 955 IACUserCustAutoMdBlwrReqV 0 "ACUserCustAutoMdBlwrReqV_0_Valid" 1 "ACUserCustAutoMdBlwrReqV_1_Invalid";
VAL_ 955 IACUserCustAutoMdBlwrReq 0 "ACUserCustAutoMdBlwrReq_0_High_level" 1 "ACUserCustAutoMdBlwrReq_1_Middle_level" 2 "ACUserCustAutoMdBlwrReq_2_Low_level" 3 "ACUserCustAutoMdBlwrReq_3_Reserved";
VAL_ 955 IACUserCustAftRunOnOffReqV 0 "ACUserCustAftRunOnOffReqV_0_Vaild" 1 "ACUserCustAftRunOnOffReqV_1_Invaild";
VAL_ 955 IACUserCustAftRunOnOffR 0 "ACUserCustAftRunOnOffR_0_Off" 1 "ACUserCustAftRunOnOffR_1_On";
VAL_ 955 IFICMACFrtBlwrSpdDecSwR 0 "FICMACFrtBlwrSpdDecSwR_0_No_request" 1 "FICMACFrtBlwrSpdDecSwR_1_Short_press" 2 "FICMACFrtBlwrSpdDecSwR_2_Long_press";
VAL_ 955 IFICMACAutoSwReq 0 "FICMACAutoSwReq_0_No_request" 1 "FICMACAutoSwReq_1_Short_press" 2 "FICMACAutoSwReq_2_Long_press";
VAL_ 955 IFICMACLTemDecSwReq 0 "FICMACLTemDecSwReq_0_No_request" 1 "FICMACLTemDecSwReq_1_Short_press" 2 "FICMACLTemDecSwReq_2_Long_press";
VAL_ 955 IFICMACFrtBlwrSpdIncSwR 0 "FICMACFrtBlwrSpdIncSwR_0_No_request" 1 "FICMACFrtBlwrSpdIncSwR_1_Short_press" 2 "FICMACFrtBlwrSpdIncSwR_2_Long_press";
VAL_ 955 IFICMACFrtBlwrLvlReq 0 "FICMACFrtBlwrLvlReq_0_Blower_Off" 1 "FICMACFrtBlwrLvlReq_1_Blower_level_1" 2 "FICMACFrtBlwrLvlReq_2_Blower_level_2" 3 "FICMACFrtBlwrLvlReq_3_Blower_level_3" 4 "FICMACFrtBlwrLvlReq_4_Blower_level_4" 5 "FICMACFrtBlwrLvlReq_5_Blower_level_5" 6 "FICMACFrtBlwrLvlReq_6_Blower_level_6" 7 "FICMACFrtBlwrLvlReq_7_Blower_level_7" 8 "FICMACFrtBlwrLvlReq_8_Blower_level_8" 9 "FICMACFrtBlwrLvlReq_9_Blower_level_9" 10 "FICMACFrtBlwrLvlReq_10_Blower_level_10" 11 "FICMACFrtBlwrLvlReq_11_Blower_level_11" 12 "FICMACFrtBlwrLvlReq_12_Blower_level_12" 13 "FICMACFrtBlwrLvlReq_13_Blower_level_13" 14 "FICMACFrtBlwrLvlReq_14_Blower_level_14" 15 "FICMACFrtBlwrLvlReq_15_Blower_level_15";
VAL_ 955 IFICMACOnOffSwReq 0 "FICMACOnOffSwReq_0_No_request" 1 "FICMACOnOffSwReq_1_Short_press" 2 "FICMACOnOffSwReq_2_Long_press";
VAL_ 955 IFICMACLTemIncSwReq 0 "FICMACLTemIncSwReq_0_No_request" 1 "FICMACLTemIncSwReq_1_Short_press" 2 "FICMACLTemIncSwReq_2_Long_press";
VAL_ 955 IFICMACLAirMdReqV 0 "FICMACLAirMdReqV_0_Valid" 1 "FICMACLAirMdReqV_1_Invalid";
VAL_ 955 IFICMACLAirMdReq 0 "FICMACLAirMdReq_0_face" 1 "FICMACLAirMdReq_1_face_foot" 2 "FICMACLAirMdReq_2_foot" 3 "FICMACLAirMdReq_3_foot_defrost" 4 "FICMACLAirMdReq_4_defrost" 5 "FICMACLAirMdReq_5_face_foot_defrost" 6 "FICMACLAirMdReq_6_face_defrost" 7 "FICMACLAirMdReq_7_No_Command_air_distribute_mode";
VAL_ 955 IFICMComprOnOffSwReq 0 "FICMComprOnOffSwReq_0_No_request" 1 "FICMComprOnOffSwReq_1_Short_press" 2 "FICMComprOnOffSwReq_2_Long_press";
VAL_ 955 IFICMACSemiAutoSwReq 0 "FICMACSemiAutoSwReq_0_No_request" 1 "FICMACSemiAutoSwReq_1_Short_press" 2 "FICMACSemiAutoSwReq_2_Long_press" 3 "FICMACSemiAutoSwReq_3_Reserved";
VAL_ 955 IFICMACRcctnSwReq 0 "FICMACRcctnSwReq_0_No_request" 1 "FICMACRcctnSwReq_1_Short_press" 2 "FICMACRcctnSwReq_2_Long_press";
VAL_ 955 IFICMACRcctnMdReq 0 "FICMACRcctnMdReq_0_Reserved" 1 "FICMACRcctnMdReq_1_Fresh" 2 "FICMACRcctnMdReq_2_Auto_recirculation" 3 "FICMACRcctnMdReq_3_Recirculation";
VAL_ 955 IFICMHtdRrWndSwReq 0 "FICMHtdRrWndSwReq_0_No_request" 1 "FICMHtdRrWndSwReq_1_Short_press" 2 "FICMHtdRrWndSwReq_2_Long_press";
VAL_ 955 IFICMDfstOnSwReq 0 "FICMDfstOnSwReq_0_No_request" 1 "FICMDfstOnSwReq_1_Short_press" 2 "FICMDfstOnSwReq_2_Long_press";
VAL_ 955 IFICMACLTemV 0 "FICMACLTemV_0_Valid" 1 "FICMACLTemV_1_Invalid";
VAL_ 955 ITLRMdSwReq 0 "TLRMdSwReq_0_NoRequest" 1 "TLRMdSwReq_1_TLR_on" 2 "TLRMdSwReq_2_TLR_off" 3 "TLRMdSwReq_3_TLR_alert_on" 4 "TLRMdSwReq_4_TLR_alert_off" 5 "TLRMdSwReq_5_Reserved" 6 "TLRMdSwReq_6_Reserved";
VAL_ 955 ITSRSwReq 0 "TSRSwReq_0_no_request" 1 "TSRSwReq_1_Off" 2 "TSRSwReq_2_On";
VAL_ 955 ISpdLmtOfstSetNumReq 0 "SpdLmtOfstSetNumReq_0_NoRequest" 1 "SpdLmtOfstSetNumReq_1_0_km_h" 2 "SpdLmtOfstSetNumReq_2_5_km_h" 3 "SpdLmtOfstSetNumReq_3_10_km_h" 4 "SpdLmtOfstSetNumReq_4_15_km_h" 5 "SpdLmtOfstSetNumReq_5_20_km_h" 6 "SpdLmtOfstSetNumReq_6__5_km_h" 7 "SpdLmtOfstSetNumReq_7__10_km_h" 8 "SpdLmtOfstSetNumReq_8__15_km_h" 9 "SpdLmtOfstSetNumReq_9__20_km_h" 10 "SpdLmtOfstSetNumReq_10_reserved" 11 "SpdLmtOfstSetNumReq_11_reserved" 12 "SpdLmtOfstSetNumReq_12_reserved" 13 "SpdLmtOfstSetNumReq_13_reserved" 14 "SpdLmtOfstSetNumReq_14_reserved";
VAL_ 955 IILCSwReq 0 "ILCSwReq_0_NoRequest" 1 "ILCSwReq_1_off" 2 "ILCSwReq_2_on" 3 "ILCSwReq_3_reserved";
VAL_ 955 ISpdLmtOfstSetPercReq 0 "SpdLmtOfstSetPercReq_0_NoRequest" 1 "SpdLmtOfstSetPercReq_1_0" 2 "SpdLmtOfstSetPercReq_2_5" 3 "SpdLmtOfstSetPercReq_3_10" 4 "SpdLmtOfstSetPercReq_4_20" 5 "SpdLmtOfstSetPercReq_5__5" 6 "SpdLmtOfstSetPercReq_6__10" 7 "SpdLmtOfstSetPercReq_7__20";
SIG_GROUP_ 907 IICBVC_100ms_Group80 1 : IFrtPsngAirbagSwStsReqV_Sfty IFrtPsngAirbagSwStsReq_Sfty IICBVC_100ms_Group80_CRC IICBVC_100ms_Group80_RC IICBVC_100ms_Group80_Reserved1 IICBVC_100ms_Group80_Reserved2 IICBVC_100ms_Group80_Reserved3 IVehDrvngMd IVehLdShedLvl IVehOdo IVehOdoV;
SIG_GROUP_ 497 IICBVC_20ms_Group03 1 : IAMRPrtensonReq IBPMMstrAvlbly IICBVC_20ms_Group03_CRC IICBVC_20ms_Group03_RC IICBVC_20ms_Group03_Reserved1 IICBVC_20ms_Group03_Reserved2 IICBVC_20ms_Group03_Reserved3 IICBVC_20ms_Group03_Reserved4 IPwrMdMstrAccryA IPwrMdMstrRunCrkA ISysOpnlMd ISysPwrMd ISysPwrMdV ISysVol ISysVolMd ISysVolMdV ISysVolV IUsgMd IUsgMdV IVehMd IVehMdV;
